VERSION "HNPBNNNYNNNNNNNNNNNNNNNNNNNNNNNNYNYYYYYYYY>4>%%%/4>'%**4YYY///"

NS_ :

BS_:

BU_: RDF2 Air Vehicle_CAN MPC2

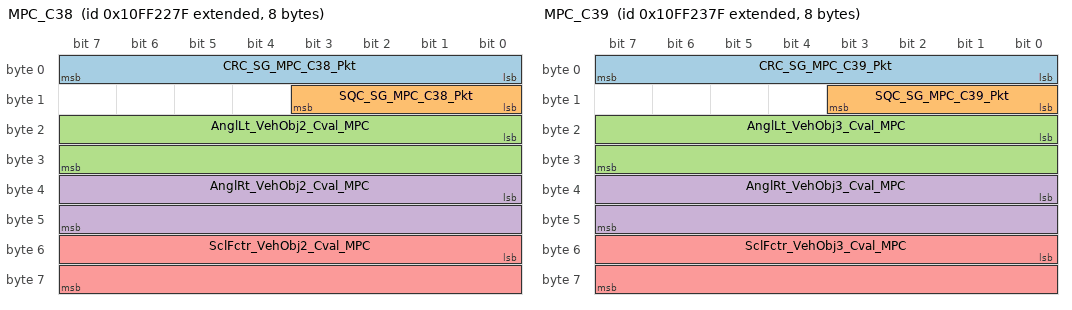
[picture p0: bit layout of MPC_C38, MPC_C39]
BO_ 2432639615 MPC_C38: 8 MPC2
 SG_ CRC_SG_MPC_C38_Pkt : 0|8@1+ (1,0) [0|255] "NoUnit" Vector__XXX
 SG_ SQC_SG_MPC_C38_Pkt : 8|4@1+ (1,0) [0|15] "NoUnit" Vector__XXX
 SG_ AnglLt_VehObj2_Cval_MPC : 16|16@1+ (0.00390625,-125) [-125|125] "°" Vector__XXX
 SG_ AnglRt_VehObj2_Cval_MPC : 32|16@1+ (0.00390625,-125) [-125|125] "°" Vector__XXX
 SG_ SclFctr_VehObj2_Cval_MPC : 48|16@1+ (6.25E-005,0.5) [0.5|4.5] "NoUnit" Vector__XXX

BO_ 2432639871 MPC_C39: 8 MPC2
 SG_ CRC_SG_MPC_C39_Pkt : 0|8@1+ (1,0) [0|255] "NoUnit" Vector__XXX
 SG_ SQC_SG_MPC_C39_Pkt : 8|4@1+ (1,0) [0|15] "NoUnit" Vector__XXX
 SG_ AnglLt_VehObj3_Cval_MPC : 16|16@1+ (0.00390625,-125) [-125|125] "°" Vector__XXX
 SG_ AnglRt_VehObj3_Cval_MPC : 32|16@1+ (0.00390625,-125) [-125|125] "°" Vector__XXX
 SG_ SclFctr_VehObj3_Cval_MPC : 48|16@1+ (6.25E-005,0.5) [0.5|4.5] "NoUnit" Vector__XXX

BO_ 2498756875 EBC1_BS: 8 Vehicle_CAN
 SG_ ABS_Actv_Stat : 4|2@1+ (1,0) [0|3] ""  MPC2
 SG_ BrkPdlPosn_Cval : 8|8@1+ (0.4,0) [0|100] "%"  MPC2

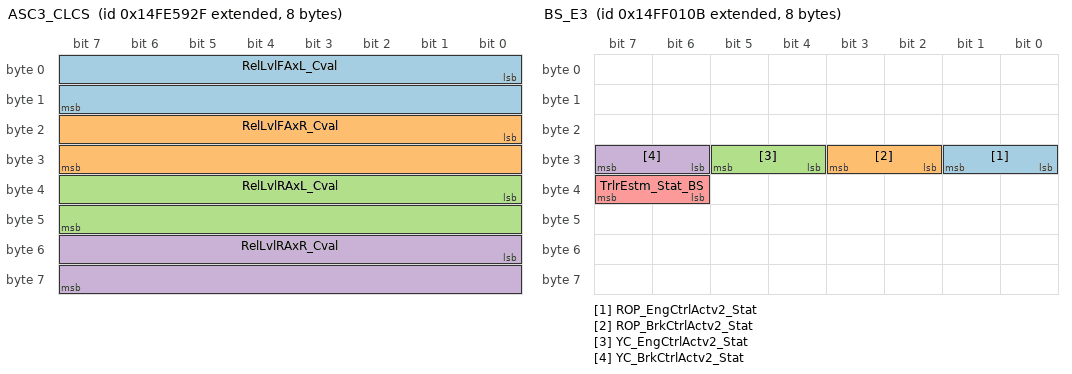
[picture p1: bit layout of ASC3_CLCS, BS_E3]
BO_ 2499696943 ASC3_CLCS: 8 Vehicle_CAN
 SG_ RelLvlFAxL_Cval : 0|16@1+ (0.1,-3200) [-3200|3225.5] "mm"  MPC2
 SG_ RelLvlFAxR_Cval : 16|16@1+ (0.1,-3200) [-3200|3225.5] "mm"  MPC2
 SG_ RelLvlRAxL_Cval : 32|16@1+ (0.1,-3200) [-3200|3225.5] "mm"  MPC2
 SG_ RelLvlRAxR_Cval : 48|16@1+ (0.1,-3200) [-3200|3225.5] "mm"  MPC2

BO_ 2499702539 ACC1_BS: 8 Vehicle_CAN
 SG_ RoadCurv_Cval : 32|16@1+ (0.0078125,-250) [-250|251.9921875] "1/km"  MPC2

BO_ 2499735808 CCVS1_CPC: 8 Vehicle_CAN
 SG_ VehSpd_Cval_CPC : 8|16@1+ (0.00390625,0) [0|250.99609375] "km/h"  MPC2
 SG_ CC_Actv_Stat : 24|2@1+ (1,0) [0|3] ""  MPC2

BO_ 2499739775 MPC_C02: 8 MPC2
 SG_ Rsrv_CRC_SG_MPC_C02_Pkt : 0|8@1+ (1,0) [0|255] "NoUnit" Vector__XXX
 SG_ Rsrv_SQC_SG_MPC_C02_Pkt : 8|4@1+ (1,0) [0|15] "NoUnit" Vector__XXX
 SG_ DispCloAA_Rq_MPC : 12|2@1+ (1,0) [0|3] "" Vector__XXX
 SG_ Lvl0_AA_Cval_MPC : 16|4@1+ (1,0) [0|15] "count(s)" Vector__XXX
 SG_ Lvl1_AA_Cval_MPC : 20|4@1+ (1,0) [0|15] "count(s)" Vector__XXX
 SG_ Lvl2_AA_Cval_MPC : 24|4@1+ (1,0) [0|15] "count(s)" Vector__XXX
 SG_ Lvl3_AA_Cval_MPC : 28|4@1+ (1,0) [0|15] "count(s)" Vector__XXX
 SG_ Lvl4_AA_Cval_MPC : 32|4@1+ (1,0) [0|15] "count(s)" Vector__XXX
 SG_ Lvl5_AA_Cval_MPC : 36|4@1+ (1,0) [0|15] "count(s)" Vector__XXX
 SG_ Lvl6_AA_Cval_MPC : 40|4@1+ (1,0) [0|15] "count(s)" Vector__XXX
 SG_ Lvl7_AA_Cval_MPC : 44|4@1+ (1,0) [0|15] "count(s)" Vector__XXX
 SG_ Lvl8_AA_Cval_MPC : 48|4@1+ (1,0) [0|15] "count(s)" Vector__XXX
 SG_ Lvl9_AA_Cval_MPC : 52|4@1+ (1,0) [0|15] "count(s)" Vector__XXX
 SG_ AA_Enbl_Stat_MPC : 56|2@1+ (1,0) [0|3] "" Vector__XXX
 SG_ AA_Fkt_Stat_MPC : 58|2@1+ (1,0) [0|3] "" Vector__XXX
 SG_ Warn0_AA_Rq_MPC : 60|2@1+ (1,0) [0|3] "" Vector__XXX
 SG_ Warn1_AA_Rq_MPC : 62|2@1+ (1,0) [0|3] "" Vector__XXX

BO_ 2499739915 BS_E3: 8 Vehicle_CAN
 SG_ ROP_EngCtrlActv2_Stat : 24|2@1+ (1,0) [0|3] ""  MPC2
 SG_ ROP_BrkCtrlActv2_Stat : 26|2@1+ (1,0) [0|3] ""  MPC2
 SG_ YC_EngCtrlActv2_Stat : 28|2@1+ (1,0) [0|3] ""  MPC2
 SG_ YC_BrkCtrlActv2_Stat : 30|2@1+ (1,0) [0|3] ""  MPC2
 SG_ TrlrEstm_Stat_BS : 38|2@1+ (1,0) [0|3] ""  MPC2

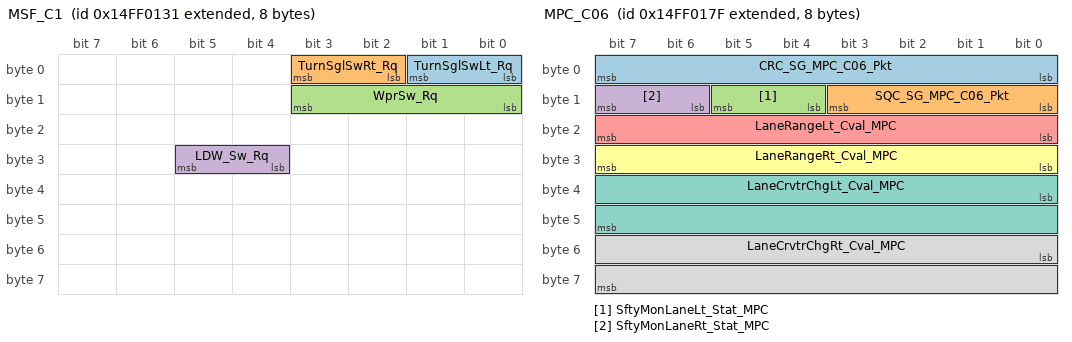
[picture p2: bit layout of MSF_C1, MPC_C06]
BO_ 2499739953 MSF_C1: 8 Vehicle_CAN
 SG_ TurnSglSwLt_Rq : 0|2@1+ (1,0) [0|3] ""  MPC2
 SG_ TurnSglSwRt_Rq : 2|2@1+ (1,0) [0|3] ""  MPC2
 SG_ WprSw_Rq : 8|4@1+ (1,0) [0|15] ""  MPC2
 SG_ LDW_Sw_Rq : 28|2@1+ (1,0) [0|3] ""  MPC2

BO_ 2499740031 MPC_C06: 8 MPC2
 SG_ CRC_SG_MPC_C06_Pkt : 0|8@1+ (1,0) [0|255] "NoUnit" Vector__XXX
 SG_ SQC_SG_MPC_C06_Pkt : 8|4@1+ (1,0) [0|15] "NoUnit" Vector__XXX
 SG_ SftyMonLaneLt_Stat_MPC : 12|2@1+ (1,0) [0|3] "" Vector__XXX
 SG_ SftyMonLaneRt_Stat_MPC : 14|2@1+ (1,0) [0|3] "" Vector__XXX
 SG_ LaneRangeLt_Cval_MPC : 16|8@1+ (0.5,0) [0|125] "m" Vector__XXX
 SG_ LaneRangeRt_Cval_MPC : 24|8@1+ (0.5,0) [0|125] "m" Vector__XXX
 SG_ LaneCrvtrChgLt_Cval_MPC : 32|16@1+ (0.0625,-2000) [-2000|2000] "1/km²" Vector__XXX
 SG_ LaneCrvtrChgRt_Cval_MPC : 48|16@1+ (0.0625,-2000) [-2000|2000] "1/km²" Vector__XXX

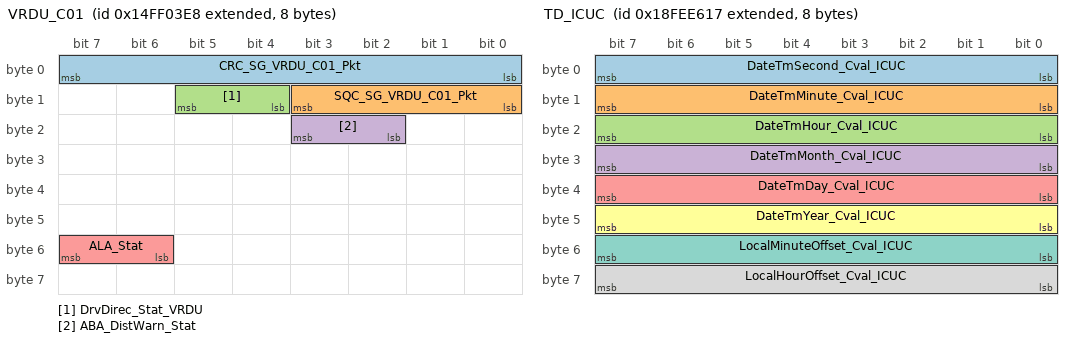
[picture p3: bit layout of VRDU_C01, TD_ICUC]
BO_ 2499740648 VRDU_C01: 8 Vehicle_CAN
 SG_ CRC_SG_VRDU_C01_Pkt : 0|8@1+ (1,0) [0|255] "NoUnit"  MPC2
 SG_ SQC_SG_VRDU_C01_Pkt : 8|4@1+ (1,0) [0|15] "NoUnit"  MPC2
 SG_ DrvDirec_Stat_VRDU : 12|2@1+ (1,0) [0|3] ""  MPC2
 SG_ ABA_DistWarn_Stat : 18|2@1+ (1,0) [0|3] ""  MPC2
 SG_ ALA_Stat : 54|2@1+ (1,0) [0|3] ""  MPC2

BO_ 2499740904 VRDU_C02: 8 Vehicle_CAN
 SG_ WhlBaseTrtr_Cval : 16|8@1+ (0.1,0) [0|25] "m"  MPC2

BO_ 2499742976 CPC3_E2: 8 Vehicle_CAN
 SG_ RetSwPos_Rq_STSR : 32|8@1+ (1,0) [0|255] ""  MPC2

BO_ 2565832698 APPL_SG_MPC: 8 Vehicle_CAN
 SG_ APPL_SG_MPC : 0|64@1+ (1,0) [0|0] ""  MPC2

BO_ 2565864063 SG_APPL_MPC: 8 MPC2
 SG_ SG_APPL_MPC : 0|64@1+ (1,0) [0|0] "" Vector__XXX

BO_ 2566809216 BM_BESO: 8 Vehicle_CAN
 SG_ BatMainSw_Stat : 0|2@1+ (1,0) [0|3] ""  MPC2

BO_ 2566841879 TD_ICUC: 8 Vehicle_CAN
 SG_ DateTmSecond_Cval_ICUC : 0|8@1+ (0.25,0) [0|59.75] "s"  MPC2
 SG_ DateTmMinute_Cval_ICUC : 8|8@1+ (1,0) [0|59] "min"  MPC2
 SG_ DateTmHour_Cval_ICUC : 16|8@1+ (1,0) [0|250] "h"  MPC2
 SG_ DateTmMonth_Cval_ICUC : 24|8@1+ (1,0) [1|12] "Months"  MPC2
 SG_ DateTmDay_Cval_ICUC : 32|8@1+ (0.25,0) [0.25|31.75] "Days"  MPC2
 SG_ DateTmYear_Cval_ICUC : 40|8@1+ (1,1985) [1985|2235] "Years"  MPC2
 SG_ LocalMinuteOffset_Cval_ICUC : 48|8@1+ (1,-125) [-59|59] "min"  MPC2
 SG_ LocalHourOffset_Cval_ICUC : 56|8@1+ (1,-125) [-23|23] "h"  MPC2

BO_ 2566845201 VP_IPPC: 8 Vehicle_CAN
 SG_ Latitude_Cval_IPPC : 0|32@1- (1E-007,-210) [-210|211.1081215] "°"  MPC2
 SG_ Longitude_Cval_IPPC : 32|32@1+ (1E-007,-210) [-210|211.1081215] "°"  MPC2

BO_ 2566845729 AMB_SCA: 8 Vehicle_CAN
 SG_ AirTempOutsd_Cval_SCA : 24|16@1+ (0.03125,-273) [-273|1734.96875] "°C"  MPC2

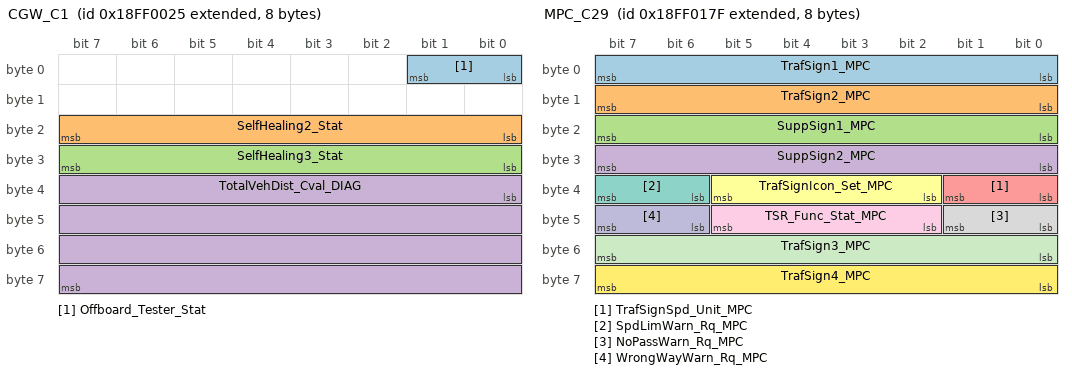
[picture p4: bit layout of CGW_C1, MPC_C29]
BO_ 2566848549 CGW_C1: 8 Vehicle_CAN
 SG_ Offboard_Tester_Stat : 0|2@1+ (1,0) [0|3] ""  MPC2
 SG_ SelfHealing2_Stat : 16|8@1+ (1,0) [0|254] "NoUnit"  MPC2
 SG_ SelfHealing3_Stat : 24|8@1+ (1,0) [0|254] "NoUnit"  MPC2
 SG_ TotalVehDist_Cval_DIAG : 32|32@1+ (0.125,0) [0|526385151.875] "km"  MPC2

BO_ 2566848791 ICUC_C4: 8 Vehicle_CAN
 SG_ TSR_MdSw_Rq : 0|2@1+ (1,0) [0|0] ""  MPC2

BO_ 2566848895 MPC_C29: 8 MPC2
 SG_ TrafSign1_MPC : 0|8@1+ (1,0) [1|254] "NoUnit" Vector__XXX
 SG_ TrafSign2_MPC : 8|8@1+ (1,0) [1|254] "NoUnit" Vector__XXX
 SG_ SuppSign1_MPC : 16|8@1+ (1,0) [1|254] "NoUnit" Vector__XXX
 SG_ SuppSign2_MPC : 24|8@1+ (1,0) [1|254] "NoUnit" Vector__XXX
 SG_ TrafSignSpd_Unit_MPC : 32|2@1+ (1,0) [0|3] "" Vector__XXX
 SG_ TrafSignIcon_Set_MPC : 34|4@1+ (1,0) [0|14] "NoUnit" Vector__XXX
 SG_ SpdLimWarn_Rq_MPC : 38|2@1+ (1,0) [0|3] "" Vector__XXX
 SG_ NoPassWarn_Rq_MPC : 40|2@1+ (1,0) [0|3] "" Vector__XXX
 SG_ TSR_Func_Stat_MPC : 42|4@1+ (1,0) [0|15] "" Vector__XXX
 SG_ WrongWayWarn_Rq_MPC : 46|2@1+ (1,0) [0|3] "" Vector__XXX
 SG_ TrafSign3_MPC : 48|8@1+ (1,0) [1|254] "NoUnit" Vector__XXX
 SG_ TrafSign4_MPC : 56|8@1+ (1,0) [1|254] "NoUnit" Vector__XXX

BO_ 2566849047 ICUC_C6: 8 Vehicle_CAN
 SG_ AA_Stat_ICUC : 2|2@1+ (1,0) [0|3] ""  MPC2
 SG_ LDWS_FailWarnDev_Stat_ICUC : 8|4@1+ (1,0) [0|15] ""  MPC2

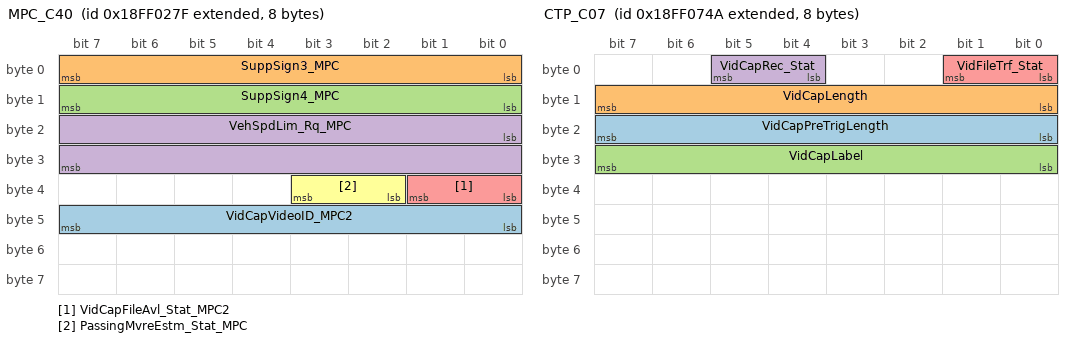
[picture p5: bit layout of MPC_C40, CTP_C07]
BO_ 2566849151 MPC_C40: 8 MPC2
 SG_ VidCapVideoID_MPC2 : 40|8@1+ (1,0) [0|255] "" Vector__XXX
 SG_ SuppSign3_MPC : 0|8@1+ (1,0) [1|254] "NoUnit" Vector__XXX
 SG_ SuppSign4_MPC : 8|8@1+ (1,0) [1|254] "NoUnit" Vector__XXX
 SG_ VehSpdLim_Rq_MPC : 16|16@1+ (0.00390625,0) [0|250.99609375] "km/h" Vector__XXX
 SG_ VidCapFileAvl_Stat_MPC2 : 32|2@1+ (1,0) [0|3] "" Vector__XXX
 SG_ PassingMvreEstm_Stat_MPC : 34|2@1+ (1,0) [0|3] "" Vector__XXX

BO_ 2566850337 SCA_E1: 8 Vehicle_CAN
 SG_ RainSensOpMod_Stat : 14|2@1+ (1,0) [0|3] ""  MPC2
 SG_ RainSensSensitivity_Stat : 32|4@1+ (1,0) [0|15] ""  MPC2

BO_ 2566850378 CTP_C07: 8 Vehicle_CAN
 SG_ VidCapPreTrigLength : 16|8@1+ (1,0) [0|180] "s" Vector__XXX
 SG_ VidCapLength : 8|8@1+ (1,0) [0|180] "s" Vector__XXX
 SG_ VidCapLabel : 24|8@1+ (1,0) [0|255] "" Vector__XXX
 SG_ VidCapRec_Stat : 4|2@1+ (1,0) [0|3] "" Vector__XXX
 SG_ VidFileTrf_Stat : 0|2@1+ (1,0) [0|3] ""  MPC2

BO_ 2566850593 SCA_C08: 8 Vehicle_CAN
 SG_ WprSpd_Stat : 34|2@1+ (1,0) [0|3] ""  MPC2

BO_ 2566851873 SAM_B01: 8 Vehicle_CAN
 SG_ LDWS_FailWarnDev_Stat_SAM : 20|4@1+ (1,0) [0|15] ""  MPC2

BO_ 2566860172 MUX3_B39: 8 Vehicle_CAN
 SG_ LDWS_FailWarnDev_Stat_MUX3 : 0|4@1+ (1,0) [0|15] ""  MPC2

BO_ 2566881280 NM_MPC: 8 Vehicle_CAN
 SG_ NM_Mode : 0|8@1+ (1,0) [0|255] ""  MPC2
 SG_ NM_Successor : 8|8@1+ (1,0) [0|255] "NoUnit"  MPC2
 SG_ NM_Ud_Launch : 16|6@1+ (1,0) [0|63] ""  MPC2
 SG_ NM_Sleep_Ack : 22|1@1+ (1,0) [0|1] ""  MPC2
 SG_ NM_Sleep_Ind : 23|1@1+ (1,0) [0|1] ""  MPC2
 SG_ NM_Ud_Srv M : 24|8@1+ (1,0) [0|255] ""  MPC2
 SG_ WakeupRsn_MPC m2 : 32|8@1+ (1,0) [0|255] ""  MPC2
 SG_ Awake_NwSt m15 : 32|1@1+ (1,0) [0|1] ""  MPC2
 SG_ Awake_Diag_Actv m15 : 33|1@1+ (1,0) [0|1] ""  MPC2
 SG_ Awake_IgnOn m15 : 34|1@1+ (1,0) [0|1] ""  MPC2
 SG_ Awake_XCP_Diag m15 : 36|1@1+ (1,0) [0|1] ""  MPC2
 SG_ Awake_VC_TrfData m15 : 37|1@1+ (1,0) [0|1] ""  MPC2
 SG_ WakeupCnt_cv m2 : 40|8@1+ (1,0) [0|254] "NoUnit"  MPC2
 SG_ Nw_Id : 56|8@1+ (1,0) [0|255] ""  MPC2

BO_ 2564488575 TPA_MPC_2_DTP: 8 MPC2
 SG_ TPA_MPC_2_DTP : 0|8@1+ (1,0) [0|0] "" Vector__XXX

BO_ 2564483199 TPA_MPC_2_VRDU2: 8 MPC2
 SG_ TPA_MPC_2_VRDU2 : 0|8@1+ (1,0) [0|0] "" Vector__XXX

BO_ 2564482431 TPA_MPC_2_CDS: 8 MPC2
 SG_ TPA_MPC_2_CDS : 0|8@1+ (1,0) [0|0] "" Vector__XXX

BO_ 2564429695 TPA_DIAG_RS_MPC_IC_17: 8 MPC2
 SG_ TPA_DIAG_RS_MPC_IC_17 : 0|8@1+ (1,0) [0|0] "" Vector__XXX

BO_ 2564487807 DIAG_RS_MPC_FA_250: 8 MPC2
 SG_ DIAG_RS_MPC_FA_250 : 0|8@1+ (1,0) [0|0] "" Vector__XXX

BO_ 2564487551 DIAG_RS_MPC_F9_249: 8 MPC2
 SG_ DIAG_RS_MPC_F9_249 : 0|8@1+ (1,0) [0|0] "" Vector__XXX

BO_ 2564487295 DIAG_RS_MPC_F8_248: 8 MPC2
 SG_ DIAG_RS_MPC_F8_248 : 0|8@1+ (1,0) [0|0] "" Vector__XXX

BO_ 2564485759 DIAG_RS_MPC_F2_242: 8 MPC2
 SG_ DIAG_RS_MPC_F2_242 : 0|8@1+ (1,0) [0|0] "" Vector__XXX

BO_ 2566881407 NM_MPC_Tx: 8 MPC2
 SG_ NM_Mode : 0|8@1+ (1,0) [0|0] "" Vector__XXX
 SG_ NM_Successor : 8|8@1+ (1,0) [0|63] "NoUnit" Vector__XXX
 SG_ NM_Ud_Launch : 16|6@1+ (1,0) [0|0] "" Vector__XXX
 SG_ NM_Sleep_Ack : 22|1@1+ (1,0) [0|0] "" Vector__XXX
 SG_ NM_Sleep_Ind : 23|1@1+ (1,0) [0|0] "" Vector__XXX
 SG_ NM_Ud_Srv M : 24|8@1+ (1,0) [0|0] "" Vector__XXX
 SG_ WakeupRsn_MPC m2 : 32|8@1+ (1,0) [0|0] "" Vector__XXX
 SG_ Awake_NwSt m15 : 32|1@1+ (1,0) [0|0] "" Vector__XXX
 SG_ Awake_Diag_Actv m15 : 33|1@1+ (1,0) [0|0] "" Vector__XXX
 SG_ Awake_IgnOn m15 : 34|1@1+ (1,0) [0|0] "" Vector__XXX
 SG_ Awake_XCP_Diag m15 : 36|1@1+ (1,0) [0|0] "" Vector__XXX
 SG_ Awake_VC_TrfData m15 : 37|1@1+ (1,0) [0|0] "" Vector__XXX
 SG_ WakeupCnt_cv m2 : 40|8@1+ (1,0) [0|254] "NoUnit" Vector__XXX
 SG_ Nw_Id : 56|8@1+ (1,0) [0|0] "" Vector__XXX

BO_ 2564456433 BoschVideoDiagPhyRequ: 8 Vehicle_CAN
 SG_ BoschVideoDiagPhyRequ : 0|64@1+ (1,0) [0|0] ""  MPC2

BO_ 2564554737 BoschVideoDiagFuncRequ: 8 Vehicle_CAN
 SG_ BoschVideoDiagFuncRequ : 0|64@1+ (1,0) [0|0] ""  MPC2

BO_ 2564554746 DIAG_RQ_GLOBAL_UDS_FA_250: 8 Vehicle_CAN
 SG_ DIAG_RQ_GLOBAL_UDS_FA_250 : 0|8@1+ (1,0) [0|0] ""  MPC2

BO_ 2564554745 DIAG_RQ_GLOBAL_UDS_F9_249: 8 Vehicle_CAN
 SG_ DIAG_RQ_GLOBAL_UDS_F9_249 : 0|8@1+ (1,0) [0|0] ""  MPC2

BO_ 2564554744 DIAG_RQ_GLOBAL_UDS_F8_248: 8 Vehicle_CAN
 SG_ DIAG_RQ_GLOBAL_UDS_F8_248 : 0|8@1+ (1,0) [0|0] ""  MPC2

BO_ 2564554738 DIAG_RQ_GLOBAL_UDS_F2_242: 8 Vehicle_CAN
 SG_ DIAG_RQ_GLOBAL_UDS_F2_242 : 0|8@1+ (1,0) [0|0] ""  MPC2

BO_ 2564456442 DIAG_RQ_MPC_FA_250: 8 Vehicle_CAN
 SG_ DIAG_RQ_MPC_FA_250 : 0|8@1+ (1,0) [0|0] ""  MPC2

BO_ 2564456441 DIAG_RQ_MPC_F9_249: 8 Vehicle_CAN
 SG_ DIAG_RQ_MPC_F9_249 : 0|8@1+ (1,0) [0|0] ""  MPC2

BO_ 2564456440 DIAG_RQ_MPC_F8_248: 8 Vehicle_CAN
 SG_ DIAG_RQ_MPC_F8_248 : 0|8@1+ (1,0) [0|0] ""  MPC2

BO_ 2564456434 DIAG_RQ_MPC_F2_242: 8 Vehicle_CAN
 SG_ DIAG_RQ_MPC_F2_242 : 0|8@1+ (1,0) [0|0] ""  MPC2

BO_ 2564456424 TPA_VRDU2_2_MPC: 8 Vehicle_CAN
 SG_ TPA_VRDU2_2_MPC : 0|8@1+ (1,0) [0|0] ""  MPC2

BO_ 2564456445 TPA_DTP_2_MPC: 8 Vehicle_CAN
 SG_ TPA_DTP_2_MPC : 0|8@1+ (1,0) [0|0] ""  MPC2

BO_ 2564456215 TPA_DIAG_RQ_MPC_IC_17: 8 Vehicle_CAN
 SG_ TPA_DIAG_RQ_MPC_IC_17 : 0|8@1+ (1,0) [0|0] ""  MPC2

BO_ 2564456421 TPA_CDS_2_MPC: 8 Vehicle_CAN
 SG_ TPA_CDS_2_MPC : 0|8@1+ (1,0) [0|0] ""  MPC2

BO_ 2564485503 BoschVideoDiagResp: 8 MPC2
 SG_ BoschVideoDiagResp : 0|64@1+ (1,0) [0|0] "" Vector__XXX

BO_ 2566897701 CGW_GVC1: 8 Vehicle_CAN
 SG_ GVC_VehBrand : 0|4@1+ (1,0) [0|15] ""  MPC2
 SG_ GVC_VehModel : 4|4@1+ (1,0) [0|15] ""  MPC2

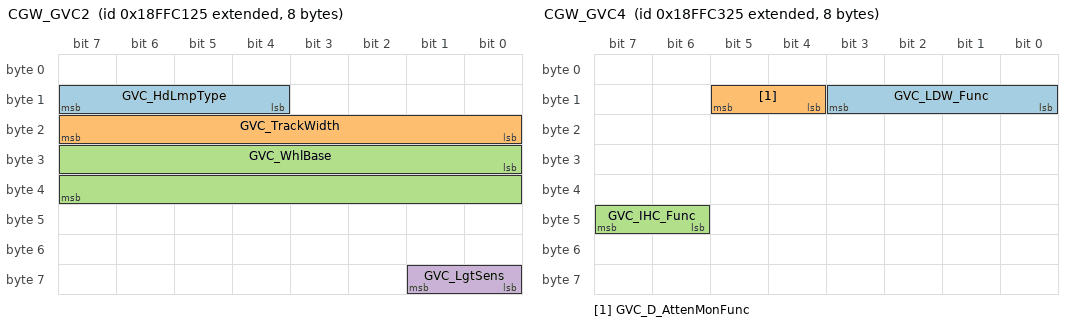
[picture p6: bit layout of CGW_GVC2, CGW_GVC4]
BO_ 2566897957 CGW_GVC2: 8 Vehicle_CAN
 SG_ GVC_HdLmpType : 12|4@1+ (1,0) [0|15] ""  MPC2
 SG_ GVC_TrackWidth : 16|8@1+ (10,1500) [1500|3000] "mm"  MPC2
 SG_ GVC_WhlBase : 24|16@1+ (10,2000) [2000|13000] "mm"  MPC2
 SG_ GVC_LgtSens : 56|2@1+ (1,0) [0|3] ""  MPC2

BO_ 2566898469 CGW_GVC4: 8 Vehicle_CAN
 SG_ GVC_LDW_Func : 8|4@1+ (1,0) [0|15] ""  MPC2
 SG_ GVC_D_AttenMonFunc : 12|2@1+ (1,0) [0|3] ""  MPC2
 SG_ GVC_IHC_Func : 46|2@1+ (1,0) [0|3] ""  MPC2

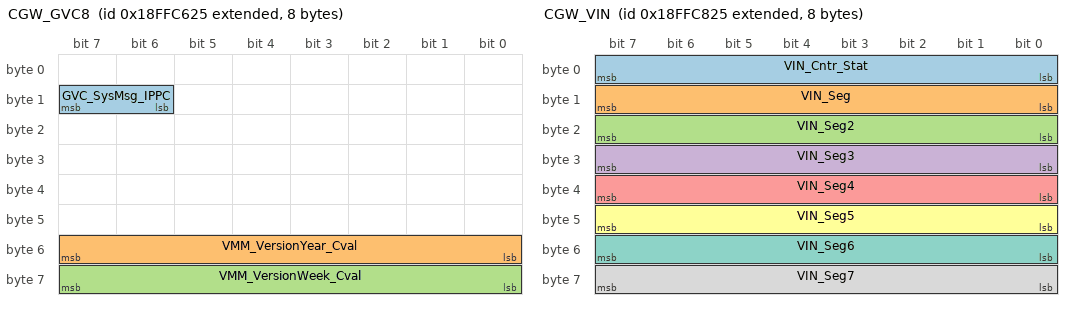
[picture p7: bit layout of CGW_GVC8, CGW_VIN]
BO_ 2566899237 CGW_GVC8: 8 Vehicle_CAN
 SG_ GVC_SysMsg_IPPC : 14|2@1+ (1,0) [0|3] ""  MPC2
 SG_ VMM_VersionYear_Cval : 48|8@1+ (1,1985) [1985|2235] "Years"  MPC2
 SG_ VMM_VersionWeek_Cval : 56|8@1+ (1,1) [1|52] "Weeks"  MPC2

BO_ 2566899493 CGW_GVC6: 8 Vehicle_CAN
 SG_ GVC_TSR_Fct : 60|4@1+ (1,0) [0|15] ""  MPC2

BO_ 2566899749 CGW_VIN: 8 Vehicle_CAN
 SG_ VIN_Cntr_Stat : 0|8@1+ (1,0) [0|255] "NoUnit"  MPC2
 SG_ VIN_Seg : 8|8@1+ (1,0) [1|254] "NoUnit"  MPC2
 SG_ VIN_Seg2 : 16|8@1+ (1,0) [1|254] "NoUnit"  MPC2
 SG_ VIN_Seg3 : 24|8@1+ (1,0) [1|254] "NoUnit"  MPC2
 SG_ VIN_Seg4 : 32|8@1+ (1,0) [1|254] "NoUnit"  MPC2
 SG_ VIN_Seg5 : 40|8@1+ (1,0) [1|254] "NoUnit"  MPC2
 SG_ VIN_Seg6 : 48|8@1+ (1,0) [1|254] "NoUnit"  MPC2
 SG_ VIN_Seg7 : 56|8@1+ (1,0) [1|254] "NoUnit"  MPC2

BO_ 2566900261 CGW_GVC10: 8 Vehicle_CAN
 SG_ SteerRatioCntr_Cval : 0|8@1+ (1,0) [0|254] "NoUnit"  MPC2
 SG_ SteerRatioNodesCntr_Cval : 8|4@1+ (1,0) [0|14] "count(s)"  MPC2
 SG_ SteerRatioAnglType_Stat : 12|2@1+ (1,0) [0|3] ""  MPC2
 SG_ SteerRatioMS_Stat M : 14|2@1+ (1,0) [0|3] ""  MPC2
 SG_ FirstNdCntX_SteerRatio_Cval : 16|8@1+ (0.2,0) [0|50] "NoUnit"  MPC2
 SG_ SecNdCntX_SteerRatio_Cval : 24|8@1+ (0.2,0) [0|50] "NoUnit"  MPC2
 SG_ FirstNdCntX_AnglDeg_Cval m0 : 32|16@1+ (1,-2500) [-2500|2500] "°"  MPC2
 SG_ FirstNdCntX_AnglRad_Cval m1 : 32|16@1+ (0.01,-50) [-50|50] "rad"  MPC2
 SG_ SecNdCntX_AnglDeg_Cval m0 : 48|16@1+ (1,-2500) [-2500|2500] "°"  MPC2
 SG_ SecNdCntX_AnglRad_Cval m1 : 48|16@1+ (0.01,-50) [-50|50] "rad"  MPC2

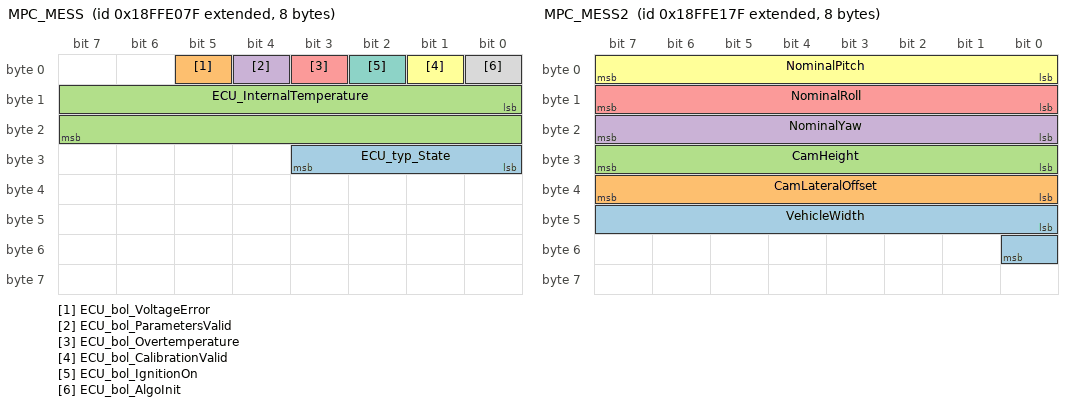
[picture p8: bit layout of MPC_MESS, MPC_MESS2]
BO_ 2566905983 MPC_MESS: 8 MPC2
 SG_ ECU_typ_State : 24|4@1+ (1,0) [0|15] "" Vector__XXX
 SG_ ECU_bol_VoltageError : 5|1@1+ (1,0) [0|1] "" Vector__XXX
 SG_ ECU_InternalTemperature : 8|16@1+ (-0.06,195) [-52|195] "degreesC" Vector__XXX
 SG_ ECU_bol_ParametersValid : 4|1@1+ (1,0) [0|1] "" Vector__XXX
 SG_ ECU_bol_Overtemperature : 3|1@1+ (1,0) [0|1] "" Vector__XXX
 SG_ ECU_bol_CalibrationValid : 1|1@1+ (1,0) [0|1] "" Vector__XXX
 SG_ ECU_bol_IgnitionOn : 2|1@1+ (1,0) [0|1] "" Vector__XXX
 SG_ ECU_bol_AlgoInit : 0|1@1+ (1,0) [0|1] "" Vector__XXX

BO_ 2566906239 MPC_MESS2: 8 MPC2
 SG_ VehicleWidth : 40|9@1+ (0.01,1) [1|6.11] "m" Vector__XXX
 SG_ CamLateralOffset : 32|8@1+ (0.01,-0.5) [-0.5|0.5] "m" Vector__XXX
 SG_ CamHeight : 24|8@1+ (0.01,1) [1|3.5] "m" Vector__XXX
 SG_ NominalYaw : 16|8@1+ (0.1,-10) [-10|10] "°" Vector__XXX
 SG_ NominalRoll : 8|8@1+ (0.1,-10) [-10|10] "°" Vector__XXX
 SG_ NominalPitch : 0|8@1+ (0.1,-5) [-5|20] "°" Vector__XXX

BO_ 2566906495 MPC_MESS3: 8 MPC2
 SG_ VC_PriorityTrigger : 0|9@1+ (1,0) [0|511] "" Vector__XXX
 SG_ VC_TestTrigger_ACT : 21|1@1+ (1,0) [0|1] "" Vector__XXX
 SG_ VC_VEHSPDTrigger_ACT : 19|1@1+ (1,0) [0|1] "" Vector__XXX
 SG_ VC_MDASWarnTrigger_ACT : 25|1@1+ (1,0) [0|1] "" Vector__XXX
 SG_ VC_RSC_ESC_ABS_Trigger_ACT : 23|1@1+ (1,0) [0|1] "" Vector__XXX
 SG_ VC_YAWTrigger_ACT : 17|1@1+ (1,0) [0|1] "" Vector__XXX
 SG_ VC_HardBreakTrigger_ACT : 29|1@1+ (1,0) [0|1] "" Vector__XXX
 SG_ VC_EBTrigger_ACT : 33|1@1+ (1,0) [0|1] "" Vector__XXX
 SG_ VC_HapticTrigger_ACT : 31|1@1+ (1,0) [0|1] "" Vector__XXX
 SG_ VC_ManualTrigger_ACT : 27|1@1+ (1,0) [0|1] "" Vector__XXX
 SG_ VC_TestTrigger_EN : 20|1@1+ (1,0) [0|1] "" Vector__XXX
 SG_ VC_VEHSPDTrigger_EN : 18|1@1+ (1,0) [0|1] "" Vector__XXX
 SG_ VC_MDASWarnTrigger_EN : 24|1@1+ (1,0) [0|1] "" Vector__XXX
 SG_ VC_RSC_ESC_ABSTrigger_EN : 22|1@1+ (1,0) [0|1] "" Vector__XXX
 SG_ VC_YAWTrigger_EN : 16|1@1+ (1,0) [0|1] "" Vector__XXX
 SG_ VC_HardBreakTrigger_EN : 28|1@1+ (1,0) [0|1] "" Vector__XXX
 SG_ VC_EBTrigger_EN : 32|1@1+ (1,0) [0|1] "" Vector__XXX
 SG_ VC_HapticTrigger_EN : 30|1@1+ (1,0) [0|1] "" Vector__XXX
 SG_ VC_ManualTrigger_EN : 26|1@1+ (1,0) [0|1] "" Vector__XXX

BO_ 2566906751 MPC_MESS4: 8 MPC2
 SG_ SerialNumber5 m0 : 48|8@1+ (1,0) [0|255] "" Vector__XXX
 SG_ MPC_SW_PatchLevel m2 : 24|8@1+ (1,0) [0|255] "" Vector__XXX
 SG_ MPC_HW_Year m2 : 32|8@1+ (1,0) [0|255] "" Vector__XXX
 SG_ MPC_HW_Week m2 : 40|8@1+ (1,0) [0|255] "" Vector__XXX
 SG_ MPC_HW_PatchLevel m2 : 48|8@1+ (1,0) [0|255] "" Vector__XXX
 SG_ MDASYear m4 : 32|8@1+ (1,0) [0|255] "" Vector__XXX
 SG_ MDASWeek m4 : 40|8@1+ (1,0) [0|255] "" Vector__XXX
 SG_ MDASPatchLevel m4 : 48|8@1+ (1,0) [0|255] "" Vector__XXX
 SG_ LDWSubVersion m3 : 16|8@1+ (1,0) [0|255] "" Vector__XXX
 SG_ SerialNumber12 m1 : 48|8@1+ (1,0) [0|255] "" Vector__XXX
 SG_ SerialNumber11 m1 : 40|8@1+ (1,0) [0|255] "" Vector__XXX
 SG_ SerialNumber10 m1 : 32|8@1+ (1,0) [0|255] "" Vector__XXX
 SG_ SerialNumber9 m1 : 24|8@1+ (1,0) [0|255] "" Vector__XXX
 SG_ SerialNumber8 m1 : 16|8@1+ (1,0) [0|255] "" Vector__XXX
 SG_ SerialNumber4 m0 : 40|8@1+ (1,0) [0|255] "" Vector__XXX
 SG_ SerialNumber3 m0 : 32|8@1+ (1,0) [0|255] "" Vector__XXX
 SG_ SerialNumber2 m0 : 24|8@1+ (1,0) [0|255] "" Vector__XXX
 SG_ SerialNumber6 m0 : 56|8@1+ (1,0) [0|255] "" Vector__XXX
 SG_ SerialNumber1 m0 : 16|8@1+ (1,0) [0|255] "" Vector__XXX
 SG_ MPC_SW_Week m2 : 16|8@1+ (1,0) [0|255] "" Vector__XXX
 SG_ LDWPatchLevel m3 : 24|8@1+ (1,0) [0|255] "" Vector__XXX
 SG_ SerialNumber7 m1 : 8|8@1+ (1,0) [0|255] "" Vector__XXX
 SG_ SerialNumber0 m0 : 8|8@1+ (1,0) [0|255] "" Vector__XXX
 SG_ MPC_SW_Year m2 : 8|8@1+ (1,0) [0|255] "" Vector__XXX
 SG_ LDWMainVersion m3 : 8|8@1+ (1,0) [0|255] "" Vector__XXX
 SG_ MultiplexorECUInfo M : 0|8@1+ (1,0) [0|15] "" Vector__XXX

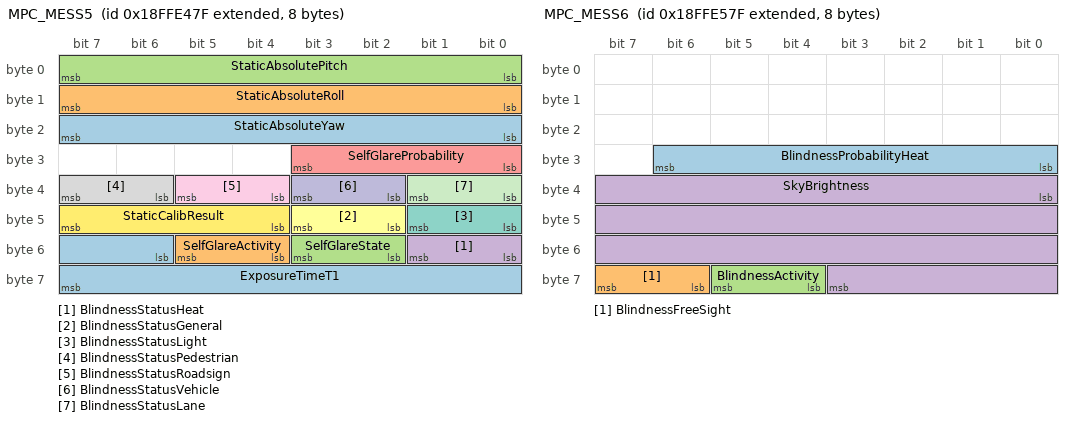
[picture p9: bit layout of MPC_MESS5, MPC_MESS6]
BO_ 2566907007 MPC_MESS5: 8 MPC2
 SG_ ExposureTimeT1 : 54|10@1+ (543,0) [0|555489] "" Vector__XXX
 SG_ SelfGlareActivity : 52|2@1+ (1,0) [0|1] "" Vector__XXX
 SG_ SelfGlareState : 50|2@1+ (1,0) [0|1] "" Vector__XXX
 SG_ BlindnessStatusHeat : 48|2@1+ (1,0) [0|3] "" Vector__XXX
 SG_ SelfGlareProbability : 24|4@1+ (0.1,0) [0|1.5] "" Vector__XXX
 SG_ BlindnessStatusGeneral : 42|2@1+ (1,0) [0|3] "" Vector__XXX
 SG_ BlindnessStatusLight : 40|2@1+ (1,0) [0|3] "" Vector__XXX
 SG_ BlindnessStatusPedestrian : 38|2@1+ (1,0) [0|3] "" Vector__XXX
 SG_ BlindnessStatusRoadsign : 36|2@1+ (1,0) [0|3] "" Vector__XXX
 SG_ BlindnessStatusVehicle : 34|2@1+ (1,0) [0|3] "" Vector__XXX
 SG_ BlindnessStatusLane : 32|2@1+ (1,0) [0|3] "" Vector__XXX
 SG_ StaticCalibResult : 44|4@1+ (1,0) [0|15] "" Vector__XXX
 SG_ StaticAbsoluteYaw : 16|8@1+ (0.1,-10) [-10|10] "°" Vector__XXX
 SG_ StaticAbsoluteRoll : 8|8@1+ (0.1,-10) [-10|10] "°" Vector__XXX
 SG_ StaticAbsolutePitch : 0|8@1+ (0.1,-5) [-5|20] "°" Vector__XXX

BO_ 2566907263 MPC_MESS6: 8 MPC2
 SG_ BlindnessProbabilityHeat : 24|7@1+ (0.1,-0.1) [0|15] "" Vector__XXX
 SG_ BlindnessFreeSight : 62|2@1+ (1,0) [0|3] "" Vector__XXX
 SG_ BlindnessActivity : 60|2@1+ (1,0) [0|3] "" Vector__XXX
 SG_ SkyBrightness : 32|28@1+ (0.0006283,0) [0|207000000] "Lux" Vector__XXX

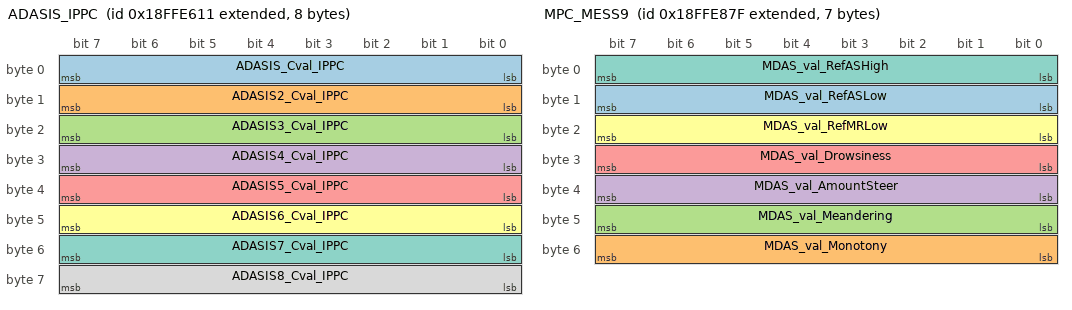
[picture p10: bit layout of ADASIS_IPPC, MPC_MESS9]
BO_ 2566907409 ADASIS_IPPC: 8 Vehicle_CAN
 SG_ ADASIS_Cval_IPPC : 0|8@1+ (1,0) [0|255] "NoUnit"  MPC2
 SG_ ADASIS2_Cval_IPPC : 8|8@1+ (1,0) [0|255] "NoUnit"  MPC2
 SG_ ADASIS3_Cval_IPPC : 16|8@1+ (1,0) [0|255] "NoUnit"  MPC2
 SG_ ADASIS4_Cval_IPPC : 24|8@1+ (1,0) [0|255] "NoUnit"  MPC2
 SG_ ADASIS5_Cval_IPPC : 32|8@1+ (1,0) [0|255] "NoUnit"  MPC2
 SG_ ADASIS6_Cval_IPPC : 40|8@1+ (1,0) [0|255] "NoUnit"  MPC2
 SG_ ADASIS7_Cval_IPPC : 48|8@1+ (1,0) [0|255] "NoUnit"  MPC2
 SG_ ADASIS8_Cval_IPPC : 56|8@1+ (1,0) [0|255] "NoUnit"  MPC2

BO_ 2566907519 MPC_MESS7: 8 MPC2
 SG_ FrameNumber : 0|32@1+ (1,0) [0|4294967295] "" Vector__XXX
 SG_ ExposureTime : 32|32@1+ (0.1,0) [0|429496729.5] "ms" Vector__XXX

BO_ 2566907775 MPC_MESS8: 8 MPC2
 SG_ BlindnessProbabilityGeneral : 60|4@1+ (0.1,-0.1) [0|15] "" Vector__XXX
 SG_ BlindnessProbabilityLight : 56|4@1+ (0.1,-0.1) [0|15] "" Vector__XXX
 SG_ BlindnessProbabilityPedestrian : 52|4@1+ (0.1,-0.1) [0|15] "" Vector__XXX
 SG_ BlindnessProbabilityRoadsign : 48|4@1+ (0.1,-0.1) [0|15] "" Vector__XXX
 SG_ BlindnessProbabilityVehicle : 43|4@1+ (0.1,-0.1) [0|15] "" Vector__XXX
 SG_ BlindnessDominantCause : 40|3@1+ (1,0) [0|7] "" Vector__XXX
 SG_ BlindnessProbabilityLane : 20|4@1+ (0.1,-0.1) [0|15] "" Vector__XXX
 SG_ BlindnessPermanent : 19|1@1+ (1,0) [0|1] "" Vector__XXX
 SG_ BlindnessErrorSource : 24|15@1+ (1,0) [0|32767] "" Vector__XXX
 SG_ BlindnessErrorState : 16|3@1+ (1,0) [0|7] "" Vector__XXX
 SG_ MDAS_bol_LDWSuppress : 11|1@1+ (1,0) [0|1] "" Vector__XXX
 SG_ MDAS_bol_LDWReactivate : 10|1@1+ (1,0) [0|1] "" Vector__XXX
 SG_ MDAS_bol_NoLCJumpActiveDel : 8|1@1+ (1,0) [0|1] "" Vector__XXX
 SG_ MDAS_bol_NoLaneChangeDel : 7|1@1+ (1,0) [0|1] "" Vector__XXX
 SG_ MDAS_bol_LaneWidthValid : 6|1@1+ (1,0) [0|1] "" Vector__XXX
 SG_ MDAS_bol_LaneInputsValid : 5|1@1+ (1,0) [0|1] "" Vector__XXX
 SG_ MDAS_bol_DriverActivity : 4|1@1+ (1,0) [0|1] "" Vector__XXX
 SG_ MDAS_bol_RefValCalc : 3|1@1+ (1,0) [0|1] "" Vector__XXX
 SG_ MDAS_bol_MRValid : 2|1@1+ (1,0) [0|1] "" Vector__XXX
 SG_ MDAS_bol_DLValid : 1|1@1+ (1,0) [0|1] "" Vector__XXX
 SG_ MDAS_bol_ASValid : 0|1@1+ (1,0) [0|1] "" Vector__XXX

BO_ 2566908031 MPC_MESS9: 7 MPC2
 SG_ MDAS_val_RefASLow : 8|8@1+ (1.5,150) [150|500] "" Vector__XXX
 SG_ MDAS_val_Monotony : 48|8@1+ (0.5,0) [0|127] "" Vector__XXX
 SG_ MDAS_val_Meandering : 40|8@1+ (0.05,0) [0|12.7] "" Vector__XXX
 SG_ MDAS_val_AmountSteer : 32|8@1+ (4,0) [0|1016] "" Vector__XXX
 SG_ MDAS_val_Drowsiness : 24|8@1+ (0.02,0) [0|5.08] "" Vector__XXX
 SG_ MDAS_val_RefMRLow : 16|8@1+ (0.01,1) [1|3.54] "" Vector__XXX
 SG_ MDAS_val_RefASHigh : 0|8@1+ (1.5,500) [500|850] "" Vector__XXX

BO_ 2566908287 MPC_MESS10: 8 MPC2
 SG_ Supp_LateralSpeed : 53|1@1+ (1,0) [0|1] "" Vector__XXX
 SG_ Supp_Kickdown : 50|1@1+ (1,0) [0|1] "" Vector__XXX
 SG_ Supp_FaultRight : 46|1@1+ (1,0) [0|1] "" Vector__XXX
 SG_ Supp_FaultLeft : 45|1@1+ (1,0) [0|1] "" Vector__XXX
 SG_ Supp_BrakePedal : 39|1@1+ (1,0) [0|1] "" Vector__XXX
 SG_ VehObjectDetectionBuffer3 : 34|2@1+ (1,0) [0|3] "" Vector__XXX
 SG_ VehObjectDetectionBuffer2 : 32|2@1+ (1,0) [0|3] "" Vector__XXX
 SG_ VehObjectDetectionBuffer1 : 30|2@1+ (1,0) [0|3] "" Vector__XXX
 SG_ VehObjectDetectionBuffer0 : 28|2@1+ (1,0) [0|3] "" Vector__XXX
 SG_ Supp_AccelerationPedal : 36|1@1+ (1,0) [0|1] "" Vector__XXX
 SG_ PedObjectDetectionBuffer5 : 26|2@1+ (1,0) [0|3] "" Vector__XXX
 SG_ PedObjectDetectionBuffer4 : 24|2@1+ (1,0) [0|3] "" Vector__XXX
 SG_ PedObjectDetectionBuffer3 : 22|2@1+ (1,0) [0|3] "" Vector__XXX
 SG_ PedObjectDetectionBuffer2 : 20|2@1+ (1,0) [0|3] "" Vector__XXX
 SG_ PedObjectDetectionBuffer1 : 18|2@1+ (1,0) [0|3] "" Vector__XXX
 SG_ PedObjectDetectionBuffer0 : 16|2@1+ (1,0) [0|3] "" Vector__XXX
 SG_ LDW_bol_OnlyOptWarnRight : 13|1@1+ (1,0) [0|1] "" Vector__XXX
 SG_ LDW_bol_OnlyOptWarnLeft : 12|1@1+ (1,0) [0|1] "" Vector__XXX
 SG_ LDW_bol_NormalWarnRight : 11|1@1+ (1,0) [0|1] "" Vector__XXX
 SG_ LDW_bol_NormalWarnLeft : 10|1@1+ (1,0) [0|1] "" Vector__XXX
 SG_ LaneMarkerTypeRight : 8|2@1+ (1,0) [0|3] "" Vector__XXX
 SG_ LaneMarkerTypeLeft : 6|2@1+ (1,0) [0|3] "" Vector__XXX
 SG_ LaneColorTypeRight : 3|3@1+ (1,0) [0|7] "" Vector__XXX
 SG_ LaneColorTypeLeft : 0|3@1+ (1,0) [0|7] "" Vector__XXX

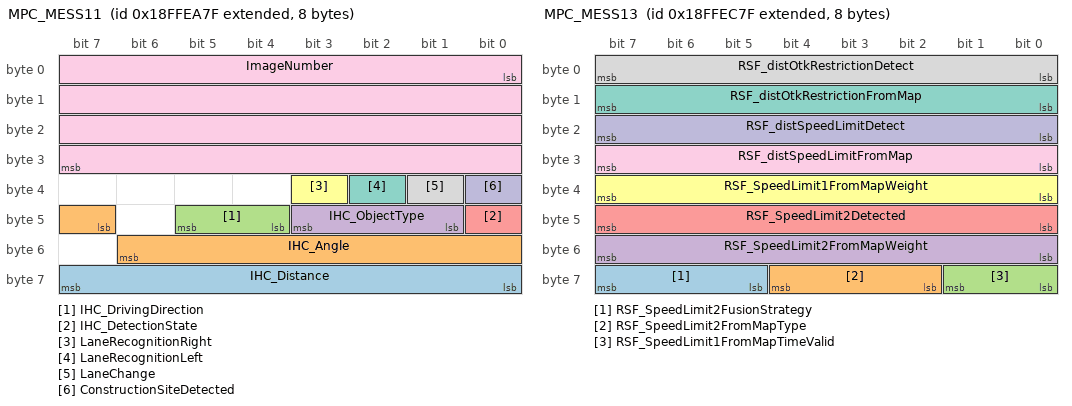
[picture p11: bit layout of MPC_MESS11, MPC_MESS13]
BO_ 2566908543 MPC_MESS11: 8 MPC2
 SG_ IHC_Distance : 56|8@1+ (2.5,0) [0|625] "m" Vector__XXX
 SG_ IHC_Angle : 47|8@1+ (0.2,-20) [-20|20] "deg" Vector__XXX
 SG_ IHC_DrivingDirection : 44|2@1+ (1,0) [0|2] "" Vector__XXX
 SG_ IHC_ObjectType : 41|3@1+ (1,0) [0|5] "" Vector__XXX
 SG_ IHC_DetectionState : 40|1@1+ (1,0) [0|1] "" Vector__XXX
 SG_ LaneRecognitionRight : 35|1@1+ (1,0) [0|1] "" Vector__XXX
 SG_ LaneRecognitionLeft : 34|1@1+ (1,0) [0|1] "" Vector__XXX
 SG_ LaneChange : 33|1@1+ (1,0) [0|1] "" Vector__XXX
 SG_ ImageNumber : 0|32@1+ (1,0) [0|4294967295] "" Vector__XXX
 SG_ ConstructionSiteDetected : 32|1@1+ (1,0) [0|1] "" Vector__XXX

BO_ 2566908799 MPC_MESS12: 8 MPC2
 SG_ RSF_SpeedLimit2VariableSpeedSign : 47|1@1+ (1,0) [0|1] "" Vector__XXX
 SG_ RSF_SpeedLimit2FromMapTimeValid : 54|2@1+ (1,0) [0|3] "" Vector__XXX
 SG_ RSF_SpeedLimit2DisplaySource : 62|2@1+ (1,0) [0|2] "" Vector__XXX
 SG_ RSF_SpeedLimit1VariableSpeedSign : 23|1@1+ (1,0) [0|1] "" Vector__XXX
 SG_ RSF_SpeedLimit1FromMapTimeDepend : 22|1@1+ (1,0) [0|1] "" Vector__XXX
 SG_ RSF_SpeedLimit1FromMap : 17|5@1+ (5,0) [0|155] "km/h" Vector__XXX
 SG_ RSF_OverSpeedWarningStatus : 50|1@1+ (1,0) [0|1] "" Vector__XXX
 SG_ RSF_OtkRestrictionWarningStatus : 51|1@1+ (1,0) [0|1] "" Vector__XXX
 SG_ RSF_OtkRestrictionFromMap : 52|1@1+ (1,0) [0|1] "" Vector__XXX
 SG_ RSF_SpeedLimit1DisplaySource : 43|2@1+ (1,0) [0|2] "" Vector__XXX
 SG_ RSF_SpeedLimit1Detected : 24|8@1+ (1,0) [0|255] "km/h" Vector__XXX
 SG_ RSF_SpeedLimit1FusionStrategy : 56|3@1+ (1,0) [0|7] "" Vector__XXX
 SG_ RSF_OperatingStatus : 40|3@1+ (1,0) [0|7] "" Vector__XXX
 SG_ RSF_OtkRestrictionDisplaySource : 45|2@1+ (1,0) [0|2] "" Vector__XXX
 SG_ RSF_OtkRestrictionDetected : 53|1@1+ (1,0) [0|1] "" Vector__XXX
 SG_ RSF_OtkFusionStrategy : 59|3@1+ (1,0) [0|7] "" Vector__XXX
 SG_ RSF_LastDetectedSignId : 0|8@1+ (1,0) [0|255] "" Vector__XXX
 SG_ RSF_LastDetectedQuality : 48|2@1+ (1,0) [0|2] "" Vector__XXX
 SG_ RSF_LastDetectedImgRow : 8|9@1+ (1,0) [0|512] "pixel" Vector__XXX
 SG_ RSF_LastDetectedAddId : 32|8@1+ (1,0) [0|255] "" Vector__XXX

BO_ 2566909055 MPC_MESS13: 8 MPC2
 SG_ RSF_SpeedLimit2FusionStrategy : 61|3@1+ (1,0) [0|7] "" Vector__XXX
 SG_ RSF_SpeedLimit2FromMapType : 58|3@1+ (1,0) [0|7] "" Vector__XXX
 SG_ RSF_SpeedLimit1FromMapTimeValid : 56|2@1+ (1,0) [0|3] "" Vector__XXX
 SG_ RSF_SpeedLimit2FromMapWeight : 48|8@1+ (0.5,0) [0|63] "tons" Vector__XXX
 SG_ RSF_SpeedLimit2Detected : 40|8@1+ (1,0) [0|255] "km/hr" Vector__XXX
 SG_ RSF_SpeedLimit1FromMapWeight : 32|8@1+ (0.5,0) [0|63] "tons" Vector__XXX
 SG_ RSF_distOtkRestrictionFromMap : 8|8@1+ (10,-1275) [-1275|1245] "m" Vector__XXX
 SG_ RSF_distOtkRestrictionDetect : 0|8@1+ (10,0) [0|2550] "m" Vector__XXX
 SG_ RSF_distSpeedLimitFromMap : 24|8@1+ (10,-1275) [-1275|1245] "m" Vector__XXX
 SG_ RSF_distSpeedLimitDetect : 16|8@1+ (10,0) [0|2550] "m" Vector__XXX

BO_ 2566909311 MPC_MESS14: 8 MPC2
 SG_ NextClassifierIdx : 61|3@1+ (1,0) [0|5] "" Vector__XXX
 SG_ RSF_SpeedLimit2FromMapTimeDepend : 55|1@1+ (1,0) [0|1] "" Vector__XXX
 SG_ RSF_SpeedLimit2FromMap : 56|5@1+ (5,0) [0|155] "km/h" Vector__XXX
 SG_ RSF_OtkRestrictionVehSpecific : 6|2@1+ (1,0) [0|3] "" Vector__XXX
 SG_ RSF_OtkRestrictionTimeSpecific : 14|2@1+ (1,0) [0|3] "" Vector__XXX
 SG_ RSF_OtkRestrictionCondition : 51|4@1+ (1,0) [0|15] "" Vector__XXX
 SG_ RSF_SpeedLimit2FromMapWeather : 48|3@1+ (1,0) [0|7] "" Vector__XXX
 SG_ RSF_SpeedLimit2FromMapHazGoods : 11|3@1+ (1,0) [0|7] "" Vector__XXX
 SG_ RSF_SpeedLimit1FromMapWeather : 8|3@1+ (1,0) [0|7] "" Vector__XXX
 SG_ RSF_SpeedLimit1FromMapHazGoods : 3|3@1+ (1,0) [0|7] "" Vector__XXX
 SG_ RSF_SpeedLimit1FromMapType : 0|3@1+ (1,0) [0|7] "" Vector__XXX
 SG_ ExposureTimeRatio23 : 44|2@1+ (1,0) [0|3] "" Vector__XXX
 SG_ ExposureTimeRatio12 : 42|2@1+ (1,0) [0|3] "" Vector__XXX
 SG_ ExposureDCG : 47|1@1+ (1,0) [0|1] "" Vector__XXX
 SG_ ExposureAG : 46|1@1+ (1,0) [0|1] "" Vector__XXX
 SG_ CamAlignErr : 40|2@1+ (1,0) [0|3] "" Vector__XXX
 SG_ WheelBase : 16|8@1+ (0.1,0) [0|25] "m" Vector__XXX
 SG_ CameraToRadar : 24|8@1+ (0.05,-6.25) [-6.25|6.25] "" Vector__XXX
 SG_ CameraToFrontAxle : 32|8@1+ (0.05,-6.25) [-6.25|6.25] "" Vector__XXX

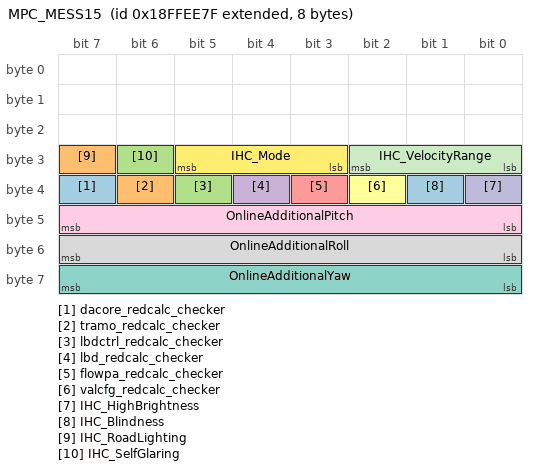
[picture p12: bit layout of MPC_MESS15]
BO_ 2566909567 MPC_MESS15: 8 MPC2
 SG_ dacore_redcalc_checker : 39|1@1+ (1,0) [0|0] "" Vector__XXX
 SG_ tramo_redcalc_checker : 38|1@1+ (1,0) [0|0] "" Vector__XXX
 SG_ lbdctrl_redcalc_checker : 37|1@1+ (1,0) [0|0] "" Vector__XXX
 SG_ lbd_redcalc_checker : 36|1@1+ (1,0) [0|0] "" Vector__XXX
 SG_ flowpa_redcalc_checker : 35|1@1+ (1,0) [0|1] "" Vector__XXX
 SG_ valcfg_redcalc_checker : 34|1@1+ (1,0) [0|1] "" Vector__XXX
 SG_ OnlineAdditionalYaw : 56|8@1+ (0.05,-5) [-5|5] "°" Vector__XXX
 SG_ OnlineAdditionalRoll : 48|8@1+ (0.05,-5) [-5|5] "°" Vector__XXX
 SG_ OnlineAdditionalPitch : 40|8@1+ (0.05,-5) [-5|5] "°" Vector__XXX
 SG_ IHC_HighBrightness : 32|1@1+ (1,0) [0|1] "" Vector__XXX
 SG_ IHC_VelocityRange : 24|3@1+ (1,0) [0|2] "" Vector__XXX
 SG_ IHC_Mode : 27|3@1+ (1,0) [0|2] "" Vector__XXX
 SG_ IHC_Blindness : 33|1@1+ (1,0) [0|1] "" Vector__XXX
 SG_ IHC_RoadLighting : 31|1@1+ (1,0) [0|1] "" Vector__XXX
 SG_ IHC_SelfGlaring : 30|1@1+ (1,0) [0|1] "" Vector__XXX

BO_ 2566909823 MPC_MESS16: 8 MPC2
 SG_ ADASIS_Cval_BuiltUpArea : 62|2@1+ (1,0) [0|3] "" Vector__XXX
 SG_ ADASIS_Cval_NumberOfLanes : 59|3@1+ (1,0) [0|7] "" Vector__XXX
 SG_ ADASIS_Cval_FuncRoadClass : 56|3@1+ (1,0) [0|7] "" Vector__XXX
 SG_ ADASIS_Cval_DividedRoad : 54|2@1+ (1,0) [0|3] "" Vector__XXX
 SG_ ADASIS_Cval_Tunnel : 52|2@1+ (1,0) [0|3] "" Vector__XXX
 SG_ ADASIS_Cval_FormOfWay : 48|4@1+ (1,0) [0|15] "" Vector__XXX
 SG_ Kickdown : 46|2@1+ (1,0) [0|1] "" Vector__XXX
 SG_ DrivingDirection : 44|2@1+ (1,0) [0|3] "" Vector__XXX
 SG_ TurnSignalRight : 42|2@1+ (1,0) [0|3] "" Vector__XXX
 SG_ TurnSignalLeft : 40|2@1+ (1,0) [0|4] "" Vector__XXX
 SG_ BrakePedal : 32|8@1+ (0.5,0) [0|100] "%" Vector__XXX
 SG_ AccelerationPedal : 24|8@1+ (0.5,0) [0|100] "%" Vector__XXX
 SG_ VehicleSpeed : 8|16@1+ (0.005,0) [0|327.675] "km/h" Vector__XXX
 SG_ KickdownError : 6|1@1+ (1,0) [0|1] "" Vector__XXX
 SG_ DrivingDirectionError : 5|1@1+ (1,0) [0|1] "" Vector__XXX
 SG_ TurnSignalRightError : 4|1@1+ (1,0) [0|1] "" Vector__XXX
 SG_ TurnSignalLeftError : 3|1@1+ (1,0) [0|1] "" Vector__XXX
 SG_ BrakePedalError : 2|1@1+ (1,0) [0|1] "" Vector__XXX
 SG_ AccelerationPedalError : 1|1@1+ (1,0) [0|1] "" Vector__XXX
 SG_ VehicleSpeedError : 0|1@1+ (1,0) [0|1] "" Vector__XXX

CM_ SG_ 2432639615 CRC_SG_MPC_C38_Pkt "Checksum C38 Current value MPC {5C,CA,3D,AB,1E,8C,FA,6D,DB,4E,BC,2F,9D,10,7E,EC}";
CM_ SG_ 2432639615 SQC_SG_MPC_C38_Pkt "Message Counter C38 Current Value MPC";
CM_ SG_ 2432639615 AnglLt_VehObj2_Cval_MPC "Angle Left Vehicle Object 2 Current value MPC";
CM_ SG_ 2432639615 AnglRt_VehObj2_Cval_MPC "Angle Right Vehicle Object 2 Current value MPC";
CM_ SG_ 2432639615 SclFctr_VehObj2_Cval_MPC "Scaling Factor Vehicle Object 2 Current value MPC";
CM_ SG_ 2432639871 CRC_SG_MPC_C39_Pkt "Checksum C39 Current value MPC {4B,98,E5,37,84,D1,23,70,BD,0F,5C,A9,F6,48,95,E2}";
CM_ SG_ 2432639871 SQC_SG_MPC_C39_Pkt "Message Counter C39 Current Value MPC";
CM_ SG_ 2432639871 AnglLt_VehObj3_Cval_MPC "Angle Left Vehicle Object 3 Current value MPC";
CM_ SG_ 2432639871 AnglRt_VehObj3_Cval_MPC "Angle Right Vehicle Object 3 Current value MPC";
CM_ SG_ 2432639871 SclFctr_VehObj3_Cval_MPC "Scaling Factor Vehicle Object 3 Current value MPC";
CM_ SG_ 2498756875 ABS_Actv_Stat "ABS61441S_EX_ABS_active";
CM_ SG_ 2498756875 BrkPdlPosn_Cval "Brake Pedal Position Current value";
CM_ SG_ 2499696943 RelLvlFAxL_Cval "Relative Level Front Axle Left Current value";
CM_ SG_ 2499696943 RelLvlFAxR_Cval "Relative Level Front Axle Right Current value";
CM_ SG_ 2499696943 RelLvlRAxL_Cval "Relative Level Rear Axle Left Current value";
CM_ SG_ 2499696943 RelLvlRAxR_Cval "Relative Level Rear Axle Right Current value";
CM_ SG_ 2499702539 RoadCurv_Cval "Road Curvature Current value";
CM_ SG_ 2499735808 VehSpd_Cval_CPC "Vehicle Speed Current value CPC";
CM_ SG_ 2499735808 CC_Actv_Stat "Cruise Control Active Current state";
CM_ SG_ 2499739775 Rsrv_CRC_SG_MPC_C02_Pkt "Checksum C02 Current value MPC";
CM_ SG_ 2499739775 Rsrv_SQC_SG_MPC_C02_Pkt "Sequence Counter C02 Current Value MPC";
CM_ SG_ 2499739775 DispCloAA_Rq_MPC "Display Color Attention Assist Requested state";
CM_ SG_ 2499739775 Lvl0_AA_Cval_MPC "Attention Assist Level (newest) Current value";
CM_ SG_ 2499739775 Lvl1_AA_Cval_MPC "Attention Assist Level (Before 1 min)";
CM_ SG_ 2499739775 Lvl2_AA_Cval_MPC "Attention Assist Level (Before 2 min)";
CM_ SG_ 2499739775 Lvl3_AA_Cval_MPC "Attention Assist Level (Before 3 min)";
CM_ SG_ 2499739775 Lvl4_AA_Cval_MPC "Attention Assist Level (Before 4 min)";
CM_ SG_ 2499739775 Lvl5_AA_Cval_MPC "Attention Assist Level (Before 5 min)";
CM_ SG_ 2499739775 Lvl6_AA_Cval_MPC "Attention Assist Level (Before 6 min)";
CM_ SG_ 2499739775 Lvl7_AA_Cval_MPC "Attention Assist Level (Before 7 min)";
CM_ SG_ 2499739775 Lvl8_AA_Cval_MPC "Attention Assist Level (Before 8 min)";
CM_ SG_ 2499739775 Lvl9_AA_Cval_MPC "Attention Assist Level (Before 9 min)";
CM_ SG_ 2499739775 AA_Enbl_Stat_MPC "Attention Assist Enable status MPC";
CM_ SG_ 2499739775 AA_Fkt_Stat_MPC "Attention Assist Function status";
CM_ SG_ 2499739775 Warn0_AA_Rq_MPC "Warning level 0 Attention Assist Requested state";
CM_ SG_ 2499739775 Warn1_AA_Rq_MPC "Warning level 1 Attention Assist Requested state";
CM_ SG_ 2499739915 ROP_EngCtrlActv2_Stat "ROP Engine Control active 2 Current state";
CM_ SG_ 2499739915 ROP_BrkCtrlActv2_Stat "ROP Brake Control active 2 Current state";
CM_ SG_ 2499739915 YC_EngCtrlActv2_Stat "YC Engine Control active 2 Current state";
CM_ SG_ 2499739915 YC_BrkCtrlActv2_Stat "YC Brake Control active 2 Current state";
CM_ SG_ 2499739915 TrlrEstm_Stat_BS "Trailer Estimation Current state BS";
CM_ SG_ 2499739953 TurnSglSwLt_Rq "Turn Signal Switch Left Requested state";
CM_ SG_ 2499739953 TurnSglSwRt_Rq "Turn Signal Switch Right Requested state";
CM_ SG_ 2499739953 WprSw_Rq "Wiper Switch Requested state";
CM_ SG_ 2499739953 LDW_Sw_Rq "Lane Departure Warning switch Requested state";
CM_ SG_ 2499740031 CRC_SG_MPC_C06_Pkt "Checksum C06 Current value MPC {58,F0,8D,2A,C2,5F,F7,94,31,C9,66,03,9B,38,D0,6D}";
CM_ SG_ 2499740031 SQC_SG_MPC_C06_Pkt "Sequence Counter C06 Current Value MPC";
CM_ SG_ 2499740031 SftyMonLaneLt_Stat_MPC "Safety Monitor Lane Left Current state MPC";
CM_ SG_ 2499740031 SftyMonLaneRt_Stat_MPC "Safety Monitor Lane Right Current state MPC";
CM_ SG_ 2499740031 LaneRangeLt_Cval_MPC "Range of Lane Marking left Current value MPC";
CM_ SG_ 2499740031 LaneRangeRt_Cval_MPC "Range of Lane Marking right Current value MPC";
CM_ SG_ 2499740031 LaneCrvtrChgLt_Cval_MPC "lane curvature change c1 left (MPC)";
CM_ SG_ 2499740031 LaneCrvtrChgRt_Cval_MPC "lane curvature change c1 right (MPC)";
CM_ SG_ 2499740648 CRC_SG_VRDU_C01_Pkt "Message checksum";
CM_ SG_ 2499740648 SQC_SG_VRDU_C01_Pkt "Message Counter C01 Current Value VRDU";
CM_ SG_ 2499740648 DrvDirec_Stat_VRDU "Drive Direction Current state VRDU";
CM_ SG_ 2499740648 ABA_DistWarn_Stat "ABA Distance Warning Current state";
CM_ SG_ 2499740648 ALA_Stat "Active Lane Assist Current state";
CM_ SG_ 2499740904 WhlBaseTrtr_Cval "Effective wheel base Tractor Current value";
CM_ SG_ 2499742976 RetSwPos_Rq_STSR "Retarder Switch Position";
CM_ SG_ 2565832698 APPL_SG_MPC "External application to ECU";
CM_ SG_ 2565864063 SG_APPL_MPC "ECU to external application";
CM_ SG_ 2566809216 BatMainSw_Stat "Battery Main Switch Hold State";
CM_ SG_ 2566841879 DateTmSecond_Cval_ICUC "Date Time Second Current value from ICUC";
CM_ SG_ 2566841879 DateTmMinute_Cval_ICUC "Date Time Minute(s) Current value from ICUC";
CM_ SG_ 2566841879 DateTmHour_Cval_ICUC "Date Time Hour(s) Current value from ICUC";
CM_ SG_ 2566841879 DateTmMonth_Cval_ICUC "Date Time Month Current value from ICUC";
CM_ SG_ 2566841879 DateTmDay_Cval_ICUC "Date Time Day Current value from ICUC";
CM_ SG_ 2566841879 DateTmYear_Cval_ICUC "Date Time Year Current value from ICUC";
CM_ SG_ 2566841879 LocalMinuteOffset_Cval_ICUC "Local Minute(s) Offset Current value from ICUC";
CM_ SG_ 2566841879 LocalHourOffset_Cval_ICUC "Local Hour(s) Offset Current value from ICUC";
CM_ SG_ 2566845201 Latitude_Cval_IPPC "Latitude Current value";
CM_ SG_ 2566845201 Longitude_Cval_IPPC "Longitude Current value";
CM_ SG_ 2566845729 AirTempOutsd_Cval_SCA "Air Temperature Outside Current value SCA";
CM_ SG_ 2566848549 Offboard_Tester_Stat "Offboard Tester Current Status";
CM_ SG_ 2566848549 SelfHealing2_Stat "Self Healing 2 Current State";
CM_ SG_ 2566848549 SelfHealing3_Stat "Self Healing 3 Current State";
CM_ SG_ 2566848549 TotalVehDist_Cval_DIAG "Total Vehicle Distance Current value Diagnostic";
CM_ SG_ 2566848791 TSR_MdSw_Rq "TSR Mode Switch Requested state";
CM_ SG_ 2566848895 TrafSign1_MPC "Traffic Sign 1 (MPC)";
CM_ SG_ 2566848895 TrafSign2_MPC "Traffic Sign 2 (MPC)";
CM_ SG_ 2566848895 SuppSign1_MPC "Supplementary Sign 1 (MPC)";
CM_ SG_ 2566848895 SuppSign2_MPC "Supplementary Sign 2 (MPC)";
CM_ SG_ 2566848895 TrafSignSpd_Unit_MPC "Traffic Sign Speed Unit (MPC)";
CM_ SG_ 2566848895 TrafSignIcon_Set_MPC "Traffic Sign Icon Set (MPC)";
CM_ SG_ 2566848895 SpdLimWarn_Rq_MPC "Speed Lim Warning Requested state MPC";
CM_ SG_ 2566848895 NoPassWarn_Rq_MPC "No Passing Warning Request MPC";
CM_ SG_ 2566848895 TSR_Func_Stat_MPC "TSR Function Current state MPC";
CM_ SG_ 2566848895 WrongWayWarn_Rq_MPC "Wrong Way Warning Requested state MPC";
CM_ SG_ 2566848895 TrafSign3_MPC "Traffic Sign 3 (MPC)";
CM_ SG_ 2566848895 TrafSign4_MPC "Traffic Sign 4 (MPC)";
CM_ SG_ 2566849047 AA_Stat_ICUC "Status Attention Assist from ICUC";
CM_ SG_ 2566849047 LDWS_FailWarnDev_Stat_ICUC "LDWS Failure Warning Device Current state ICUC";
CM_ SG_ 2566849151 VidCapVideoID_MPC2 "Video Cap Video ID MPC";
CM_ SG_ 2566849151 SuppSign3_MPC "Supplementary Sign 3 (MPC)";
CM_ SG_ 2566849151 SuppSign4_MPC "Supplementary Sign 4 (MPC)";
CM_ SG_ 2566849151 VehSpdLim_Rq_MPC "Vehicle Speed Limit(er) Requested state MPC";
CM_ SG_ 2566849151 VidCapFileAvl_Stat_MPC2 "Video Cap File Available Current state";
CM_ SG_ 2566849151 PassingMvreEstm_Stat_MPC "Passing Manoeuvring/Maneuver Estimated Current state MPC";
CM_ SG_ 2566850337 RainSensOpMod_Stat "Rain sensor operation mode";
CM_ SG_ 2566850337 RainSensSensitivity_Stat "Sensitivity of the rain sensor";
CM_ SG_ 2566850378 VidCapPreTrigLength "Video Cap Pre Trig Length";
CM_ SG_ 2566850378 VidCapLength "Video Cap Length";
CM_ SG_ 2566850378 VidCapLabel "Video Cap Label";
CM_ SG_ 2566850378 VidCapRec_Stat "Video Cap Rec Current state";
CM_ SG_ 2566850378 VidFileTrf_Stat "Video File Transfer Current state";
CM_ SG_ 2566850593 WprSpd_Stat "Wiper Speed Current state";
CM_ SG_ 2566851873 LDWS_FailWarnDev_Stat_SAM "LDWS Failure Warning Device Current state SAM";
CM_ SG_ 2566860172 LDWS_FailWarnDev_Stat_MUX3 "LDWS Failure Warning Device Current state MUX3";
CM_ SG_ 2566881280 NM_Mode "Network management mode";
CM_ SG_ 2566881280 NM_Successor "Network management logical successor";
CM_ SG_ 2566881280 NM_Ud_Launch "Network management userdata launch type";
CM_ SG_ 2566881280 NM_Sleep_Ack "Network management sleep acknowledge";
CM_ SG_ 2566881280 NM_Sleep_Ind "Network management sleep indication";
CM_ SG_ 2566881280 NM_Ud_Srv "Network management userdata service no.";
CM_ SG_ 2566881280 WakeupRsn_MPC "Wakeup reason";
CM_ SG_ 2566881280 Awake_NwSt "Stay awake for network startup";
CM_ SG_ 2566881280 Awake_Diag_Actv "Stay awake for diagnostics active";
CM_ SG_ 2566881280 Awake_IgnOn "Stay awake for ignition on";
CM_ SG_ 2566881280 Awake_XCP_Diag "Stay awake for XCP diagnostics";
CM_ SG_ 2566881280 Awake_VC_TrfData "Stay awake for VC Transfer Data";
CM_ SG_ 2566881280 WakeupCnt_cv "Counter for module wakeup states during network sleep";
CM_ SG_ 2566881280 Nw_Id "Network identification no.";
CM_ SG_ 2566897701 GVC_VehBrand "GVC Vehicle Brand";
CM_ SG_ 2566897701 GVC_VehModel "GVC Vehicle Model";
CM_ SG_ 2566897957 GVC_HdLmpType "GVC Headlamp Type";
CM_ SG_ 2566897957 GVC_TrackWidth "GVC Track width";
CM_ SG_ 2566897957 GVC_WhlBase "GVC Wheel Base";
CM_ SG_ 2566897957 GVC_LgtSens "GVC Light Sensor";
CM_ SG_ 2566898469 GVC_LDW_Func "GVC Lane Departure Warning Function";
CM_ SG_ 2566898469 GVC_D_AttenMonFunc "GVC Driver Attention Monitoring Function";
CM_ SG_ 2566898469 GVC_IHC_Func "GVC Intelligent Headlight Control Function";
CM_ SG_ 2566899237 GVC_SysMsg_IPPC "GVC System Message Integrated Predictive Powertrain control";
CM_ SG_ 2566899237 VMM_VersionYear_Cval "VMM Version Year Current value";
CM_ SG_ 2566899237 VMM_VersionWeek_Cval "VMM Version Week Current value";
CM_ SG_ 2566899493 GVC_TSR_Fct "GVC Traffic Sign Recognition Function";
CM_ SG_ 2566899749 VIN_Cntr_Stat "VIN Counter Current state";
CM_ SG_ 2566899749 VIN_Seg "vehicle identify number segment";
CM_ SG_ 2566899749 VIN_Seg2 "vehicle identify number segment 2";
CM_ SG_ 2566899749 VIN_Seg3 "vehicle identify number segment 3";
CM_ SG_ 2566899749 VIN_Seg4 "vehicle identify number segment 4";
CM_ SG_ 2566899749 VIN_Seg5 "vehicle identify number segment 5";
CM_ SG_ 2566899749 VIN_Seg6 "vehicle identify number segment 6";
CM_ SG_ 2566899749 VIN_Seg7 "vehicle identify number segment 7";
CM_ SG_ 2566900261 SteerRatioCntr_Cval "GVC steering ratio counter - current value";
CM_ SG_ 2566900261 SteerRatioNodesCntr_Cval "GVC steering ratio nodes counter - current value";
CM_ SG_ 2566900261 SteerRatioAnglType_Stat "GVC steering ratio angle type - state";
CM_ SG_ 2566900261 SteerRatioMS_Stat "GVC steering ratio mode signal - state";
CM_ SG_ 2566900261 FirstNdCntX_SteerRatio_Cval "GVC - steering ratio of first node of counter X - current value";
CM_ SG_ 2566900261 SecNdCntX_SteerRatio_Cval "GVC - steering ratio of second node of counter X - current value";
CM_ SG_ 2566900261 FirstNdCntX_AnglDeg_Cval "GVC - Angle in ° of first node of counter x - Mode 0";
CM_ SG_ 2566900261 FirstNdCntX_AnglRad_Cval "GVC - Angle in rad of first node of counter x - Mode 1";
CM_ SG_ 2566900261 SecNdCntX_AnglDeg_Cval "GVC - Angle in ° of second node of counter x - Mode 0";
CM_ SG_ 2566900261 SecNdCntX_AnglRad_Cval "GVC - Angle in rad of second node of counter x - Mode 1";
CM_ SG_ 2566907409 ADASIS_Cval_IPPC "ADASIS_Cval_IPPC";
CM_ SG_ 2566907409 ADASIS2_Cval_IPPC "ADASIS2_Cval_IPPC";
CM_ SG_ 2566907409 ADASIS3_Cval_IPPC "ADASIS3_Cval_IPPC";
CM_ SG_ 2566907409 ADASIS4_Cval_IPPC "ADASIS4_Cval_IPPC";
CM_ SG_ 2566907409 ADASIS5_Cval_IPPC "ADASIS5_Cval_IPPC";
CM_ SG_ 2566907409 ADASIS6_Cval_IPPC "ADASIS6_Cval_IPPC";
CM_ SG_ 2566907409 ADASIS7_Cval_IPPC "ADASIS7_Cval_IPPC";
CM_ SG_ 2566907409 ADASIS8_Cval_IPPC "ADASIS8_Cval_IPPC";
CM_ SG_ 2566908799 RSF_SpeedLimit2DisplaySource "0x0 = Unknown
0x1 = Video
0x2 = Navigation
0x3 = Fusion or Both";
CM_ SG_ 2566908799 RSF_SpeedLimit1DisplaySource "0x0 = Unknown
0x1 = Video
0x2 = Navigation
0x3 = Fusion or Both";
CM_ SG_ 2566908799 RSF_OtkRestrictionDisplaySource "0x0 = Unknown
0x1 = Video
0x2 = Navigation
0x3 = Fusion or Both";
BA_DEF_ SG_  "GenSigTimeout_MPC2" INT 0 65535;
BA_DEF_ BO_  "GenMsgStartValue" STRING ;
BA_DEF_ SG_  "GenSigSNA" STRING ;
BA_DEF_ SG_  "FlexKomIsMotorola" ENUM  "nein","ja";
BA_DEF_ SG_  "FlexKomSigLaenge" INT 0 64;
BA_DEF_ SG_  "FlexKomSigStartPos" INT 0 63;
BA_DEF_ SG_  "FlexKomComment" STRING ;
BA_DEF_ SG_  "FlexKomSigName" STRING ;
BA_DEF_ SG_  "FlexKomSID" INT 0 2147483647;
BA_DEF_ SG_  "GenSigStartValue" HEX 0 4294967295;
BA_DEF_ SG_  "FlexKomSigStartValue" STRING ;
BA_DEF_ SG_  "GenSigCycleTime" INT 0 65535;
BA_DEF_ SG_  "GenSigSendType" ENUM  "cyclicX","spontanX","cyclicIfActiveX","spontanWithDelay","cyclicAndSpontanX","cyclicAndSpontanWithDelay","spontanWithRepitition","cyclicIfActiveAndSpontanWD","cyclicIfActiveFast","cyclicWithRepeatOnDemand","none";
BA_DEF_ BO_  "GenMsgNrOfRepetitions" INT 0 65535;
BA_DEF_ BO_  "GenMsgDelayTime" INT 0 65535;
BA_DEF_ BO_  "GenMsgStartDelayTime" INT 0 65535;
BA_DEF_ BO_  "GenMsgCycleTime" INT 0 65535;
BA_DEF_ BO_  "GenMsgSendType" ENUM  "cyclicX","spontanX","cyclicIfActiveX","spontanWithDelay","cyclicAndSpontanX","cyclicAndSpontanWithDelay","spontanWithRepitition","cyclicIfActiveAndSpontanWD","cyclicIfActiveFast","cyclicWithRepeatOnDemand","none";
BA_DEF_ BO_  "DiagResponse" ENUM  "nein","ja";
BA_DEF_ BO_  "DiagRequest" ENUM  "nein","ja";
BA_DEF_ BO_  "DiagState" ENUM  "nein","ja";
BA_DEF_ BO_  "App-Botschaft" ENUM  "nein","ja";
BA_DEF_ BO_  "NWM-Botschaft" ENUM  "nein","ja";
BA_DEF_ BO_  "GenMsgMinAcceptLength" INT -1 8;
BA_DEF_DEF_  "GenSigTimeout_MPC2" 0;
BA_DEF_DEF_  "GenMsgStartValue" "";
BA_DEF_DEF_  "GenSigSNA" "";
BA_DEF_DEF_  "FlexKomIsMotorola" "nein";
BA_DEF_DEF_  "FlexKomSigLaenge" 0;
BA_DEF_DEF_  "FlexKomSigStartPos" 0;
BA_DEF_DEF_  "FlexKomComment" "";
BA_DEF_DEF_  "FlexKomSigName" "";
BA_DEF_DEF_  "FlexKomSID" 0;
BA_DEF_DEF_  "GenSigStartValue" 0;
BA_DEF_DEF_  "FlexKomSigStartValue" "";
BA_DEF_DEF_  "GenSigCycleTime" 0;
BA_DEF_DEF_  "GenSigSendType" "cyclicX";
BA_DEF_DEF_  "GenMsgNrOfRepetitions" 0;
BA_DEF_DEF_  "GenMsgDelayTime" 0;
BA_DEF_DEF_  "GenMsgStartDelayTime" 0;
BA_DEF_DEF_  "GenMsgCycleTime" 0;
BA_DEF_DEF_  "GenMsgSendType" "cyclicX";
BA_DEF_DEF_  "DiagResponse" "nein";
BA_DEF_DEF_  "DiagRequest" "nein";
BA_DEF_DEF_  "DiagState" "nein";
BA_DEF_DEF_  "App-Botschaft" "nein";
BA_DEF_DEF_  "NWM-Botschaft" "nein";
BA_DEF_DEF_  "GenMsgMinAcceptLength" -1;
BA_ "GenMsgStartDelayTime" BO_ 2432639615 30;
BA_ "GenMsgStartValue" BO_ 2432639615 "65F0FFFFFFFFFFFFh";
BA_ "GenMsgNrOfRepetitions" BO_ 2432639615 2;
BA_ "GenMsgDelayTime" BO_ 2432639615 20;
BA_ "GenMsgCycleTime" BO_ 2432639615 50;
BA_ "GenMsgStartDelayTime" BO_ 2432639871 40;
BA_ "GenMsgStartValue" BO_ 2432639871 "06F0FFFFFFFFFFFFh";
BA_ "GenMsgNrOfRepetitions" BO_ 2432639871 2;
BA_ "GenMsgDelayTime" BO_ 2432639871 20;
BA_ "GenMsgCycleTime" BO_ 2432639871 50;
BA_ "GenMsgStartValue" BO_ 2498756875 "FFFFFFFFFFFFFFFFh";
BA_ "GenMsgNrOfRepetitions" BO_ 2498756875 2;
BA_ "GenMsgDelayTime" BO_ 2498756875 20;
BA_ "GenMsgCycleTime" BO_ 2498756875 100;
BA_ "GenMsgMinAcceptLength" BO_ 2498756875 8;
BA_ "GenMsgStartValue" BO_ 2499696943 "FFFFFFFFFFFFFFFFh";
BA_ "GenMsgNrOfRepetitions" BO_ 2499696943 2;
BA_ "GenMsgDelayTime" BO_ 2499696943 20;
BA_ "GenMsgCycleTime" BO_ 2499696943 100;
BA_ "GenMsgMinAcceptLength" BO_ 2499696943 8;
BA_ "GenMsgStartValue" BO_ 2499702539 "FFFFFFFFFFFFFFFFh";
BA_ "GenMsgNrOfRepetitions" BO_ 2499702539 2;
BA_ "GenMsgDelayTime" BO_ 2499702539 20;
BA_ "GenMsgCycleTime" BO_ 2499702539 100;
BA_ "GenMsgMinAcceptLength" BO_ 2499702539 8;
BA_ "GenMsgStartValue" BO_ 2499735808 "FFFFFFFFFFFFFFFFh";
BA_ "GenMsgNrOfRepetitions" BO_ 2499735808 2;
BA_ "GenMsgDelayTime" BO_ 2499735808 20;
BA_ "GenMsgCycleTime" BO_ 2499735808 100;
BA_ "GenMsgMinAcceptLength" BO_ 2499735808 8;
BA_ "GenMsgStartDelayTime" BO_ 2499739775 40;
BA_ "GenMsgStartValue" BO_ 2499739775 "00F00000000000FFh";
BA_ "GenMsgNrOfRepetitions" BO_ 2499739775 2;
BA_ "GenMsgDelayTime" BO_ 2499739775 20;
BA_ "GenMsgCycleTime" BO_ 2499739775 100;
BA_ "GenMsgStartValue" BO_ 2499739915 "FFFFFFFFFFFFFFFFh";
BA_ "GenMsgNrOfRepetitions" BO_ 2499739915 2;
BA_ "GenMsgDelayTime" BO_ 2499739915 20;
BA_ "GenMsgCycleTime" BO_ 2499739915 100;
BA_ "GenMsgMinAcceptLength" BO_ 2499739915 8;
BA_ "GenMsgStartValue" BO_ 2499739953 "FFFFF0FFFFFFFFFFh";
BA_ "GenMsgNrOfRepetitions" BO_ 2499739953 2;
BA_ "GenMsgDelayTime" BO_ 2499739953 20;
BA_ "GenMsgCycleTime" BO_ 2499739953 100;
BA_ "GenMsgSendType" BO_ 2499739953 5;
BA_ "GenMsgMinAcceptLength" BO_ 2499739953 8;
BA_ "GenMsgStartDelayTime" BO_ 2499740031 50;
BA_ "GenMsgStartValue" BO_ 2499740031 "D9F0FFFFFFFFFFFFh";
BA_ "GenMsgNrOfRepetitions" BO_ 2499740031 2;
BA_ "GenMsgDelayTime" BO_ 2499740031 20;
BA_ "GenMsgCycleTime" BO_ 2499740031 100;
BA_ "GenMsgStartValue" BO_ 2499740648 "00F0F3FFFFFFFFFFh";
BA_ "GenMsgNrOfRepetitions" BO_ 2499740648 2;
BA_ "GenMsgDelayTime" BO_ 2499740648 20;
BA_ "GenMsgCycleTime" BO_ 2499740648 100;
BA_ "GenMsgMinAcceptLength" BO_ 2499740648 8;
BA_ "GenMsgStartValue" BO_ 2499740904 "FFFFFFFFFFFFFFFFh";
BA_ "GenMsgNrOfRepetitions" BO_ 2499740904 2;
BA_ "GenMsgDelayTime" BO_ 2499740904 20;
BA_ "GenMsgCycleTime" BO_ 2499740904 100;
BA_ "GenMsgMinAcceptLength" BO_ 2499740904 8;
BA_ "GenMsgStartValue" BO_ 2499742976 "FFFFFFFFFFF0FFFCh";
BA_ "GenMsgNrOfRepetitions" BO_ 2499742976 2;
BA_ "GenMsgDelayTime" BO_ 2499742976 20;
BA_ "GenMsgCycleTime" BO_ 2499742976 100;
BA_ "GenMsgSendType" BO_ 2499742976 5;
BA_ "GenMsgMinAcceptLength" BO_ 2499742976 8;
BA_ "GenMsgStartValue" BO_ 2565832698 "0000000000000000h";
BA_ "GenMsgNrOfRepetitions" BO_ 2565832698 2;
BA_ "GenMsgDelayTime" BO_ 2565832698 20;
BA_ "GenMsgSendType" BO_ 2565832698 1;
BA_ "GenMsgMinAcceptLength" BO_ 2565832698 8;
BA_ "App-Botschaft" BO_ 2565832698 1;
BA_ "GenMsgStartValue" BO_ 2565864063 "0000000000000000h";
BA_ "GenMsgNrOfRepetitions" BO_ 2565864063 2;
BA_ "GenMsgDelayTime" BO_ 2565864063 20;
BA_ "GenMsgSendType" BO_ 2565864063 1;
BA_ "App-Botschaft" BO_ 2565864063 1;
BA_ "GenMsgStartValue" BO_ 2566809216 "FFFFFFFFFFFFFFFFh";
BA_ "GenMsgNrOfRepetitions" BO_ 2566809216 2;
BA_ "GenMsgDelayTime" BO_ 2566809216 20;
BA_ "GenMsgCycleTime" BO_ 2566809216 1000;
BA_ "GenMsgSendType" BO_ 2566809216 5;
BA_ "GenMsgMinAcceptLength" BO_ 2566809216 8;
BA_ "GenMsgStartValue" BO_ 2566841879 "FFFFFFFFFFFFFFFFh";
BA_ "GenMsgNrOfRepetitions" BO_ 2566841879 2;
BA_ "GenMsgDelayTime" BO_ 2566841879 20;
BA_ "GenMsgCycleTime" BO_ 2566841879 1000;
BA_ "GenMsgMinAcceptLength" BO_ 2566841879 8;
BA_ "GenMsgStartValue" BO_ 2566845201 "FFFFFFFFFFFFFFFFh";
BA_ "GenMsgNrOfRepetitions" BO_ 2566845201 2;
BA_ "GenMsgDelayTime" BO_ 2566845201 20;
BA_ "GenMsgCycleTime" BO_ 2566845201 1000;
BA_ "GenMsgMinAcceptLength" BO_ 2566845201 8;
BA_ "GenMsgStartValue" BO_ 2566845729 "FFFFFFFFFFFFFFFFh";
BA_ "GenMsgNrOfRepetitions" BO_ 2566845729 2;
BA_ "GenMsgDelayTime" BO_ 2566845729 20;
BA_ "GenMsgCycleTime" BO_ 2566845729 1000;
BA_ "GenMsgMinAcceptLength" BO_ 2566845729 8;
BA_ "GenMsgStartValue" BO_ 2566848549 "FFFFFFFFFFFFFFFFh";
BA_ "GenMsgNrOfRepetitions" BO_ 2566848549 2;
BA_ "GenMsgDelayTime" BO_ 2566848549 20;
BA_ "GenMsgCycleTime" BO_ 2566848549 1000;
BA_ "GenMsgSendType" BO_ 2566848549 5;
BA_ "GenMsgMinAcceptLength" BO_ 2566848549 8;
BA_ "GenMsgStartValue" BO_ 2566848791 "FFFFFFFFFFFFFFFFh";
BA_ "GenMsgNrOfRepetitions" BO_ 2566848791 2;
BA_ "GenMsgDelayTime" BO_ 2566848791 100;
BA_ "GenMsgCycleTime" BO_ 2566848791 1000;
BA_ "GenMsgSendType" BO_ 2566848791 5;
BA_ "GenMsgMinAcceptLength" BO_ 2566848791 8;
BA_ "GenMsgStartDelayTime" BO_ 2566848895 50;
BA_ "GenMsgStartValue" BO_ 2566848895 "FFFFFFFFFFFFFFFFh";
BA_ "GenMsgNrOfRepetitions" BO_ 2566848895 2;
BA_ "GenMsgDelayTime" BO_ 2566848895 100;
BA_ "GenMsgCycleTime" BO_ 2566848895 1000;
BA_ "GenMsgSendType" BO_ 2566848895 5;
BA_ "GenMsgStartValue" BO_ 2566849047 "0FFF0FFF00FFFFFFh";
BA_ "GenMsgNrOfRepetitions" BO_ 2566849047 2;
BA_ "GenMsgDelayTime" BO_ 2566849047 20;
BA_ "GenMsgCycleTime" BO_ 2566849047 1000;
BA_ "GenMsgSendType" BO_ 2566849047 5;
BA_ "GenMsgMinAcceptLength" BO_ 2566849047 8;
BA_ "GenMsgStartDelayTime" BO_ 2566849151 50;
BA_ "GenMsgStartValue" BO_ 2566849151 "FFFFFFFFFFFFFFFFh";
BA_ "GenMsgNrOfRepetitions" BO_ 2566849151 2;
BA_ "GenMsgDelayTime" BO_ 2566849151 100;
BA_ "GenMsgCycleTime" BO_ 2566849151 1000;
BA_ "GenMsgSendType" BO_ 2566849151 5;
BA_ "GenMsgStartValue" BO_ 2566850337 "FFFFFFFFFFFFFFFFh";
BA_ "GenMsgNrOfRepetitions" BO_ 2566850337 2;
BA_ "GenMsgDelayTime" BO_ 2566850337 20;
BA_ "GenMsgCycleTime" BO_ 2566850337 1000;
BA_ "GenMsgSendType" BO_ 2566850337 5;
BA_ "GenMsgMinAcceptLength" BO_ 2566850337 8;
BA_ "GenMsgStartValue" BO_ 2566850378 "FFFFFFFFFFFFFFFFh";
BA_ "GenMsgNrOfRepetitions" BO_ 2566850378 2;
BA_ "GenMsgDelayTime" BO_ 2566850378 20;
BA_ "GenMsgCycleTime" BO_ 2566850378 1000;
BA_ "GenMsgMinAcceptLength" BO_ 2566850378 8;
BA_ "GenMsgStartValue" BO_ 2566850593 "FFFFFFFFFFFFFFFFh";
BA_ "GenMsgNrOfRepetitions" BO_ 2566850593 2;
BA_ "GenMsgDelayTime" BO_ 2566850593 20;
BA_ "GenMsgCycleTime" BO_ 2566850593 1000;
BA_ "GenMsgSendType" BO_ 2566850593 5;
BA_ "GenMsgMinAcceptLength" BO_ 2566850593 8;
BA_ "GenMsgStartValue" BO_ 2566851873 "FFFFFFFFFFFFFFFFh";
BA_ "GenMsgNrOfRepetitions" BO_ 2566851873 2;
BA_ "GenMsgDelayTime" BO_ 2566851873 20;
BA_ "GenMsgCycleTime" BO_ 2566851873 1000;
BA_ "GenMsgSendType" BO_ 2566851873 5;
BA_ "GenMsgMinAcceptLength" BO_ 2566851873 8;
BA_ "GenMsgStartValue" BO_ 2566860172 "FFFFFFFFFFFFFFFFh";
BA_ "GenMsgNrOfRepetitions" BO_ 2566860172 2;
BA_ "GenMsgDelayTime" BO_ 2566860172 20;
BA_ "GenMsgCycleTime" BO_ 2566860172 1000;
BA_ "GenMsgSendType" BO_ 2566860172 5;
BA_ "GenMsgMinAcceptLength" BO_ 2566860172 8;
BA_ "GenMsgStartValue" BO_ 2566881280 "FFFFFFFFFFFFFFFFh";
BA_ "GenMsgNrOfRepetitions" BO_ 2566881280 2;
BA_ "GenMsgDelayTime" BO_ 2566881280 20;
BA_ "GenMsgMinAcceptLength" BO_ 2566881280 8;
BA_ "NWM-Botschaft" BO_ 2566881280 1;
BA_ "GenMsgStartValue" BO_ 2566897701 "FFFFFFFFFFFFFFFFh";
BA_ "GenMsgNrOfRepetitions" BO_ 2566897701 2;
BA_ "GenMsgDelayTime" BO_ 2566897701 20;
BA_ "GenMsgSendType" BO_ 2566897701 1;
BA_ "GenMsgMinAcceptLength" BO_ 2566897701 8;
BA_ "GenMsgStartValue" BO_ 2566897957 "FFFFFFFFFFFFFFFFh";
BA_ "GenMsgNrOfRepetitions" BO_ 2566897957 2;
BA_ "GenMsgDelayTime" BO_ 2566897957 20;
BA_ "GenMsgSendType" BO_ 2566897957 1;
BA_ "GenMsgMinAcceptLength" BO_ 2566897957 8;
BA_ "GenMsgStartValue" BO_ 2566898469 "FFFFFFFFFFFFFFFFh";
BA_ "GenMsgNrOfRepetitions" BO_ 2566898469 2;
BA_ "GenMsgDelayTime" BO_ 2566898469 20;
BA_ "GenMsgSendType" BO_ 2566898469 1;
BA_ "GenMsgMinAcceptLength" BO_ 2566898469 8;
BA_ "GenMsgStartValue" BO_ 2566899237 "FFFFFFFFFFFFFFFFh";
BA_ "GenMsgNrOfRepetitions" BO_ 2566899237 2;
BA_ "GenMsgDelayTime" BO_ 2566899237 20;
BA_ "GenMsgSendType" BO_ 2566899237 1;
BA_ "GenMsgMinAcceptLength" BO_ 2566899237 8;
BA_ "GenMsgStartValue" BO_ 2566899493 "FFFFFFFFFFFFFF00h";
BA_ "GenMsgNrOfRepetitions" BO_ 2566899493 2;
BA_ "GenMsgDelayTime" BO_ 2566899493 20;
BA_ "GenMsgSendType" BO_ 2566899493 1;
BA_ "GenMsgMinAcceptLength" BO_ 2566899493 8;
BA_ "GenMsgStartValue" BO_ 2566899749 "00FFFFFFFFFFFFFFh";
BA_ "GenMsgNrOfRepetitions" BO_ 2566899749 2;
BA_ "GenMsgDelayTime" BO_ 2566899749 20;
BA_ "GenMsgSendType" BO_ 2566899749 1;
BA_ "GenMsgMinAcceptLength" BO_ 2566899749 8;
BA_ "GenMsgStartValue" BO_ 2566900261 "FF3FFFFFFFFFFFFFh";
BA_ "GenMsgNrOfRepetitions" BO_ 2566900261 2;
BA_ "GenMsgDelayTime" BO_ 2566900261 20;
BA_ "GenMsgSendType" BO_ 2566900261 1;
BA_ "GenMsgMinAcceptLength" BO_ 2566900261 8;
BA_ "GenMsgStartValue" BO_ 2566905983 "0000000000000000h";
BA_ "GenMsgNrOfRepetitions" BO_ 2566905983 2;
BA_ "GenMsgDelayTime" BO_ 2566905983 20;
BA_ "GenMsgSendType" BO_ 2566905983 1;
BA_ "GenMsgCycleTime" BO_ 2566905983 10;
BA_ "GenMsgStartValue" BO_ 2566906239 "0000000000000000h";
BA_ "GenMsgNrOfRepetitions" BO_ 2566906239 2;
BA_ "GenMsgDelayTime" BO_ 2566906239 20;
BA_ "GenMsgSendType" BO_ 2566906239 1;
BA_ "GenMsgCycleTime" BO_ 2566906239 10;
BA_ "GenMsgStartValue" BO_ 2566906495 "FFFFFFFFFFFFFFFFh";
BA_ "GenMsgNrOfRepetitions" BO_ 2566906495 2;
BA_ "GenMsgDelayTime" BO_ 2566906495 20;
BA_ "GenMsgSendType" BO_ 2566906495 1;
BA_ "GenMsgCycleTime" BO_ 2566906495 1;
BA_ "GenMsgStartValue" BO_ 2566906751 "0000000000000000h";
BA_ "GenMsgNrOfRepetitions" BO_ 2566906751 2;
BA_ "GenMsgDelayTime" BO_ 2566906751 20;
BA_ "GenMsgSendType" BO_ 2566906751 1;
BA_ "GenMsgCycleTime" BO_ 2566906751 10;
BA_ "GenMsgStartValue" BO_ 2566907007 "0000000000000000h";
BA_ "GenMsgNrOfRepetitions" BO_ 2566907007 2;
BA_ "GenMsgDelayTime" BO_ 2566907007 20;
BA_ "GenMsgSendType" BO_ 2566907007 1;
BA_ "GenMsgCycleTime" BO_ 2566907007 10;
BA_ "GenMsgStartValue" BO_ 2566907263 "0000000000000000h";
BA_ "GenMsgNrOfRepetitions" BO_ 2566907263 2;
BA_ "GenMsgDelayTime" BO_ 2566907263 20;
BA_ "GenMsgSendType" BO_ 2566907263 1;
BA_ "GenMsgCycleTime" BO_ 2566907263 10;
BA_ "GenMsgStartValue" BO_ 2566907409 "FFFFFFFFFFFFFFFFh";
BA_ "GenMsgNrOfRepetitions" BO_ 2566907409 2;
BA_ "GenMsgDelayTime" BO_ 2566907409 20;
BA_ "GenMsgSendType" BO_ 2566907409 1;
BA_ "GenMsgMinAcceptLength" BO_ 2566907409 8;
BA_ "GenMsgStartValue" BO_ 2566907519 "0000000000000000h";
BA_ "GenMsgNrOfRepetitions" BO_ 2566907519 2;
BA_ "GenMsgDelayTime" BO_ 2566907519 20;
BA_ "GenMsgSendType" BO_ 2566907519 1;
BA_ "GenMsgCycleTime" BO_ 2566907519 10;
BA_ "GenMsgStartValue" BO_ 2566907775 "0000000000000000h";
BA_ "GenMsgNrOfRepetitions" BO_ 2566907775 2;
BA_ "GenMsgDelayTime" BO_ 2566907775 20;
BA_ "GenMsgSendType" BO_ 2566907775 1;
BA_ "GenMsgCycleTime" BO_ 2566907775 10;
BA_ "GenMsgStartValue" BO_ 2566908031 "0000000000000000h";
BA_ "GenMsgNrOfRepetitions" BO_ 2566908031 2;
BA_ "GenMsgDelayTime" BO_ 2566908031 20;
BA_ "GenMsgSendType" BO_ 2566908031 1;
BA_ "GenMsgCycleTime" BO_ 2566908031 10;
BA_ "GenMsgStartValue" BO_ 2566908287 "0000000000000000h";
BA_ "GenMsgNrOfRepetitions" BO_ 2566908287 2;
BA_ "GenMsgDelayTime" BO_ 2566908287 20;
BA_ "GenMsgSendType" BO_ 2566908287 1;
BA_ "GenMsgCycleTime" BO_ 2566908287 10;
BA_ "GenMsgStartValue" BO_ 2566908543 "0000000000000000h";
BA_ "GenMsgNrOfRepetitions" BO_ 2566908543 2;
BA_ "GenMsgDelayTime" BO_ 2566908543 20;
BA_ "GenMsgSendType" BO_ 2566908543 1;
BA_ "GenMsgCycleTime" BO_ 2566908543 10;
BA_ "GenMsgStartValue" BO_ 2566908799 "0000000000000000h";
BA_ "GenMsgNrOfRepetitions" BO_ 2566908799 2;
BA_ "GenMsgDelayTime" BO_ 2566908799 20;
BA_ "GenMsgSendType" BO_ 2566908799 1;
BA_ "GenMsgCycleTime" BO_ 2566908799 10;
BA_ "GenMsgStartValue" BO_ 2566909055 "0000000000000000h";
BA_ "GenMsgNrOfRepetitions" BO_ 2566909055 2;
BA_ "GenMsgDelayTime" BO_ 2566909055 20;
BA_ "GenMsgSendType" BO_ 2566909055 1;
BA_ "GenMsgCycleTime" BO_ 2566909055 10;
BA_ "GenMsgStartValue" BO_ 2566909311 "0000000000000000h";
BA_ "GenMsgNrOfRepetitions" BO_ 2566909311 2;
BA_ "GenMsgDelayTime" BO_ 2566909311 20;
BA_ "GenMsgSendType" BO_ 2566909311 1;
BA_ "GenMsgCycleTime" BO_ 2566909311 10;
BA_ "GenMsgStartValue" BO_ 2566909567 "0000000000000000h";
BA_ "GenMsgNrOfRepetitions" BO_ 2566909567 2;
BA_ "GenMsgDelayTime" BO_ 2566909567 20;
BA_ "GenMsgSendType" BO_ 2566909567 1;
BA_ "GenMsgCycleTime" BO_ 2566909567 10;
BA_ "GenMsgStartValue" BO_ 2566909823 "0000000000000000h";
BA_ "GenMsgNrOfRepetitions" BO_ 2566909823 2;
BA_ "GenMsgDelayTime" BO_ 2566909823 20;
BA_ "GenMsgSendType" BO_ 2566909823 1;
BA_ "GenMsgCycleTime" BO_ 2566909823 10;
BA_ "GenSigSNA" SG_ 2432639615 CRC_SG_MPC_C38_Pkt "65h";
BA_ "FlexKomIsMotorola" SG_ 2432639615 CRC_SG_MPC_C38_Pkt 1;
BA_ "FlexKomComment" SG_ 2432639615 CRC_SG_MPC_C38_Pkt "MPC_C38_Pkt";
BA_ "FlexKomSigName" SG_ 2432639615 CRC_SG_MPC_C38_Pkt "MPC_C38_Pkt";
BA_ "FlexKomSigLaenge" SG_ 2432639615 CRC_SG_MPC_C38_Pkt 64;
BA_ "FlexKomSigStartPos" SG_ 2432639615 CRC_SG_MPC_C38_Pkt 7;
BA_ "FlexKomSID" SG_ 2432639615 CRC_SG_MPC_C38_Pkt 100680320;
BA_ "GenSigStartValue" SG_ 2432639615 CRC_SG_MPC_C38_Pkt 101;
BA_ "FlexKomSigStartValue" SG_ 2432639615 CRC_SG_MPC_C38_Pkt "65F0FFFFFFFFFFFFh";
BA_ "GenSigCycleTime" SG_ 2432639615 CRC_SG_MPC_C38_Pkt 50;
BA_ "GenSigSNA" SG_ 2432639615 SQC_SG_MPC_C38_Pkt "0h";
BA_ "FlexKomIsMotorola" SG_ 2432639615 SQC_SG_MPC_C38_Pkt 1;
BA_ "FlexKomComment" SG_ 2432639615 SQC_SG_MPC_C38_Pkt "MPC_C38_Pkt";
BA_ "FlexKomSigName" SG_ 2432639615 SQC_SG_MPC_C38_Pkt "MPC_C38_Pkt";
BA_ "FlexKomSigLaenge" SG_ 2432639615 SQC_SG_MPC_C38_Pkt 64;
BA_ "FlexKomSigStartPos" SG_ 2432639615 SQC_SG_MPC_C38_Pkt 7;
BA_ "FlexKomSID" SG_ 2432639615 SQC_SG_MPC_C38_Pkt 100680320;
BA_ "FlexKomSigStartValue" SG_ 2432639615 SQC_SG_MPC_C38_Pkt "65F0FFFFFFFFFFFFh";
BA_ "GenSigCycleTime" SG_ 2432639615 SQC_SG_MPC_C38_Pkt 50;
BA_ "GenSigSNA" SG_ 2432639615 AnglLt_VehObj2_Cval_MPC "FFFFh";
BA_ "FlexKomIsMotorola" SG_ 2432639615 AnglLt_VehObj2_Cval_MPC 1;
BA_ "FlexKomComment" SG_ 2432639615 AnglLt_VehObj2_Cval_MPC "MPC_C38_Pkt";
BA_ "FlexKomSigName" SG_ 2432639615 AnglLt_VehObj2_Cval_MPC "MPC_C38_Pkt";
BA_ "FlexKomSigLaenge" SG_ 2432639615 AnglLt_VehObj2_Cval_MPC 64;
BA_ "FlexKomSigStartPos" SG_ 2432639615 AnglLt_VehObj2_Cval_MPC 7;
BA_ "FlexKomSID" SG_ 2432639615 AnglLt_VehObj2_Cval_MPC 100680320;
BA_ "GenSigStartValue" SG_ 2432639615 AnglLt_VehObj2_Cval_MPC 65535;
BA_ "FlexKomSigStartValue" SG_ 2432639615 AnglLt_VehObj2_Cval_MPC "65F0FFFFFFFFFFFFh";
BA_ "GenSigCycleTime" SG_ 2432639615 AnglLt_VehObj2_Cval_MPC 50;
BA_ "GenSigSNA" SG_ 2432639615 AnglRt_VehObj2_Cval_MPC "FFFFh";
BA_ "FlexKomIsMotorola" SG_ 2432639615 AnglRt_VehObj2_Cval_MPC 1;
BA_ "FlexKomComment" SG_ 2432639615 AnglRt_VehObj2_Cval_MPC "MPC_C38_Pkt";
BA_ "FlexKomSigName" SG_ 2432639615 AnglRt_VehObj2_Cval_MPC "MPC_C38_Pkt";
BA_ "FlexKomSigLaenge" SG_ 2432639615 AnglRt_VehObj2_Cval_MPC 64;
BA_ "FlexKomSigStartPos" SG_ 2432639615 AnglRt_VehObj2_Cval_MPC 7;
BA_ "FlexKomSID" SG_ 2432639615 AnglRt_VehObj2_Cval_MPC 100680320;
BA_ "GenSigStartValue" SG_ 2432639615 AnglRt_VehObj2_Cval_MPC 65535;
BA_ "FlexKomSigStartValue" SG_ 2432639615 AnglRt_VehObj2_Cval_MPC "65F0FFFFFFFFFFFFh";
BA_ "GenSigCycleTime" SG_ 2432639615 AnglRt_VehObj2_Cval_MPC 50;
BA_ "GenSigSNA" SG_ 2432639615 SclFctr_VehObj2_Cval_MPC "FFFFh";
BA_ "FlexKomIsMotorola" SG_ 2432639615 SclFctr_VehObj2_Cval_MPC 1;
BA_ "FlexKomComment" SG_ 2432639615 SclFctr_VehObj2_Cval_MPC "MPC_C38_Pkt";
BA_ "FlexKomSigName" SG_ 2432639615 SclFctr_VehObj2_Cval_MPC "MPC_C38_Pkt";
BA_ "FlexKomSigLaenge" SG_ 2432639615 SclFctr_VehObj2_Cval_MPC 64;
BA_ "FlexKomSigStartPos" SG_ 2432639615 SclFctr_VehObj2_Cval_MPC 7;
BA_ "FlexKomSID" SG_ 2432639615 SclFctr_VehObj2_Cval_MPC 100680320;
BA_ "GenSigStartValue" SG_ 2432639615 SclFctr_VehObj2_Cval_MPC 65535;
BA_ "FlexKomSigStartValue" SG_ 2432639615 SclFctr_VehObj2_Cval_MPC "65F0FFFFFFFFFFFFh";
BA_ "GenSigCycleTime" SG_ 2432639615 SclFctr_VehObj2_Cval_MPC 50;
BA_ "GenSigSNA" SG_ 2432639871 CRC_SG_MPC_C39_Pkt "6h";
BA_ "FlexKomIsMotorola" SG_ 2432639871 CRC_SG_MPC_C39_Pkt 1;
BA_ "FlexKomComment" SG_ 2432639871 CRC_SG_MPC_C39_Pkt "MPC_C39_Pkt";
BA_ "FlexKomSigName" SG_ 2432639871 CRC_SG_MPC_C39_Pkt "MPC_C39_Pkt";
BA_ "FlexKomSigLaenge" SG_ 2432639871 CRC_SG_MPC_C39_Pkt 64;
BA_ "FlexKomSigStartPos" SG_ 2432639871 CRC_SG_MPC_C39_Pkt 7;
BA_ "FlexKomSID" SG_ 2432639871 CRC_SG_MPC_C39_Pkt 100680321;
BA_ "GenSigStartValue" SG_ 2432639871 CRC_SG_MPC_C39_Pkt 6;
BA_ "FlexKomSigStartValue" SG_ 2432639871 CRC_SG_MPC_C39_Pkt "06F0FFFFFFFFFFFFh";
BA_ "GenSigCycleTime" SG_ 2432639871 CRC_SG_MPC_C39_Pkt 50;
BA_ "GenSigSNA" SG_ 2432639871 SQC_SG_MPC_C39_Pkt "0h";
BA_ "FlexKomIsMotorola" SG_ 2432639871 SQC_SG_MPC_C39_Pkt 1;
BA_ "FlexKomComment" SG_ 2432639871 SQC_SG_MPC_C39_Pkt "MPC_C39_Pkt";
BA_ "FlexKomSigName" SG_ 2432639871 SQC_SG_MPC_C39_Pkt "MPC_C39_Pkt";
BA_ "FlexKomSigLaenge" SG_ 2432639871 SQC_SG_MPC_C39_Pkt 64;
BA_ "FlexKomSigStartPos" SG_ 2432639871 SQC_SG_MPC_C39_Pkt 7;
BA_ "FlexKomSID" SG_ 2432639871 SQC_SG_MPC_C39_Pkt 100680321;
BA_ "FlexKomSigStartValue" SG_ 2432639871 SQC_SG_MPC_C39_Pkt "06F0FFFFFFFFFFFFh";
BA_ "GenSigCycleTime" SG_ 2432639871 SQC_SG_MPC_C39_Pkt 50;
BA_ "GenSigSNA" SG_ 2432639871 AnglLt_VehObj3_Cval_MPC "FFFFh";
BA_ "FlexKomIsMotorola" SG_ 2432639871 AnglLt_VehObj3_Cval_MPC 1;
BA_ "FlexKomComment" SG_ 2432639871 AnglLt_VehObj3_Cval_MPC "MPC_C39_Pkt";
BA_ "FlexKomSigName" SG_ 2432639871 AnglLt_VehObj3_Cval_MPC "MPC_C39_Pkt";
BA_ "FlexKomSigLaenge" SG_ 2432639871 AnglLt_VehObj3_Cval_MPC 64;
BA_ "FlexKomSigStartPos" SG_ 2432639871 AnglLt_VehObj3_Cval_MPC 7;
BA_ "FlexKomSID" SG_ 2432639871 AnglLt_VehObj3_Cval_MPC 100680321;
BA_ "GenSigStartValue" SG_ 2432639871 AnglLt_VehObj3_Cval_MPC 65535;
BA_ "FlexKomSigStartValue" SG_ 2432639871 AnglLt_VehObj3_Cval_MPC "06F0FFFFFFFFFFFFh";
BA_ "GenSigCycleTime" SG_ 2432639871 AnglLt_VehObj3_Cval_MPC 50;
BA_ "GenSigSNA" SG_ 2432639871 AnglRt_VehObj3_Cval_MPC "FFFFh";
BA_ "FlexKomIsMotorola" SG_ 2432639871 AnglRt_VehObj3_Cval_MPC 1;
BA_ "FlexKomComment" SG_ 2432639871 AnglRt_VehObj3_Cval_MPC "MPC_C39_Pkt";
BA_ "FlexKomSigName" SG_ 2432639871 AnglRt_VehObj3_Cval_MPC "MPC_C39_Pkt";
BA_ "FlexKomSigLaenge" SG_ 2432639871 AnglRt_VehObj3_Cval_MPC 64;
BA_ "FlexKomSigStartPos" SG_ 2432639871 AnglRt_VehObj3_Cval_MPC 7;
BA_ "FlexKomSID" SG_ 2432639871 AnglRt_VehObj3_Cval_MPC 100680321;
BA_ "GenSigStartValue" SG_ 2432639871 AnglRt_VehObj3_Cval_MPC 65535;
BA_ "FlexKomSigStartValue" SG_ 2432639871 AnglRt_VehObj3_Cval_MPC "06F0FFFFFFFFFFFFh";
BA_ "GenSigCycleTime" SG_ 2432639871 AnglRt_VehObj3_Cval_MPC 50;
BA_ "GenSigSNA" SG_ 2432639871 SclFctr_VehObj3_Cval_MPC "FFFFh";
BA_ "FlexKomIsMotorola" SG_ 2432639871 SclFctr_VehObj3_Cval_MPC 1;
BA_ "FlexKomComment" SG_ 2432639871 SclFctr_VehObj3_Cval_MPC "MPC_C39_Pkt";
BA_ "FlexKomSigName" SG_ 2432639871 SclFctr_VehObj3_Cval_MPC "MPC_C39_Pkt";
BA_ "FlexKomSigLaenge" SG_ 2432639871 SclFctr_VehObj3_Cval_MPC 64;
BA_ "FlexKomSigStartPos" SG_ 2432639871 SclFctr_VehObj3_Cval_MPC 7;
BA_ "FlexKomSID" SG_ 2432639871 SclFctr_VehObj3_Cval_MPC 100680321;
BA_ "GenSigStartValue" SG_ 2432639871 SclFctr_VehObj3_Cval_MPC 65535;
BA_ "FlexKomSigStartValue" SG_ 2432639871 SclFctr_VehObj3_Cval_MPC "06F0FFFFFFFFFFFFh";
BA_ "GenSigCycleTime" SG_ 2432639871 SclFctr_VehObj3_Cval_MPC 50;
BA_ "GenSigSNA" SG_ 2498756875 ABS_Actv_Stat "3h";
BA_ "FlexKomIsMotorola" SG_ 2498756875 ABS_Actv_Stat 1;
BA_ "FlexKomComment" SG_ 2498756875 ABS_Actv_Stat "EBC1 Packet";
BA_ "FlexKomSigName" SG_ 2498756875 ABS_Actv_Stat "EBC1_Pkt";
BA_ "FlexKomSigLaenge" SG_ 2498756875 ABS_Actv_Stat 64;
BA_ "FlexKomSigStartPos" SG_ 2498756875 ABS_Actv_Stat 7;
BA_ "FlexKomSID" SG_ 2498756875 ABS_Actv_Stat 100663771;
BA_ "GenSigTimeout_MPC2" SG_ 2498756875 ABS_Actv_Stat 1050;
BA_ "GenSigStartValue" SG_ 2498756875 ABS_Actv_Stat 3;
BA_ "FlexKomSigStartValue" SG_ 2498756875 ABS_Actv_Stat "FFFFFFFFFFFFFFFFh";
BA_ "GenSigCycleTime" SG_ 2498756875 ABS_Actv_Stat 100;
BA_ "GenSigSNA" SG_ 2498756875 BrkPdlPosn_Cval "FFh";
BA_ "FlexKomIsMotorola" SG_ 2498756875 BrkPdlPosn_Cval 1;
BA_ "FlexKomComment" SG_ 2498756875 BrkPdlPosn_Cval "EBC1 Packet";
BA_ "FlexKomSigName" SG_ 2498756875 BrkPdlPosn_Cval "EBC1_Pkt";
BA_ "FlexKomSigLaenge" SG_ 2498756875 BrkPdlPosn_Cval 64;
BA_ "FlexKomSigStartPos" SG_ 2498756875 BrkPdlPosn_Cval 7;
BA_ "FlexKomSID" SG_ 2498756875 BrkPdlPosn_Cval 100663771;
BA_ "GenSigTimeout_MPC2" SG_ 2498756875 BrkPdlPosn_Cval 1050;
BA_ "GenSigStartValue" SG_ 2498756875 BrkPdlPosn_Cval 255;
BA_ "FlexKomSigStartValue" SG_ 2498756875 BrkPdlPosn_Cval "FFFFFFFFFFFFFFFFh";
BA_ "GenSigCycleTime" SG_ 2498756875 BrkPdlPosn_Cval 100;
BA_ "GenSigSNA" SG_ 2499696943 RelLvlFAxL_Cval "FFFFh";
BA_ "FlexKomIsMotorola" SG_ 2499696943 RelLvlFAxL_Cval 1;
BA_ "FlexKomComment" SG_ 2499696943 RelLvlFAxL_Cval "Relative Level Front Axle Current value";
BA_ "FlexKomSigName" SG_ 2499696943 RelLvlFAxL_Cval "RelLvlFAx_Cval";
BA_ "FlexKomSigLaenge" SG_ 2499696943 RelLvlFAxL_Cval 32;
BA_ "FlexKomSigStartPos" SG_ 2499696943 RelLvlFAxL_Cval 7;
BA_ "FlexKomSID" SG_ 2499696943 RelLvlFAxL_Cval 100663699;
BA_ "GenSigTimeout_MPC2" SG_ 2499696943 RelLvlFAxL_Cval 1050;
BA_ "GenSigStartValue" SG_ 2499696943 RelLvlFAxL_Cval 65535;
BA_ "FlexKomSigStartValue" SG_ 2499696943 RelLvlFAxL_Cval "FFFFFFFFh";
BA_ "GenSigCycleTime" SG_ 2499696943 RelLvlFAxL_Cval 100;
BA_ "GenSigSNA" SG_ 2499696943 RelLvlFAxR_Cval "FFFFh";
BA_ "FlexKomIsMotorola" SG_ 2499696943 RelLvlFAxR_Cval 1;
BA_ "FlexKomComment" SG_ 2499696943 RelLvlFAxR_Cval "Relative Level Front Axle Current value";
BA_ "FlexKomSigName" SG_ 2499696943 RelLvlFAxR_Cval "RelLvlFAx_Cval";
BA_ "FlexKomSigLaenge" SG_ 2499696943 RelLvlFAxR_Cval 32;
BA_ "FlexKomSigStartPos" SG_ 2499696943 RelLvlFAxR_Cval 7;
BA_ "FlexKomSID" SG_ 2499696943 RelLvlFAxR_Cval 100663699;
BA_ "GenSigTimeout_MPC2" SG_ 2499696943 RelLvlFAxR_Cval 1050;
BA_ "GenSigStartValue" SG_ 2499696943 RelLvlFAxR_Cval 65535;
BA_ "FlexKomSigStartValue" SG_ 2499696943 RelLvlFAxR_Cval "FFFFFFFFh";
BA_ "GenSigCycleTime" SG_ 2499696943 RelLvlFAxR_Cval 100;
BA_ "GenSigSNA" SG_ 2499696943 RelLvlRAxL_Cval "FFFFh";
BA_ "FlexKomIsMotorola" SG_ 2499696943 RelLvlRAxL_Cval 1;
BA_ "FlexKomComment" SG_ 2499696943 RelLvlRAxL_Cval "Relative Level Rear Axle Current value";
BA_ "FlexKomSigName" SG_ 2499696943 RelLvlRAxL_Cval "RelLvlRAx_Cval";
BA_ "FlexKomSigLaenge" SG_ 2499696943 RelLvlRAxL_Cval 32;
BA_ "FlexKomSigStartPos" SG_ 2499696943 RelLvlRAxL_Cval 39;
BA_ "FlexKomSID" SG_ 2499696943 RelLvlRAxL_Cval 100663700;
BA_ "GenSigTimeout_MPC2" SG_ 2499696943 RelLvlRAxL_Cval 1050;
BA_ "GenSigStartValue" SG_ 2499696943 RelLvlRAxL_Cval 65535;
BA_ "FlexKomSigStartValue" SG_ 2499696943 RelLvlRAxL_Cval "FFFFFFFFh";
BA_ "GenSigCycleTime" SG_ 2499696943 RelLvlRAxL_Cval 100;
BA_ "GenSigSNA" SG_ 2499696943 RelLvlRAxR_Cval "FFFFh";
BA_ "FlexKomIsMotorola" SG_ 2499696943 RelLvlRAxR_Cval 1;
BA_ "FlexKomComment" SG_ 2499696943 RelLvlRAxR_Cval "Relative Level Rear Axle Current value";
BA_ "FlexKomSigName" SG_ 2499696943 RelLvlRAxR_Cval "RelLvlRAx_Cval";
BA_ "FlexKomSigLaenge" SG_ 2499696943 RelLvlRAxR_Cval 32;
BA_ "FlexKomSigStartPos" SG_ 2499696943 RelLvlRAxR_Cval 39;
BA_ "FlexKomSID" SG_ 2499696943 RelLvlRAxR_Cval 100663700;
BA_ "GenSigTimeout_MPC2" SG_ 2499696943 RelLvlRAxR_Cval 1050;
BA_ "GenSigStartValue" SG_ 2499696943 RelLvlRAxR_Cval 65535;
BA_ "FlexKomSigStartValue" SG_ 2499696943 RelLvlRAxR_Cval "FFFFFFFFh";
BA_ "GenSigCycleTime" SG_ 2499696943 RelLvlRAxR_Cval 100;
BA_ "GenSigSNA" SG_ 2499702539 RoadCurv_Cval "FFFFh";
BA_ "FlexKomIsMotorola" SG_ 2499702539 RoadCurv_Cval 1;
BA_ "FlexKomComment" SG_ 2499702539 RoadCurv_Cval "Road Curvature Current value";
BA_ "FlexKomSigName" SG_ 2499702539 RoadCurv_Cval "RoadCurvature";
BA_ "FlexKomSigLaenge" SG_ 2499702539 RoadCurv_Cval 16;
BA_ "FlexKomSigStartPos" SG_ 2499702539 RoadCurv_Cval 39;
BA_ "FlexKomSID" SG_ 2499702539 RoadCurv_Cval 100663787;
BA_ "GenSigTimeout_MPC2" SG_ 2499702539 RoadCurv_Cval 1050;
BA_ "GenSigStartValue" SG_ 2499702539 RoadCurv_Cval 65535;
BA_ "FlexKomSigStartValue" SG_ 2499702539 RoadCurv_Cval "FFFFh";
BA_ "GenSigCycleTime" SG_ 2499702539 RoadCurv_Cval 100;
BA_ "GenSigSNA" SG_ 2499735808 VehSpd_Cval_CPC "FFFFh";
BA_ "FlexKomIsMotorola" SG_ 2499735808 VehSpd_Cval_CPC 1;
BA_ "FlexKomComment" SG_ 2499735808 VehSpd_Cval_CPC "Complete CCVS Message";
BA_ "FlexKomSigName" SG_ 2499735808 VehSpd_Cval_CPC "CCVS_Pkt";
BA_ "FlexKomSigLaenge" SG_ 2499735808 VehSpd_Cval_CPC 64;
BA_ "FlexKomSigStartPos" SG_ 2499735808 VehSpd_Cval_CPC 7;
BA_ "FlexKomSID" SG_ 2499735808 VehSpd_Cval_CPC 100664004;
BA_ "GenSigTimeout_MPC2" SG_ 2499735808 VehSpd_Cval_CPC 1050;
BA_ "GenSigStartValue" SG_ 2499735808 VehSpd_Cval_CPC 65535;
BA_ "FlexKomSigStartValue" SG_ 2499735808 VehSpd_Cval_CPC "FFFFFFFFFFFFFFFFh";
BA_ "GenSigCycleTime" SG_ 2499735808 VehSpd_Cval_CPC 100;
BA_ "GenSigSNA" SG_ 2499735808 CC_Actv_Stat "3h";
BA_ "FlexKomIsMotorola" SG_ 2499735808 CC_Actv_Stat 1;
BA_ "FlexKomComment" SG_ 2499735808 CC_Actv_Stat "Complete CCVS Message";
BA_ "FlexKomSigName" SG_ 2499735808 CC_Actv_Stat "CCVS_Pkt";
BA_ "FlexKomSigLaenge" SG_ 2499735808 CC_Actv_Stat 64;
BA_ "FlexKomSigStartPos" SG_ 2499735808 CC_Actv_Stat 7;
BA_ "FlexKomSID" SG_ 2499735808 CC_Actv_Stat 100664004;
BA_ "GenSigTimeout_MPC2" SG_ 2499735808 CC_Actv_Stat 1050;
BA_ "GenSigStartValue" SG_ 2499735808 CC_Actv_Stat 3;
BA_ "FlexKomSigStartValue" SG_ 2499735808 CC_Actv_Stat "FFFFFFFFFFFFFFFFh";
BA_ "GenSigCycleTime" SG_ 2499735808 CC_Actv_Stat 100;
BA_ "GenSigSNA" SG_ 2499739775 Rsrv_CRC_SG_MPC_C02_Pkt "0h";
BA_ "FlexKomIsMotorola" SG_ 2499739775 Rsrv_CRC_SG_MPC_C02_Pkt 1;
BA_ "FlexKomComment" SG_ 2499739775 Rsrv_CRC_SG_MPC_C02_Pkt "MPC_C02_Pkt";
BA_ "FlexKomSigName" SG_ 2499739775 Rsrv_CRC_SG_MPC_C02_Pkt "MPC_C02_Pkt";
BA_ "FlexKomSigLaenge" SG_ 2499739775 Rsrv_CRC_SG_MPC_C02_Pkt 64;
BA_ "FlexKomSigStartPos" SG_ 2499739775 Rsrv_CRC_SG_MPC_C02_Pkt 7;
BA_ "FlexKomSID" SG_ 2499739775 Rsrv_CRC_SG_MPC_C02_Pkt 100677017;
BA_ "FlexKomSigStartValue" SG_ 2499739775 Rsrv_CRC_SG_MPC_C02_Pkt "00F00000000000FFh";
BA_ "GenSigCycleTime" SG_ 2499739775 Rsrv_CRC_SG_MPC_C02_Pkt 100;
BA_ "GenSigSNA" SG_ 2499739775 Rsrv_SQC_SG_MPC_C02_Pkt "0h";
BA_ "FlexKomIsMotorola" SG_ 2499739775 Rsrv_SQC_SG_MPC_C02_Pkt 1;
BA_ "FlexKomComment" SG_ 2499739775 Rsrv_SQC_SG_MPC_C02_Pkt "MPC_C02_Pkt";
BA_ "FlexKomSigName" SG_ 2499739775 Rsrv_SQC_SG_MPC_C02_Pkt "MPC_C02_Pkt";
BA_ "FlexKomSigLaenge" SG_ 2499739775 Rsrv_SQC_SG_MPC_C02_Pkt 64;
BA_ "FlexKomSigStartPos" SG_ 2499739775 Rsrv_SQC_SG_MPC_C02_Pkt 7;
BA_ "FlexKomSID" SG_ 2499739775 Rsrv_SQC_SG_MPC_C02_Pkt 100677017;
BA_ "FlexKomSigStartValue" SG_ 2499739775 Rsrv_SQC_SG_MPC_C02_Pkt "00F00000000000FFh";
BA_ "GenSigCycleTime" SG_ 2499739775 Rsrv_SQC_SG_MPC_C02_Pkt 100;
BA_ "GenSigSNA" SG_ 2499739775 DispCloAA_Rq_MPC "3h";
BA_ "FlexKomIsMotorola" SG_ 2499739775 DispCloAA_Rq_MPC 1;
BA_ "FlexKomComment" SG_ 2499739775 DispCloAA_Rq_MPC "MPC_C02_Pkt";
BA_ "FlexKomSigName" SG_ 2499739775 DispCloAA_Rq_MPC "MPC_C02_Pkt";
BA_ "FlexKomSigLaenge" SG_ 2499739775 DispCloAA_Rq_MPC 64;
BA_ "FlexKomSigStartPos" SG_ 2499739775 DispCloAA_Rq_MPC 7;
BA_ "FlexKomSID" SG_ 2499739775 DispCloAA_Rq_MPC 100677017;
BA_ "GenSigStartValue" SG_ 2499739775 DispCloAA_Rq_MPC 3;
BA_ "FlexKomSigStartValue" SG_ 2499739775 DispCloAA_Rq_MPC "00F00000000000FFh";
BA_ "GenSigCycleTime" SG_ 2499739775 DispCloAA_Rq_MPC 100;
BA_ "GenSigSNA" SG_ 2499739775 Lvl0_AA_Cval_MPC "Fh";
BA_ "FlexKomIsMotorola" SG_ 2499739775 Lvl0_AA_Cval_MPC 1;
BA_ "FlexKomComment" SG_ 2499739775 Lvl0_AA_Cval_MPC "MPC_C02_Pkt";
BA_ "FlexKomSigName" SG_ 2499739775 Lvl0_AA_Cval_MPC "MPC_C02_Pkt";
BA_ "FlexKomSigLaenge" SG_ 2499739775 Lvl0_AA_Cval_MPC 64;
BA_ "FlexKomSigStartPos" SG_ 2499739775 Lvl0_AA_Cval_MPC 7;
BA_ "FlexKomSID" SG_ 2499739775 Lvl0_AA_Cval_MPC 100677017;
BA_ "FlexKomSigStartValue" SG_ 2499739775 Lvl0_AA_Cval_MPC "00F00000000000FFh";
BA_ "GenSigCycleTime" SG_ 2499739775 Lvl0_AA_Cval_MPC 100;
BA_ "GenSigSNA" SG_ 2499739775 Lvl1_AA_Cval_MPC "Fh";
BA_ "FlexKomIsMotorola" SG_ 2499739775 Lvl1_AA_Cval_MPC 1;
BA_ "FlexKomComment" SG_ 2499739775 Lvl1_AA_Cval_MPC "MPC_C02_Pkt";
BA_ "FlexKomSigName" SG_ 2499739775 Lvl1_AA_Cval_MPC "MPC_C02_Pkt";
BA_ "FlexKomSigLaenge" SG_ 2499739775 Lvl1_AA_Cval_MPC 64;
BA_ "FlexKomSigStartPos" SG_ 2499739775 Lvl1_AA_Cval_MPC 7;
BA_ "FlexKomSID" SG_ 2499739775 Lvl1_AA_Cval_MPC 100677017;
BA_ "FlexKomSigStartValue" SG_ 2499739775 Lvl1_AA_Cval_MPC "00F00000000000FFh";
BA_ "GenSigCycleTime" SG_ 2499739775 Lvl1_AA_Cval_MPC 100;
BA_ "GenSigSNA" SG_ 2499739775 Lvl2_AA_Cval_MPC "Fh";
BA_ "FlexKomIsMotorola" SG_ 2499739775 Lvl2_AA_Cval_MPC 1;
BA_ "FlexKomComment" SG_ 2499739775 Lvl2_AA_Cval_MPC "MPC_C02_Pkt";
BA_ "FlexKomSigName" SG_ 2499739775 Lvl2_AA_Cval_MPC "MPC_C02_Pkt";
BA_ "FlexKomSigLaenge" SG_ 2499739775 Lvl2_AA_Cval_MPC 64;
BA_ "FlexKomSigStartPos" SG_ 2499739775 Lvl2_AA_Cval_MPC 7;
BA_ "FlexKomSID" SG_ 2499739775 Lvl2_AA_Cval_MPC 100677017;
BA_ "FlexKomSigStartValue" SG_ 2499739775 Lvl2_AA_Cval_MPC "00F00000000000FFh";
BA_ "GenSigCycleTime" SG_ 2499739775 Lvl2_AA_Cval_MPC 100;
BA_ "GenSigSNA" SG_ 2499739775 Lvl3_AA_Cval_MPC "Fh";
BA_ "FlexKomIsMotorola" SG_ 2499739775 Lvl3_AA_Cval_MPC 1;
BA_ "FlexKomComment" SG_ 2499739775 Lvl3_AA_Cval_MPC "MPC_C02_Pkt";
BA_ "FlexKomSigName" SG_ 2499739775 Lvl3_AA_Cval_MPC "MPC_C02_Pkt";
BA_ "FlexKomSigLaenge" SG_ 2499739775 Lvl3_AA_Cval_MPC 64;
BA_ "FlexKomSigStartPos" SG_ 2499739775 Lvl3_AA_Cval_MPC 7;
BA_ "FlexKomSID" SG_ 2499739775 Lvl3_AA_Cval_MPC 100677017;
BA_ "FlexKomSigStartValue" SG_ 2499739775 Lvl3_AA_Cval_MPC "00F00000000000FFh";
BA_ "GenSigCycleTime" SG_ 2499739775 Lvl3_AA_Cval_MPC 100;
BA_ "GenSigSNA" SG_ 2499739775 Lvl4_AA_Cval_MPC "Fh";
BA_ "FlexKomIsMotorola" SG_ 2499739775 Lvl4_AA_Cval_MPC 1;
BA_ "FlexKomComment" SG_ 2499739775 Lvl4_AA_Cval_MPC "MPC_C02_Pkt";
BA_ "FlexKomSigName" SG_ 2499739775 Lvl4_AA_Cval_MPC "MPC_C02_Pkt";
BA_ "FlexKomSigLaenge" SG_ 2499739775 Lvl4_AA_Cval_MPC 64;
BA_ "FlexKomSigStartPos" SG_ 2499739775 Lvl4_AA_Cval_MPC 7;
BA_ "FlexKomSID" SG_ 2499739775 Lvl4_AA_Cval_MPC 100677017;
BA_ "FlexKomSigStartValue" SG_ 2499739775 Lvl4_AA_Cval_MPC "00F00000000000FFh";
BA_ "GenSigCycleTime" SG_ 2499739775 Lvl4_AA_Cval_MPC 100;
BA_ "GenSigSNA" SG_ 2499739775 Lvl5_AA_Cval_MPC "Fh";
BA_ "FlexKomIsMotorola" SG_ 2499739775 Lvl5_AA_Cval_MPC 1;
BA_ "FlexKomComment" SG_ 2499739775 Lvl5_AA_Cval_MPC "MPC_C02_Pkt";
BA_ "FlexKomSigName" SG_ 2499739775 Lvl5_AA_Cval_MPC "MPC_C02_Pkt";
BA_ "FlexKomSigLaenge" SG_ 2499739775 Lvl5_AA_Cval_MPC 64;
BA_ "FlexKomSigStartPos" SG_ 2499739775 Lvl5_AA_Cval_MPC 7;
BA_ "FlexKomSID" SG_ 2499739775 Lvl5_AA_Cval_MPC 100677017;
BA_ "FlexKomSigStartValue" SG_ 2499739775 Lvl5_AA_Cval_MPC "00F00000000000FFh";
BA_ "GenSigCycleTime" SG_ 2499739775 Lvl5_AA_Cval_MPC 100;
BA_ "GenSigSNA" SG_ 2499739775 Lvl6_AA_Cval_MPC "Fh";
BA_ "FlexKomIsMotorola" SG_ 2499739775 Lvl6_AA_Cval_MPC 1;
BA_ "FlexKomComment" SG_ 2499739775 Lvl6_AA_Cval_MPC "MPC_C02_Pkt";
BA_ "FlexKomSigName" SG_ 2499739775 Lvl6_AA_Cval_MPC "MPC_C02_Pkt";
BA_ "FlexKomSigLaenge" SG_ 2499739775 Lvl6_AA_Cval_MPC 64;
BA_ "FlexKomSigStartPos" SG_ 2499739775 Lvl6_AA_Cval_MPC 7;
BA_ "FlexKomSID" SG_ 2499739775 Lvl6_AA_Cval_MPC 100677017;
BA_ "FlexKomSigStartValue" SG_ 2499739775 Lvl6_AA_Cval_MPC "00F00000000000FFh";
BA_ "GenSigCycleTime" SG_ 2499739775 Lvl6_AA_Cval_MPC 100;
BA_ "GenSigSNA" SG_ 2499739775 Lvl7_AA_Cval_MPC "Fh";
BA_ "FlexKomIsMotorola" SG_ 2499739775 Lvl7_AA_Cval_MPC 1;
BA_ "FlexKomComment" SG_ 2499739775 Lvl7_AA_Cval_MPC "MPC_C02_Pkt";
BA_ "FlexKomSigName" SG_ 2499739775 Lvl7_AA_Cval_MPC "MPC_C02_Pkt";
BA_ "FlexKomSigLaenge" SG_ 2499739775 Lvl7_AA_Cval_MPC 64;
BA_ "FlexKomSigStartPos" SG_ 2499739775 Lvl7_AA_Cval_MPC 7;
BA_ "FlexKomSID" SG_ 2499739775 Lvl7_AA_Cval_MPC 100677017;
BA_ "FlexKomSigStartValue" SG_ 2499739775 Lvl7_AA_Cval_MPC "00F00000000000FFh";
BA_ "GenSigCycleTime" SG_ 2499739775 Lvl7_AA_Cval_MPC 100;
BA_ "GenSigSNA" SG_ 2499739775 Lvl8_AA_Cval_MPC "Fh";
BA_ "FlexKomIsMotorola" SG_ 2499739775 Lvl8_AA_Cval_MPC 1;
BA_ "FlexKomComment" SG_ 2499739775 Lvl8_AA_Cval_MPC "MPC_C02_Pkt";
BA_ "FlexKomSigName" SG_ 2499739775 Lvl8_AA_Cval_MPC "MPC_C02_Pkt";
BA_ "FlexKomSigLaenge" SG_ 2499739775 Lvl8_AA_Cval_MPC 64;
BA_ "FlexKomSigStartPos" SG_ 2499739775 Lvl8_AA_Cval_MPC 7;
BA_ "FlexKomSID" SG_ 2499739775 Lvl8_AA_Cval_MPC 100677017;
BA_ "FlexKomSigStartValue" SG_ 2499739775 Lvl8_AA_Cval_MPC "00F00000000000FFh";
BA_ "GenSigCycleTime" SG_ 2499739775 Lvl8_AA_Cval_MPC 100;
BA_ "GenSigSNA" SG_ 2499739775 Lvl9_AA_Cval_MPC "Fh";
BA_ "FlexKomIsMotorola" SG_ 2499739775 Lvl9_AA_Cval_MPC 1;
BA_ "FlexKomComment" SG_ 2499739775 Lvl9_AA_Cval_MPC "MPC_C02_Pkt";
BA_ "FlexKomSigName" SG_ 2499739775 Lvl9_AA_Cval_MPC "MPC_C02_Pkt";
BA_ "FlexKomSigLaenge" SG_ 2499739775 Lvl9_AA_Cval_MPC 64;
BA_ "FlexKomSigStartPos" SG_ 2499739775 Lvl9_AA_Cval_MPC 7;
BA_ "FlexKomSID" SG_ 2499739775 Lvl9_AA_Cval_MPC 100677017;
BA_ "FlexKomSigStartValue" SG_ 2499739775 Lvl9_AA_Cval_MPC "00F00000000000FFh";
BA_ "GenSigCycleTime" SG_ 2499739775 Lvl9_AA_Cval_MPC 100;
BA_ "GenSigSNA" SG_ 2499739775 AA_Enbl_Stat_MPC "3h";
BA_ "FlexKomIsMotorola" SG_ 2499739775 AA_Enbl_Stat_MPC 1;
BA_ "FlexKomComment" SG_ 2499739775 AA_Enbl_Stat_MPC "MPC_C02_Pkt";
BA_ "FlexKomSigName" SG_ 2499739775 AA_Enbl_Stat_MPC "MPC_C02_Pkt";
BA_ "FlexKomSigLaenge" SG_ 2499739775 AA_Enbl_Stat_MPC 64;
BA_ "FlexKomSigStartPos" SG_ 2499739775 AA_Enbl_Stat_MPC 7;
BA_ "FlexKomSID" SG_ 2499739775 AA_Enbl_Stat_MPC 100677017;
BA_ "GenSigStartValue" SG_ 2499739775 AA_Enbl_Stat_MPC 3;
BA_ "FlexKomSigStartValue" SG_ 2499739775 AA_Enbl_Stat_MPC "00F00000000000FFh";
BA_ "GenSigCycleTime" SG_ 2499739775 AA_Enbl_Stat_MPC 100;
BA_ "GenSigSNA" SG_ 2499739775 AA_Fkt_Stat_MPC "3h";
BA_ "FlexKomIsMotorola" SG_ 2499739775 AA_Fkt_Stat_MPC 1;
BA_ "FlexKomComment" SG_ 2499739775 AA_Fkt_Stat_MPC "MPC_C02_Pkt";
BA_ "FlexKomSigName" SG_ 2499739775 AA_Fkt_Stat_MPC "MPC_C02_Pkt";
BA_ "FlexKomSigLaenge" SG_ 2499739775 AA_Fkt_Stat_MPC 64;
BA_ "FlexKomSigStartPos" SG_ 2499739775 AA_Fkt_Stat_MPC 7;
BA_ "FlexKomSID" SG_ 2499739775 AA_Fkt_Stat_MPC 100677017;
BA_ "GenSigStartValue" SG_ 2499739775 AA_Fkt_Stat_MPC 3;
BA_ "FlexKomSigStartValue" SG_ 2499739775 AA_Fkt_Stat_MPC "00F00000000000FFh";
BA_ "GenSigCycleTime" SG_ 2499739775 AA_Fkt_Stat_MPC 100;
BA_ "GenSigSNA" SG_ 2499739775 Warn0_AA_Rq_MPC "3h";
BA_ "FlexKomIsMotorola" SG_ 2499739775 Warn0_AA_Rq_MPC 1;
BA_ "FlexKomComment" SG_ 2499739775 Warn0_AA_Rq_MPC "MPC_C02_Pkt";
BA_ "FlexKomSigName" SG_ 2499739775 Warn0_AA_Rq_MPC "MPC_C02_Pkt";
BA_ "FlexKomSigLaenge" SG_ 2499739775 Warn0_AA_Rq_MPC 64;
BA_ "FlexKomSigStartPos" SG_ 2499739775 Warn0_AA_Rq_MPC 7;
BA_ "FlexKomSID" SG_ 2499739775 Warn0_AA_Rq_MPC 100677017;
BA_ "GenSigStartValue" SG_ 2499739775 Warn0_AA_Rq_MPC 3;
BA_ "FlexKomSigStartValue" SG_ 2499739775 Warn0_AA_Rq_MPC "00F00000000000FFh";
BA_ "GenSigCycleTime" SG_ 2499739775 Warn0_AA_Rq_MPC 100;
BA_ "GenSigSNA" SG_ 2499739775 Warn1_AA_Rq_MPC "3h";
BA_ "FlexKomIsMotorola" SG_ 2499739775 Warn1_AA_Rq_MPC 1;
BA_ "FlexKomComment" SG_ 2499739775 Warn1_AA_Rq_MPC "MPC_C02_Pkt";
BA_ "FlexKomSigName" SG_ 2499739775 Warn1_AA_Rq_MPC "MPC_C02_Pkt";
BA_ "FlexKomSigLaenge" SG_ 2499739775 Warn1_AA_Rq_MPC 64;
BA_ "FlexKomSigStartPos" SG_ 2499739775 Warn1_AA_Rq_MPC 7;
BA_ "FlexKomSID" SG_ 2499739775 Warn1_AA_Rq_MPC 100677017;
BA_ "GenSigStartValue" SG_ 2499739775 Warn1_AA_Rq_MPC 3;
BA_ "FlexKomSigStartValue" SG_ 2499739775 Warn1_AA_Rq_MPC "00F00000000000FFh";
BA_ "GenSigCycleTime" SG_ 2499739775 Warn1_AA_Rq_MPC 100;
BA_ "GenSigSNA" SG_ 2499739915 ROP_EngCtrlActv2_Stat "3h";
BA_ "FlexKomIsMotorola" SG_ 2499739915 ROP_EngCtrlActv2_Stat 1;
BA_ "FlexKomComment" SG_ 2499739915 ROP_EngCtrlActv2_Stat "ROP Engine Brake Control active Current state";
BA_ "FlexKomSigName" SG_ 2499739915 ROP_EngCtrlActv2_Stat "ROP_EngBrkCtrlActv";
BA_ "FlexKomSigLaenge" SG_ 2499739915 ROP_EngCtrlActv2_Stat 4;
BA_ "FlexKomSigStartPos" SG_ 2499739915 ROP_EngCtrlActv2_Stat 27;
BA_ "FlexKomSID" SG_ 2499739915 ROP_EngCtrlActv2_Stat 100663967;
BA_ "GenSigTimeout_MPC2" SG_ 2499739915 ROP_EngCtrlActv2_Stat 1050;
BA_ "GenSigStartValue" SG_ 2499739915 ROP_EngCtrlActv2_Stat 3;
BA_ "FlexKomSigStartValue" SG_ 2499739915 ROP_EngCtrlActv2_Stat "0Fh";
BA_ "GenSigCycleTime" SG_ 2499739915 ROP_EngCtrlActv2_Stat 100;
BA_ "GenSigSNA" SG_ 2499739915 ROP_BrkCtrlActv2_Stat "3h";
BA_ "FlexKomIsMotorola" SG_ 2499739915 ROP_BrkCtrlActv2_Stat 1;
BA_ "FlexKomComment" SG_ 2499739915 ROP_BrkCtrlActv2_Stat "ROP Engine Brake Control active Current state";
BA_ "FlexKomSigName" SG_ 2499739915 ROP_BrkCtrlActv2_Stat "ROP_EngBrkCtrlActv";
BA_ "FlexKomSigLaenge" SG_ 2499739915 ROP_BrkCtrlActv2_Stat 4;
BA_ "FlexKomSigStartPos" SG_ 2499739915 ROP_BrkCtrlActv2_Stat 27;
BA_ "FlexKomSID" SG_ 2499739915 ROP_BrkCtrlActv2_Stat 100663967;
BA_ "GenSigTimeout_MPC2" SG_ 2499739915 ROP_BrkCtrlActv2_Stat 1050;
BA_ "GenSigStartValue" SG_ 2499739915 ROP_BrkCtrlActv2_Stat 3;
BA_ "FlexKomSigStartValue" SG_ 2499739915 ROP_BrkCtrlActv2_Stat "0Fh";
BA_ "GenSigCycleTime" SG_ 2499739915 ROP_BrkCtrlActv2_Stat 100;
BA_ "GenSigSNA" SG_ 2499739915 YC_EngCtrlActv2_Stat "3h";
BA_ "FlexKomIsMotorola" SG_ 2499739915 YC_EngCtrlActv2_Stat 1;
BA_ "FlexKomComment" SG_ 2499739915 YC_EngCtrlActv2_Stat "YC Engine Brake Control active Current state";
BA_ "FlexKomSigName" SG_ 2499739915 YC_EngCtrlActv2_Stat "YC_EngBrkCtrlActv";
BA_ "FlexKomSigLaenge" SG_ 2499739915 YC_EngCtrlActv2_Stat 4;
BA_ "FlexKomSigStartPos" SG_ 2499739915 YC_EngCtrlActv2_Stat 31;
BA_ "FlexKomSID" SG_ 2499739915 YC_EngCtrlActv2_Stat 100663968;
BA_ "GenSigTimeout_MPC2" SG_ 2499739915 YC_EngCtrlActv2_Stat 1050;
BA_ "GenSigStartValue" SG_ 2499739915 YC_EngCtrlActv2_Stat 3;
BA_ "FlexKomSigStartValue" SG_ 2499739915 YC_EngCtrlActv2_Stat "0Fh";
BA_ "GenSigCycleTime" SG_ 2499739915 YC_EngCtrlActv2_Stat 100;
BA_ "GenSigSNA" SG_ 2499739915 YC_BrkCtrlActv2_Stat "3h";
BA_ "FlexKomIsMotorola" SG_ 2499739915 YC_BrkCtrlActv2_Stat 1;
BA_ "FlexKomComment" SG_ 2499739915 YC_BrkCtrlActv2_Stat "YC Engine Brake Control active Current state";
BA_ "FlexKomSigName" SG_ 2499739915 YC_BrkCtrlActv2_Stat "YC_EngBrkCtrlActv";
BA_ "FlexKomSigLaenge" SG_ 2499739915 YC_BrkCtrlActv2_Stat 4;
BA_ "FlexKomSigStartPos" SG_ 2499739915 YC_BrkCtrlActv2_Stat 31;
BA_ "FlexKomSID" SG_ 2499739915 YC_BrkCtrlActv2_Stat 100663968;
BA_ "GenSigTimeout_MPC2" SG_ 2499739915 YC_BrkCtrlActv2_Stat 1050;
BA_ "GenSigStartValue" SG_ 2499739915 YC_BrkCtrlActv2_Stat 3;
BA_ "FlexKomSigStartValue" SG_ 2499739915 YC_BrkCtrlActv2_Stat "0Fh";
BA_ "GenSigCycleTime" SG_ 2499739915 YC_BrkCtrlActv2_Stat 100;
BA_ "GenSigSNA" SG_ 2499739915 TrlrEstm_Stat_BS "3h";
BA_ "FlexKomIsMotorola" SG_ 2499739915 TrlrEstm_Stat_BS 1;
BA_ "FlexKomComment" SG_ 2499739915 TrlrEstm_Stat_BS "Trailer Estimation Current state BS";
BA_ "FlexKomSigName" SG_ 2499739915 TrlrEstm_Stat_BS "TrlrEstm_Stat_BS";
BA_ "FlexKomSigLaenge" SG_ 2499739915 TrlrEstm_Stat_BS 2;
BA_ "FlexKomSigStartPos" SG_ 2499739915 TrlrEstm_Stat_BS 39;
BA_ "FlexKomSID" SG_ 2499739915 TrlrEstm_Stat_BS 100677489;
BA_ "GenSigTimeout_MPC2" SG_ 2499739915 TrlrEstm_Stat_BS 1050;
BA_ "GenSigStartValue" SG_ 2499739915 TrlrEstm_Stat_BS 3;
BA_ "FlexKomSigStartValue" SG_ 2499739915 TrlrEstm_Stat_BS "03h";
BA_ "GenSigCycleTime" SG_ 2499739915 TrlrEstm_Stat_BS 100;
BA_ "GenSigSNA" SG_ 2499739953 TurnSglSwLt_Rq "3h";
BA_ "FlexKomIsMotorola" SG_ 2499739953 TurnSglSwLt_Rq 1;
BA_ "FlexKomComment" SG_ 2499739953 TurnSglSwLt_Rq "Stalk Switch Left";
BA_ "FlexKomSigName" SG_ 2499739953 TurnSglSwLt_Rq "StSwLt";
BA_ "FlexKomSigLaenge" SG_ 2499739953 TurnSglSwLt_Rq 16;
BA_ "FlexKomSigStartPos" SG_ 2499739953 TurnSglSwLt_Rq 7;
BA_ "FlexKomSID" SG_ 2499739953 TurnSglSwLt_Rq 100664302;
BA_ "GenSigTimeout_MPC2" SG_ 2499739953 TurnSglSwLt_Rq 1050;
BA_ "GenSigStartValue" SG_ 2499739953 TurnSglSwLt_Rq 3;
BA_ "FlexKomSigStartValue" SG_ 2499739953 TurnSglSwLt_Rq "FFFFh";
BA_ "GenSigCycleTime" SG_ 2499739953 TurnSglSwLt_Rq 100;
BA_ "GenSigSendType" SG_ 2499739953 TurnSglSwLt_Rq 5;
BA_ "GenSigSNA" SG_ 2499739953 TurnSglSwRt_Rq "3h";
BA_ "FlexKomIsMotorola" SG_ 2499739953 TurnSglSwRt_Rq 1;
BA_ "FlexKomComment" SG_ 2499739953 TurnSglSwRt_Rq "Stalk Switch Left";
BA_ "FlexKomSigName" SG_ 2499739953 TurnSglSwRt_Rq "StSwLt";
BA_ "FlexKomSigLaenge" SG_ 2499739953 TurnSglSwRt_Rq 16;
BA_ "FlexKomSigStartPos" SG_ 2499739953 TurnSglSwRt_Rq 7;
BA_ "FlexKomSID" SG_ 2499739953 TurnSglSwRt_Rq 100664302;
BA_ "GenSigTimeout_MPC2" SG_ 2499739953 TurnSglSwRt_Rq 1050;
BA_ "GenSigStartValue" SG_ 2499739953 TurnSglSwRt_Rq 3;
BA_ "FlexKomSigStartValue" SG_ 2499739953 TurnSglSwRt_Rq "FFFFh";
BA_ "GenSigCycleTime" SG_ 2499739953 TurnSglSwRt_Rq 100;
BA_ "GenSigSendType" SG_ 2499739953 TurnSglSwRt_Rq 5;
BA_ "GenSigSNA" SG_ 2499739953 WprSw_Rq "Fh";
BA_ "FlexKomIsMotorola" SG_ 2499739953 WprSw_Rq 1;
BA_ "FlexKomComment" SG_ 2499739953 WprSw_Rq "Stalk Switch Left";
BA_ "FlexKomSigName" SG_ 2499739953 WprSw_Rq "StSwLt";
BA_ "FlexKomSigLaenge" SG_ 2499739953 WprSw_Rq 16;
BA_ "FlexKomSigStartPos" SG_ 2499739953 WprSw_Rq 7;
BA_ "FlexKomSID" SG_ 2499739953 WprSw_Rq 100664302;
BA_ "GenSigTimeout_MPC2" SG_ 2499739953 WprSw_Rq 1050;
BA_ "GenSigStartValue" SG_ 2499739953 WprSw_Rq 15;
BA_ "FlexKomSigStartValue" SG_ 2499739953 WprSw_Rq "FFFFh";
BA_ "GenSigCycleTime" SG_ 2499739953 WprSw_Rq 100;
BA_ "GenSigSendType" SG_ 2499739953 WprSw_Rq 5;
BA_ "GenSigSNA" SG_ 2499739953 LDW_Sw_Rq "3h";
BA_ "FlexKomIsMotorola" SG_ 2499739953 LDW_Sw_Rq 1;
BA_ "FlexKomComment" SG_ 2499739953 LDW_Sw_Rq "Lane Departure Warning switch state";
BA_ "FlexKomSigName" SG_ 2499739953 LDW_Sw_Rq "LDW_Sw";
BA_ "FlexKomSigLaenge" SG_ 2499739953 LDW_Sw_Rq 2;
BA_ "FlexKomSigStartPos" SG_ 2499739953 LDW_Sw_Rq 29;
BA_ "FlexKomSID" SG_ 2499739953 LDW_Sw_Rq 100663873;
BA_ "GenSigTimeout_MPC2" SG_ 2499739953 LDW_Sw_Rq 1050;
BA_ "GenSigStartValue" SG_ 2499739953 LDW_Sw_Rq 3;
BA_ "FlexKomSigStartValue" SG_ 2499739953 LDW_Sw_Rq "03h";
BA_ "GenSigCycleTime" SG_ 2499739953 LDW_Sw_Rq 100;
BA_ "GenSigSendType" SG_ 2499739953 LDW_Sw_Rq 5;
BA_ "GenSigSNA" SG_ 2499740031 CRC_SG_MPC_C06_Pkt "D9h";
BA_ "FlexKomIsMotorola" SG_ 2499740031 CRC_SG_MPC_C06_Pkt 1;
BA_ "FlexKomComment" SG_ 2499740031 CRC_SG_MPC_C06_Pkt "MPC_C06_Pkt";
BA_ "FlexKomSigName" SG_ 2499740031 CRC_SG_MPC_C06_Pkt "MPC_C06_Pkt";
BA_ "FlexKomSigLaenge" SG_ 2499740031 CRC_SG_MPC_C06_Pkt 64;
BA_ "FlexKomSigStartPos" SG_ 2499740031 CRC_SG_MPC_C06_Pkt 7;
BA_ "FlexKomSID" SG_ 2499740031 CRC_SG_MPC_C06_Pkt 100679812;
BA_ "GenSigStartValue" SG_ 2499740031 CRC_SG_MPC_C06_Pkt 217;
BA_ "FlexKomSigStartValue" SG_ 2499740031 CRC_SG_MPC_C06_Pkt "D9F0FFFFFFFFFFFFh";
BA_ "GenSigCycleTime" SG_ 2499740031 CRC_SG_MPC_C06_Pkt 100;
BA_ "GenSigSNA" SG_ 2499740031 SQC_SG_MPC_C06_Pkt "0h";
BA_ "FlexKomIsMotorola" SG_ 2499740031 SQC_SG_MPC_C06_Pkt 1;
BA_ "FlexKomComment" SG_ 2499740031 SQC_SG_MPC_C06_Pkt "MPC_C06_Pkt";
BA_ "FlexKomSigName" SG_ 2499740031 SQC_SG_MPC_C06_Pkt "MPC_C06_Pkt";
BA_ "FlexKomSigLaenge" SG_ 2499740031 SQC_SG_MPC_C06_Pkt 64;
BA_ "FlexKomSigStartPos" SG_ 2499740031 SQC_SG_MPC_C06_Pkt 7;
BA_ "FlexKomSID" SG_ 2499740031 SQC_SG_MPC_C06_Pkt 100679812;
BA_ "FlexKomSigStartValue" SG_ 2499740031 SQC_SG_MPC_C06_Pkt "D9F0FFFFFFFFFFFFh";
BA_ "GenSigCycleTime" SG_ 2499740031 SQC_SG_MPC_C06_Pkt 100;
BA_ "GenSigSNA" SG_ 2499740031 SftyMonLaneLt_Stat_MPC "3h";
BA_ "FlexKomIsMotorola" SG_ 2499740031 SftyMonLaneLt_Stat_MPC 1;
BA_ "FlexKomComment" SG_ 2499740031 SftyMonLaneLt_Stat_MPC "MPC_C06_Pkt";
BA_ "FlexKomSigName" SG_ 2499740031 SftyMonLaneLt_Stat_MPC "MPC_C06_Pkt";
BA_ "FlexKomSigLaenge" SG_ 2499740031 SftyMonLaneLt_Stat_MPC 64;
BA_ "FlexKomSigStartPos" SG_ 2499740031 SftyMonLaneLt_Stat_MPC 7;
BA_ "FlexKomSID" SG_ 2499740031 SftyMonLaneLt_Stat_MPC 100679812;
BA_ "GenSigStartValue" SG_ 2499740031 SftyMonLaneLt_Stat_MPC 3;
BA_ "FlexKomSigStartValue" SG_ 2499740031 SftyMonLaneLt_Stat_MPC "D9F0FFFFFFFFFFFFh";
BA_ "GenSigCycleTime" SG_ 2499740031 SftyMonLaneLt_Stat_MPC 100;
BA_ "GenSigSNA" SG_ 2499740031 SftyMonLaneRt_Stat_MPC "3h";
BA_ "FlexKomIsMotorola" SG_ 2499740031 SftyMonLaneRt_Stat_MPC 1;
BA_ "FlexKomComment" SG_ 2499740031 SftyMonLaneRt_Stat_MPC "MPC_C06_Pkt";
BA_ "FlexKomSigName" SG_ 2499740031 SftyMonLaneRt_Stat_MPC "MPC_C06_Pkt";
BA_ "FlexKomSigLaenge" SG_ 2499740031 SftyMonLaneRt_Stat_MPC 64;
BA_ "FlexKomSigStartPos" SG_ 2499740031 SftyMonLaneRt_Stat_MPC 7;
BA_ "FlexKomSID" SG_ 2499740031 SftyMonLaneRt_Stat_MPC 100679812;
BA_ "GenSigStartValue" SG_ 2499740031 SftyMonLaneRt_Stat_MPC 3;
BA_ "FlexKomSigStartValue" SG_ 2499740031 SftyMonLaneRt_Stat_MPC "D9F0FFFFFFFFFFFFh";
BA_ "GenSigCycleTime" SG_ 2499740031 SftyMonLaneRt_Stat_MPC 100;
BA_ "GenSigSNA" SG_ 2499740031 LaneRangeLt_Cval_MPC "FFh";
BA_ "FlexKomIsMotorola" SG_ 2499740031 LaneRangeLt_Cval_MPC 1;
BA_ "FlexKomComment" SG_ 2499740031 LaneRangeLt_Cval_MPC "MPC_C06_Pkt";
BA_ "FlexKomSigName" SG_ 2499740031 LaneRangeLt_Cval_MPC "MPC_C06_Pkt";
BA_ "FlexKomSigLaenge" SG_ 2499740031 LaneRangeLt_Cval_MPC 64;
BA_ "FlexKomSigStartPos" SG_ 2499740031 LaneRangeLt_Cval_MPC 7;
BA_ "FlexKomSID" SG_ 2499740031 LaneRangeLt_Cval_MPC 100679812;
BA_ "GenSigStartValue" SG_ 2499740031 LaneRangeLt_Cval_MPC 255;
BA_ "FlexKomSigStartValue" SG_ 2499740031 LaneRangeLt_Cval_MPC "D9F0FFFFFFFFFFFFh";
BA_ "GenSigCycleTime" SG_ 2499740031 LaneRangeLt_Cval_MPC 100;
BA_ "GenSigSNA" SG_ 2499740031 LaneRangeRt_Cval_MPC "FFh";
BA_ "FlexKomIsMotorola" SG_ 2499740031 LaneRangeRt_Cval_MPC 1;
BA_ "FlexKomComment" SG_ 2499740031 LaneRangeRt_Cval_MPC "MPC_C06_Pkt";
BA_ "FlexKomSigName" SG_ 2499740031 LaneRangeRt_Cval_MPC "MPC_C06_Pkt";
BA_ "FlexKomSigLaenge" SG_ 2499740031 LaneRangeRt_Cval_MPC 64;
BA_ "FlexKomSigStartPos" SG_ 2499740031 LaneRangeRt_Cval_MPC 7;
BA_ "FlexKomSID" SG_ 2499740031 LaneRangeRt_Cval_MPC 100679812;
BA_ "GenSigStartValue" SG_ 2499740031 LaneRangeRt_Cval_MPC 255;
BA_ "FlexKomSigStartValue" SG_ 2499740031 LaneRangeRt_Cval_MPC "D9F0FFFFFFFFFFFFh";
BA_ "GenSigCycleTime" SG_ 2499740031 LaneRangeRt_Cval_MPC 100;
BA_ "GenSigSNA" SG_ 2499740031 LaneCrvtrChgLt_Cval_MPC "FFFFh";
BA_ "FlexKomIsMotorola" SG_ 2499740031 LaneCrvtrChgLt_Cval_MPC 1;
BA_ "FlexKomComment" SG_ 2499740031 LaneCrvtrChgLt_Cval_MPC "MPC_C06_Pkt";
BA_ "FlexKomSigName" SG_ 2499740031 LaneCrvtrChgLt_Cval_MPC "MPC_C06_Pkt";
BA_ "FlexKomSigLaenge" SG_ 2499740031 LaneCrvtrChgLt_Cval_MPC 64;
BA_ "FlexKomSigStartPos" SG_ 2499740031 LaneCrvtrChgLt_Cval_MPC 7;
BA_ "FlexKomSID" SG_ 2499740031 LaneCrvtrChgLt_Cval_MPC 100679812;
BA_ "GenSigStartValue" SG_ 2499740031 LaneCrvtrChgLt_Cval_MPC 65535;
BA_ "FlexKomSigStartValue" SG_ 2499740031 LaneCrvtrChgLt_Cval_MPC "D9F0FFFFFFFFFFFFh";
BA_ "GenSigCycleTime" SG_ 2499740031 LaneCrvtrChgLt_Cval_MPC 100;
BA_ "GenSigSNA" SG_ 2499740031 LaneCrvtrChgRt_Cval_MPC "FFFFh";
BA_ "FlexKomIsMotorola" SG_ 2499740031 LaneCrvtrChgRt_Cval_MPC 1;
BA_ "FlexKomComment" SG_ 2499740031 LaneCrvtrChgRt_Cval_MPC "MPC_C06_Pkt";
BA_ "FlexKomSigName" SG_ 2499740031 LaneCrvtrChgRt_Cval_MPC "MPC_C06_Pkt";
BA_ "FlexKomSigLaenge" SG_ 2499740031 LaneCrvtrChgRt_Cval_MPC 64;
BA_ "FlexKomSigStartPos" SG_ 2499740031 LaneCrvtrChgRt_Cval_MPC 7;
BA_ "FlexKomSID" SG_ 2499740031 LaneCrvtrChgRt_Cval_MPC 100679812;
BA_ "GenSigStartValue" SG_ 2499740031 LaneCrvtrChgRt_Cval_MPC 65535;
BA_ "FlexKomSigStartValue" SG_ 2499740031 LaneCrvtrChgRt_Cval_MPC "D9F0FFFFFFFFFFFFh";
BA_ "GenSigCycleTime" SG_ 2499740031 LaneCrvtrChgRt_Cval_MPC 100;
BA_ "GenSigSNA" SG_ 2499740648 CRC_SG_VRDU_C01_Pkt "0h";
BA_ "FlexKomIsMotorola" SG_ 2499740648 CRC_SG_VRDU_C01_Pkt 1;
BA_ "FlexKomComment" SG_ 2499740648 CRC_SG_VRDU_C01_Pkt "VRDU C01 Pkt";
BA_ "FlexKomSigName" SG_ 2499740648 CRC_SG_VRDU_C01_Pkt "VRDU_C01_Pkt";
BA_ "FlexKomSigLaenge" SG_ 2499740648 CRC_SG_VRDU_C01_Pkt 64;
BA_ "FlexKomSigStartPos" SG_ 2499740648 CRC_SG_VRDU_C01_Pkt 7;
BA_ "FlexKomSID" SG_ 2499740648 CRC_SG_VRDU_C01_Pkt 100677187;
BA_ "GenSigTimeout_MPC2" SG_ 2499740648 CRC_SG_VRDU_C01_Pkt 1050;
BA_ "FlexKomSigStartValue" SG_ 2499740648 CRC_SG_VRDU_C01_Pkt "00F0F3FFFFFFFFFFh";
BA_ "GenSigCycleTime" SG_ 2499740648 CRC_SG_VRDU_C01_Pkt 100;
BA_ "GenSigSNA" SG_ 2499740648 SQC_SG_VRDU_C01_Pkt "0h";
BA_ "FlexKomIsMotorola" SG_ 2499740648 SQC_SG_VRDU_C01_Pkt 1;
BA_ "FlexKomComment" SG_ 2499740648 SQC_SG_VRDU_C01_Pkt "VRDU C01 Pkt";
BA_ "FlexKomSigName" SG_ 2499740648 SQC_SG_VRDU_C01_Pkt "VRDU_C01_Pkt";
BA_ "FlexKomSigLaenge" SG_ 2499740648 SQC_SG_VRDU_C01_Pkt 64;
BA_ "FlexKomSigStartPos" SG_ 2499740648 SQC_SG_VRDU_C01_Pkt 7;
BA_ "FlexKomSID" SG_ 2499740648 SQC_SG_VRDU_C01_Pkt 100677187;
BA_ "GenSigTimeout_MPC2" SG_ 2499740648 SQC_SG_VRDU_C01_Pkt 1050;
BA_ "FlexKomSigStartValue" SG_ 2499740648 SQC_SG_VRDU_C01_Pkt "00F0F3FFFFFFFFFFh";
BA_ "GenSigCycleTime" SG_ 2499740648 SQC_SG_VRDU_C01_Pkt 100;
BA_ "GenSigSNA" SG_ 2499740648 DrvDirec_Stat_VRDU "3h";
BA_ "FlexKomIsMotorola" SG_ 2499740648 DrvDirec_Stat_VRDU 1;
BA_ "FlexKomComment" SG_ 2499740648 DrvDirec_Stat_VRDU "VRDU C01 Pkt";
BA_ "FlexKomSigName" SG_ 2499740648 DrvDirec_Stat_VRDU "VRDU_C01_Pkt";
BA_ "FlexKomSigLaenge" SG_ 2499740648 DrvDirec_Stat_VRDU 64;
BA_ "FlexKomSigStartPos" SG_ 2499740648 DrvDirec_Stat_VRDU 7;
BA_ "FlexKomSID" SG_ 2499740648 DrvDirec_Stat_VRDU 100677187;
BA_ "GenSigTimeout_MPC2" SG_ 2499740648 DrvDirec_Stat_VRDU 1050;
BA_ "GenSigStartValue" SG_ 2499740648 DrvDirec_Stat_VRDU 3;
BA_ "FlexKomSigStartValue" SG_ 2499740648 DrvDirec_Stat_VRDU "00F0F3FFFFFFFFFFh";
BA_ "GenSigCycleTime" SG_ 2499740648 DrvDirec_Stat_VRDU 100;
BA_ "GenSigSNA" SG_ 2499740648 ABA_DistWarn_Stat "3h";
BA_ "FlexKomIsMotorola" SG_ 2499740648 ABA_DistWarn_Stat 1;
BA_ "FlexKomComment" SG_ 2499740648 ABA_DistWarn_Stat "VRDU C01 Pkt";
BA_ "FlexKomSigName" SG_ 2499740648 ABA_DistWarn_Stat "VRDU_C01_Pkt";
BA_ "FlexKomSigLaenge" SG_ 2499740648 ABA_DistWarn_Stat 64;
BA_ "FlexKomSigStartPos" SG_ 2499740648 ABA_DistWarn_Stat 7;
BA_ "FlexKomSID" SG_ 2499740648 ABA_DistWarn_Stat 100677187;
BA_ "GenSigTimeout_MPC2" SG_ 2499740648 ABA_DistWarn_Stat 1050;
BA_ "FlexKomSigStartValue" SG_ 2499740648 ABA_DistWarn_Stat "00F0F3FFFFFFFFFFh";
BA_ "GenSigCycleTime" SG_ 2499740648 ABA_DistWarn_Stat 100;
BA_ "GenSigSNA" SG_ 2499740648 ALA_Stat "3h";
BA_ "FlexKomIsMotorola" SG_ 2499740648 ALA_Stat 1;
BA_ "FlexKomComment" SG_ 2499740648 ALA_Stat "VRDU C01 Pkt";
BA_ "FlexKomSigName" SG_ 2499740648 ALA_Stat "VRDU_C01_Pkt";
BA_ "FlexKomSigLaenge" SG_ 2499740648 ALA_Stat 64;
BA_ "FlexKomSigStartPos" SG_ 2499740648 ALA_Stat 7;
BA_ "FlexKomSID" SG_ 2499740648 ALA_Stat 100677187;
BA_ "GenSigTimeout_MPC2" SG_ 2499740648 ALA_Stat 1050;
BA_ "GenSigStartValue" SG_ 2499740648 ALA_Stat 3;
BA_ "FlexKomSigStartValue" SG_ 2499740648 ALA_Stat "00F0F3FFFFFFFFFFh";
BA_ "GenSigCycleTime" SG_ 2499740648 ALA_Stat 100;
BA_ "GenSigSNA" SG_ 2499740904 WhlBaseTrtr_Cval "FFh";
BA_ "FlexKomIsMotorola" SG_ 2499740904 WhlBaseTrtr_Cval 1;
BA_ "FlexKomComment" SG_ 2499740904 WhlBaseTrtr_Cval "VRDU C02 Pkt";
BA_ "FlexKomSigName" SG_ 2499740904 WhlBaseTrtr_Cval "VRDU_C02_Pkt";
BA_ "FlexKomSigLaenge" SG_ 2499740904 WhlBaseTrtr_Cval 64;
BA_ "FlexKomSigStartPos" SG_ 2499740904 WhlBaseTrtr_Cval 7;
BA_ "FlexKomSID" SG_ 2499740904 WhlBaseTrtr_Cval 100677418;
BA_ "GenSigTimeout_MPC2" SG_ 2499740904 WhlBaseTrtr_Cval 1050;
BA_ "GenSigStartValue" SG_ 2499740904 WhlBaseTrtr_Cval 255;
BA_ "FlexKomSigStartValue" SG_ 2499740904 WhlBaseTrtr_Cval "FFFFFFFFFFFFFFFFh";
BA_ "GenSigCycleTime" SG_ 2499740904 WhlBaseTrtr_Cval 100;
BA_ "GenSigSNA" SG_ 2499742976 RetSwPos_Rq_STSR "FFh";
BA_ "FlexKomIsMotorola" SG_ 2499742976 RetSwPos_Rq_STSR 1;
BA_ "FlexKomComment" SG_ 2499742976 RetSwPos_Rq_STSR "Retarder Switch Position";
BA_ "FlexKomSigName" SG_ 2499742976 RetSwPos_Rq_STSR "RetSwPos_STSR";
BA_ "FlexKomSigLaenge" SG_ 2499742976 RetSwPos_Rq_STSR 8;
BA_ "FlexKomSigStartPos" SG_ 2499742976 RetSwPos_Rq_STSR 39;
BA_ "FlexKomSID" SG_ 2499742976 RetSwPos_Rq_STSR 100664183;
BA_ "GenSigTimeout_MPC2" SG_ 2499742976 RetSwPos_Rq_STSR 1050;
BA_ "GenSigStartValue" SG_ 2499742976 RetSwPos_Rq_STSR 255;
BA_ "FlexKomSigStartValue" SG_ 2499742976 RetSwPos_Rq_STSR "FFh";
BA_ "GenSigCycleTime" SG_ 2499742976 RetSwPos_Rq_STSR 100;
BA_ "GenSigSendType" SG_ 2499742976 RetSwPos_Rq_STSR 5;
BA_ "FlexKomIsMotorola" SG_ 2565832698 APPL_SG_MPC 1;
BA_ "FlexKomComment" SG_ 2565832698 APPL_SG_MPC "External application to ECU";
BA_ "FlexKomSigName" SG_ 2565832698 APPL_SG_MPC "APPL_SG_MPC";
BA_ "FlexKomSigLaenge" SG_ 2565832698 APPL_SG_MPC 64;
BA_ "FlexKomSigStartPos" SG_ 2565832698 APPL_SG_MPC 7;
BA_ "FlexKomSID" SG_ 2565832698 APPL_SG_MPC 100677023;
BA_ "FlexKomSigStartValue" SG_ 2565832698 APPL_SG_MPC "0000000000000000h";
BA_ "GenSigSendType" SG_ 2565832698 APPL_SG_MPC 1;
BA_ "FlexKomIsMotorola" SG_ 2565864063 SG_APPL_MPC 1;
BA_ "FlexKomComment" SG_ 2565864063 SG_APPL_MPC "ECU to external application";
BA_ "FlexKomSigName" SG_ 2565864063 SG_APPL_MPC "SG_APPL_MPC";
BA_ "FlexKomSigLaenge" SG_ 2565864063 SG_APPL_MPC 64;
BA_ "FlexKomSigStartPos" SG_ 2565864063 SG_APPL_MPC 7;
BA_ "FlexKomSID" SG_ 2565864063 SG_APPL_MPC 100677022;
BA_ "FlexKomSigStartValue" SG_ 2565864063 SG_APPL_MPC "0000000000000000h";
BA_ "GenSigSendType" SG_ 2565864063 SG_APPL_MPC 1;
BA_ "GenSigSNA" SG_ 2566809216 BatMainSw_Stat "3h";
BA_ "FlexKomIsMotorola" SG_ 2566809216 BatMainSw_Stat 1;
BA_ "FlexKomComment" SG_ 2566809216 BatMainSw_Stat "Battery Main Switch Hold";
BA_ "FlexKomSigName" SG_ 2566809216 BatMainSw_Stat "BatMainSw_Pkt";
BA_ "FlexKomSigLaenge" SG_ 2566809216 BatMainSw_Stat 64;
BA_ "FlexKomSigStartPos" SG_ 2566809216 BatMainSw_Stat 7;
BA_ "FlexKomSID" SG_ 2566809216 BatMainSw_Stat 100663423;
BA_ "GenSigTimeout_MPC2" SG_ 2566809216 BatMainSw_Stat 5500;
BA_ "GenSigStartValue" SG_ 2566809216 BatMainSw_Stat 3;
BA_ "FlexKomSigStartValue" SG_ 2566809216 BatMainSw_Stat "FFFFFFFFFFFFFFFFh";
BA_ "GenSigCycleTime" SG_ 2566809216 BatMainSw_Stat 1000;
BA_ "GenSigSendType" SG_ 2566809216 BatMainSw_Stat 5;
BA_ "GenSigSNA" SG_ 2566841879 DateTmSecond_Cval_ICUC "FFh";
BA_ "FlexKomIsMotorola" SG_ 2566841879 DateTmSecond_Cval_ICUC 1;
BA_ "FlexKomComment" SG_ 2566841879 DateTmSecond_Cval_ICUC "Time (Seconds, Minutes, Hours, Day, Month, Year) C";
BA_ "FlexKomSigName" SG_ 2566841879 DateTmSecond_Cval_ICUC "Time_Cval_ICUC";
BA_ "FlexKomSigLaenge" SG_ 2566841879 DateTmSecond_Cval_ICUC 48;
BA_ "FlexKomSigStartPos" SG_ 2566841879 DateTmSecond_Cval_ICUC 7;
BA_ "FlexKomSID" SG_ 2566841879 DateTmSecond_Cval_ICUC 100664297;
BA_ "GenSigTimeout_MPC2" SG_ 2566841879 DateTmSecond_Cval_ICUC 10500;
BA_ "GenSigStartValue" SG_ 2566841879 DateTmSecond_Cval_ICUC 255;
BA_ "FlexKomSigStartValue" SG_ 2566841879 DateTmSecond_Cval_ICUC "FFFFFFFFFFFFh";
BA_ "GenSigCycleTime" SG_ 2566841879 DateTmSecond_Cval_ICUC 1000;
BA_ "GenSigSNA" SG_ 2566841879 DateTmMinute_Cval_ICUC "FFh";
BA_ "FlexKomIsMotorola" SG_ 2566841879 DateTmMinute_Cval_ICUC 1;
BA_ "FlexKomComment" SG_ 2566841879 DateTmMinute_Cval_ICUC "Time (Seconds, Minutes, Hours, Day, Month, Year) C";
BA_ "FlexKomSigName" SG_ 2566841879 DateTmMinute_Cval_ICUC "Time_Cval_ICUC";
BA_ "FlexKomSigLaenge" SG_ 2566841879 DateTmMinute_Cval_ICUC 48;
BA_ "FlexKomSigStartPos" SG_ 2566841879 DateTmMinute_Cval_ICUC 7;
BA_ "FlexKomSID" SG_ 2566841879 DateTmMinute_Cval_ICUC 100664297;
BA_ "GenSigTimeout_MPC2" SG_ 2566841879 DateTmMinute_Cval_ICUC 10500;
BA_ "GenSigStartValue" SG_ 2566841879 DateTmMinute_Cval_ICUC 255;
BA_ "FlexKomSigStartValue" SG_ 2566841879 DateTmMinute_Cval_ICUC "FFFFFFFFFFFFh";
BA_ "GenSigCycleTime" SG_ 2566841879 DateTmMinute_Cval_ICUC 1000;
BA_ "GenSigSNA" SG_ 2566841879 DateTmHour_Cval_ICUC "FFh";
BA_ "FlexKomIsMotorola" SG_ 2566841879 DateTmHour_Cval_ICUC 1;
BA_ "FlexKomComment" SG_ 2566841879 DateTmHour_Cval_ICUC "Time (Seconds, Minutes, Hours, Day, Month, Year) C";
BA_ "FlexKomSigName" SG_ 2566841879 DateTmHour_Cval_ICUC "Time_Cval_ICUC";
BA_ "FlexKomSigLaenge" SG_ 2566841879 DateTmHour_Cval_ICUC 48;
BA_ "FlexKomSigStartPos" SG_ 2566841879 DateTmHour_Cval_ICUC 7;
BA_ "FlexKomSID" SG_ 2566841879 DateTmHour_Cval_ICUC 100664297;
BA_ "GenSigTimeout_MPC2" SG_ 2566841879 DateTmHour_Cval_ICUC 10500;
BA_ "GenSigStartValue" SG_ 2566841879 DateTmHour_Cval_ICUC 255;
BA_ "FlexKomSigStartValue" SG_ 2566841879 DateTmHour_Cval_ICUC "FFFFFFFFFFFFh";
BA_ "GenSigCycleTime" SG_ 2566841879 DateTmHour_Cval_ICUC 1000;
BA_ "GenSigSNA" SG_ 2566841879 DateTmMonth_Cval_ICUC "FFh";
BA_ "FlexKomIsMotorola" SG_ 2566841879 DateTmMonth_Cval_ICUC 1;
BA_ "FlexKomComment" SG_ 2566841879 DateTmMonth_Cval_ICUC "Time (Seconds, Minutes, Hours, Day, Month, Year) C";
BA_ "FlexKomSigName" SG_ 2566841879 DateTmMonth_Cval_ICUC "Time_Cval_ICUC";
BA_ "FlexKomSigLaenge" SG_ 2566841879 DateTmMonth_Cval_ICUC 48;
BA_ "FlexKomSigStartPos" SG_ 2566841879 DateTmMonth_Cval_ICUC 7;
BA_ "FlexKomSID" SG_ 2566841879 DateTmMonth_Cval_ICUC 100664297;
BA_ "GenSigTimeout_MPC2" SG_ 2566841879 DateTmMonth_Cval_ICUC 10500;
BA_ "GenSigStartValue" SG_ 2566841879 DateTmMonth_Cval_ICUC 255;
BA_ "FlexKomSigStartValue" SG_ 2566841879 DateTmMonth_Cval_ICUC "FFFFFFFFFFFFh";
BA_ "GenSigCycleTime" SG_ 2566841879 DateTmMonth_Cval_ICUC 1000;
BA_ "GenSigSNA" SG_ 2566841879 DateTmDay_Cval_ICUC "FFh";
BA_ "FlexKomIsMotorola" SG_ 2566841879 DateTmDay_Cval_ICUC 1;
BA_ "FlexKomComment" SG_ 2566841879 DateTmDay_Cval_ICUC "Time (Seconds, Minutes, Hours, Day, Month, Year) C";
BA_ "FlexKomSigName" SG_ 2566841879 DateTmDay_Cval_ICUC "Time_Cval_ICUC";
BA_ "FlexKomSigLaenge" SG_ 2566841879 DateTmDay_Cval_ICUC 48;
BA_ "FlexKomSigStartPos" SG_ 2566841879 DateTmDay_Cval_ICUC 7;
BA_ "FlexKomSID" SG_ 2566841879 DateTmDay_Cval_ICUC 100664297;
BA_ "GenSigTimeout_MPC2" SG_ 2566841879 DateTmDay_Cval_ICUC 10500;
BA_ "GenSigStartValue" SG_ 2566841879 DateTmDay_Cval_ICUC 255;
BA_ "FlexKomSigStartValue" SG_ 2566841879 DateTmDay_Cval_ICUC "FFFFFFFFFFFFh";
BA_ "GenSigCycleTime" SG_ 2566841879 DateTmDay_Cval_ICUC 1000;
BA_ "GenSigSNA" SG_ 2566841879 DateTmYear_Cval_ICUC "FFh";
BA_ "FlexKomIsMotorola" SG_ 2566841879 DateTmYear_Cval_ICUC 1;
BA_ "FlexKomComment" SG_ 2566841879 DateTmYear_Cval_ICUC "Time (Seconds, Minutes, Hours, Day, Month, Year) C";
BA_ "FlexKomSigName" SG_ 2566841879 DateTmYear_Cval_ICUC "Time_Cval_ICUC";
BA_ "FlexKomSigLaenge" SG_ 2566841879 DateTmYear_Cval_ICUC 48;
BA_ "FlexKomSigStartPos" SG_ 2566841879 DateTmYear_Cval_ICUC 7;
BA_ "FlexKomSID" SG_ 2566841879 DateTmYear_Cval_ICUC 100664297;
BA_ "GenSigTimeout_MPC2" SG_ 2566841879 DateTmYear_Cval_ICUC 10500;
BA_ "GenSigStartValue" SG_ 2566841879 DateTmYear_Cval_ICUC 255;
BA_ "FlexKomSigStartValue" SG_ 2566841879 DateTmYear_Cval_ICUC "FFFFFFFFFFFFh";
BA_ "GenSigCycleTime" SG_ 2566841879 DateTmYear_Cval_ICUC 1000;
BA_ "GenSigSNA" SG_ 2566841879 LocalMinuteOffset_Cval_ICUC "FFh";
BA_ "FlexKomIsMotorola" SG_ 2566841879 LocalMinuteOffset_Cval_ICUC 1;
BA_ "FlexKomComment" SG_ 2566841879 LocalMinuteOffset_Cval_ICUC "Local Time Offset Current value from ICUC";
BA_ "FlexKomSigName" SG_ 2566841879 LocalMinuteOffset_Cval_ICUC "LocalTimeOffset_ICUC";
BA_ "FlexKomSigLaenge" SG_ 2566841879 LocalMinuteOffset_Cval_ICUC 16;
BA_ "FlexKomSigStartPos" SG_ 2566841879 LocalMinuteOffset_Cval_ICUC 55;
BA_ "FlexKomSID" SG_ 2566841879 LocalMinuteOffset_Cval_ICUC 100664298;
BA_ "GenSigTimeout_MPC2" SG_ 2566841879 LocalMinuteOffset_Cval_ICUC 10500;
BA_ "GenSigStartValue" SG_ 2566841879 LocalMinuteOffset_Cval_ICUC 255;
BA_ "FlexKomSigStartValue" SG_ 2566841879 LocalMinuteOffset_Cval_ICUC "FFFFh";
BA_ "GenSigCycleTime" SG_ 2566841879 LocalMinuteOffset_Cval_ICUC 1000;
BA_ "GenSigSNA" SG_ 2566841879 LocalHourOffset_Cval_ICUC "FFh";
BA_ "FlexKomIsMotorola" SG_ 2566841879 LocalHourOffset_Cval_ICUC 1;
BA_ "FlexKomComment" SG_ 2566841879 LocalHourOffset_Cval_ICUC "Local Time Offset Current value from ICUC";
BA_ "FlexKomSigName" SG_ 2566841879 LocalHourOffset_Cval_ICUC "LocalTimeOffset_ICUC";
BA_ "FlexKomSigLaenge" SG_ 2566841879 LocalHourOffset_Cval_ICUC 16;
BA_ "FlexKomSigStartPos" SG_ 2566841879 LocalHourOffset_Cval_ICUC 55;
BA_ "FlexKomSID" SG_ 2566841879 LocalHourOffset_Cval_ICUC 100664298;
BA_ "GenSigTimeout_MPC2" SG_ 2566841879 LocalHourOffset_Cval_ICUC 10500;
BA_ "GenSigStartValue" SG_ 2566841879 LocalHourOffset_Cval_ICUC 255;
BA_ "FlexKomSigStartValue" SG_ 2566841879 LocalHourOffset_Cval_ICUC "FFFFh";
BA_ "GenSigCycleTime" SG_ 2566841879 LocalHourOffset_Cval_ICUC 1000;
BA_ "GenSigSNA" SG_ 2566845201 Latitude_Cval_IPPC "FFFFFFFFh";
BA_ "FlexKomIsMotorola" SG_ 2566845201 Latitude_Cval_IPPC 1;
BA_ "FlexKomComment" SG_ 2566845201 Latitude_Cval_IPPC "Vehicle Position VP Container";
BA_ "FlexKomSigName" SG_ 2566845201 Latitude_Cval_IPPC "VP_IPPC_Pkt";
BA_ "FlexKomSigLaenge" SG_ 2566845201 Latitude_Cval_IPPC 64;
BA_ "FlexKomSigStartPos" SG_ 2566845201 Latitude_Cval_IPPC 7;
BA_ "FlexKomSID" SG_ 2566845201 Latitude_Cval_IPPC 100679942;
BA_ "GenSigTimeout_MPC2" SG_ 2566845201 Latitude_Cval_IPPC 5500;
BA_ "GenSigStartValue" SG_ 2566845201 Latitude_Cval_IPPC 268435455;
BA_ "FlexKomSigStartValue" SG_ 2566845201 Latitude_Cval_IPPC "FFFFFFFFFFFFFFFFh";
BA_ "GenSigCycleTime" SG_ 2566845201 Latitude_Cval_IPPC 1000;
BA_ "GenSigSNA" SG_ 2566845201 Longitude_Cval_IPPC "FFFFFFFFh";
BA_ "FlexKomIsMotorola" SG_ 2566845201 Longitude_Cval_IPPC 1;
BA_ "FlexKomComment" SG_ 2566845201 Longitude_Cval_IPPC "Vehicle Position VP Container";
BA_ "FlexKomSigName" SG_ 2566845201 Longitude_Cval_IPPC "VP_IPPC_Pkt";
BA_ "FlexKomSigLaenge" SG_ 2566845201 Longitude_Cval_IPPC 64;
BA_ "FlexKomSigStartPos" SG_ 2566845201 Longitude_Cval_IPPC 7;
BA_ "FlexKomSID" SG_ 2566845201 Longitude_Cval_IPPC 100679942;
BA_ "GenSigTimeout_MPC2" SG_ 2566845201 Longitude_Cval_IPPC 5500;
BA_ "GenSigStartValue" SG_ 2566845201 Longitude_Cval_IPPC 4294967295;
BA_ "FlexKomSigStartValue" SG_ 2566845201 Longitude_Cval_IPPC "FFFFFFFFFFFFFFFFh";
BA_ "GenSigCycleTime" SG_ 2566845201 Longitude_Cval_IPPC 1000;
BA_ "GenSigSNA" SG_ 2566845729 AirTempOutsd_Cval_SCA "FFFFh";
BA_ "FlexKomIsMotorola" SG_ 2566845729 AirTempOutsd_Cval_SCA 1;
BA_ "FlexKomComment" SG_ 2566845729 AirTempOutsd_Cval_SCA "Air Temperature SCA";
BA_ "FlexKomSigName" SG_ 2566845729 AirTempOutsd_Cval_SCA "AirTemp_SCA";
BA_ "FlexKomSigLaenge" SG_ 2566845729 AirTempOutsd_Cval_SCA 32;
BA_ "FlexKomSigStartPos" SG_ 2566845729 AirTempOutsd_Cval_SCA 15;
BA_ "FlexKomSID" SG_ 2566845729 AirTempOutsd_Cval_SCA 100664329;
BA_ "GenSigTimeout_MPC2" SG_ 2566845729 AirTempOutsd_Cval_SCA 10500;
BA_ "GenSigStartValue" SG_ 2566845729 AirTempOutsd_Cval_SCA 65535;
BA_ "FlexKomSigStartValue" SG_ 2566845729 AirTempOutsd_Cval_SCA "FFFFFFFFh";
BA_ "GenSigCycleTime" SG_ 2566845729 AirTempOutsd_Cval_SCA 1000;
BA_ "GenSigSNA" SG_ 2566848549 Offboard_Tester_Stat "3h";
BA_ "FlexKomIsMotorola" SG_ 2566848549 Offboard_Tester_Stat 1;
BA_ "FlexKomComment" SG_ 2566848549 Offboard_Tester_Stat "TestTools Current State";
BA_ "FlexKomSigName" SG_ 2566848549 Offboard_Tester_Stat "TestTools_Stat";
BA_ "FlexKomSigLaenge" SG_ 2566848549 Offboard_Tester_Stat 4;
BA_ "FlexKomSigStartPos" SG_ 2566848549 Offboard_Tester_Stat 3;
BA_ "FlexKomSID" SG_ 2566848549 Offboard_Tester_Stat 100663671;
BA_ "GenSigTimeout_MPC2" SG_ 2566848549 Offboard_Tester_Stat 10500;
BA_ "GenSigStartValue" SG_ 2566848549 Offboard_Tester_Stat 3;
BA_ "FlexKomSigStartValue" SG_ 2566848549 Offboard_Tester_Stat "0Fh";
BA_ "GenSigCycleTime" SG_ 2566848549 Offboard_Tester_Stat 1000;
BA_ "GenSigSendType" SG_ 2566848549 Offboard_Tester_Stat 5;
BA_ "GenSigSNA" SG_ 2566848549 SelfHealing2_Stat "FFh";
BA_ "FlexKomIsMotorola" SG_ 2566848549 SelfHealing2_Stat 1;
BA_ "FlexKomComment" SG_ 2566848549 SelfHealing2_Stat "Self Healing";
BA_ "FlexKomSigName" SG_ 2566848549 SelfHealing2_Stat "SelfHealing";
BA_ "FlexKomSigLaenge" SG_ 2566848549 SelfHealing2_Stat 16;
BA_ "FlexKomSigStartPos" SG_ 2566848549 SelfHealing2_Stat 23;
BA_ "FlexKomSID" SG_ 2566848549 SelfHealing2_Stat 100663901;
BA_ "GenSigTimeout_MPC2" SG_ 2566848549 SelfHealing2_Stat 10500;
BA_ "GenSigStartValue" SG_ 2566848549 SelfHealing2_Stat 255;
BA_ "FlexKomSigStartValue" SG_ 2566848549 SelfHealing2_Stat "FFFFh";
BA_ "GenSigCycleTime" SG_ 2566848549 SelfHealing2_Stat 1000;
BA_ "GenSigSendType" SG_ 2566848549 SelfHealing2_Stat 5;
BA_ "GenSigSNA" SG_ 2566848549 SelfHealing3_Stat "FFh";
BA_ "FlexKomIsMotorola" SG_ 2566848549 SelfHealing3_Stat 1;
BA_ "FlexKomComment" SG_ 2566848549 SelfHealing3_Stat "Self Healing";
BA_ "FlexKomSigName" SG_ 2566848549 SelfHealing3_Stat "SelfHealing";
BA_ "FlexKomSigLaenge" SG_ 2566848549 SelfHealing3_Stat 16;
BA_ "FlexKomSigStartPos" SG_ 2566848549 SelfHealing3_Stat 23;
BA_ "FlexKomSID" SG_ 2566848549 SelfHealing3_Stat 100663901;
BA_ "GenSigTimeout_MPC2" SG_ 2566848549 SelfHealing3_Stat 10500;
BA_ "GenSigStartValue" SG_ 2566848549 SelfHealing3_Stat 255;
BA_ "FlexKomSigStartValue" SG_ 2566848549 SelfHealing3_Stat "FFFFh";
BA_ "GenSigCycleTime" SG_ 2566848549 SelfHealing3_Stat 1000;
BA_ "GenSigSendType" SG_ 2566848549 SelfHealing3_Stat 5;
BA_ "GenSigSNA" SG_ 2566848549 TotalVehDist_Cval_DIAG "FFFFFFFFh";
BA_ "FlexKomIsMotorola" SG_ 2566848549 TotalVehDist_Cval_DIAG 1;
BA_ "FlexKomComment" SG_ 2566848549 TotalVehDist_Cval_DIAG "Total Vehicle Distance Current value Diagnostic";
BA_ "FlexKomSigName" SG_ 2566848549 TotalVehDist_Cval_DIAG "TotalVehDist_DIAG";
BA_ "FlexKomSigLaenge" SG_ 2566848549 TotalVehDist_Cval_DIAG 32;
BA_ "FlexKomSigStartPos" SG_ 2566848549 TotalVehDist_Cval_DIAG 39;
BA_ "FlexKomSID" SG_ 2566848549 TotalVehDist_Cval_DIAG 100663878;
BA_ "GenSigTimeout_MPC2" SG_ 2566848549 TotalVehDist_Cval_DIAG 10500;
BA_ "GenSigStartValue" SG_ 2566848549 TotalVehDist_Cval_DIAG 4294967295;
BA_ "FlexKomSigStartValue" SG_ 2566848549 TotalVehDist_Cval_DIAG "FFFFFFFFh";
BA_ "GenSigCycleTime" SG_ 2566848549 TotalVehDist_Cval_DIAG 1000;
BA_ "GenSigSendType" SG_ 2566848549 TotalVehDist_Cval_DIAG 5;
BA_ "GenSigSNA" SG_ 2566848791 TSR_MdSw_Rq "3h";
BA_ "FlexKomIsMotorola" SG_ 2566848791 TSR_MdSw_Rq 1;
BA_ "FlexKomComment" SG_ 2566848791 TSR_MdSw_Rq "TSR Function Current state MPC";
BA_ "FlexKomSigName" SG_ 2566848791 TSR_MdSw_Rq "TSR_Func_Stat_MPC";
BA_ "FlexKomSigLaenge" SG_ 2566848791 TSR_MdSw_Rq 2;
BA_ "FlexKomSigStartPos" SG_ 2566848791 TSR_MdSw_Rq 1;
BA_ "FlexKomSID" SG_ 2566848791 TSR_MdSw_Rq 100680583;
BA_ "GenSigTimeout_MPC2" SG_ 2566848791 TSR_MdSw_Rq 10500;
BA_ "GenSigStartValue" SG_ 2566848791 TSR_MdSw_Rq 3;
BA_ "FlexKomSigStartValue" SG_ 2566848791 TSR_MdSw_Rq "03h";
BA_ "GenSigCycleTime" SG_ 2566848791 TSR_MdSw_Rq 1000;
BA_ "GenSigSendType" SG_ 2566848791 TSR_MdSw_Rq 5;
BA_ "GenSigSNA" SG_ 2566848895 TrafSign1_MPC "FFh";
BA_ "FlexKomIsMotorola" SG_ 2566848895 TrafSign1_MPC 1;
BA_ "FlexKomComment" SG_ 2566848895 TrafSign1_MPC "MPC_C29_Pkt";
BA_ "FlexKomSigName" SG_ 2566848895 TrafSign1_MPC "MPC_C29_Pkt";
BA_ "FlexKomSigLaenge" SG_ 2566848895 TrafSign1_MPC 64;
BA_ "FlexKomSigStartPos" SG_ 2566848895 TrafSign1_MPC 7;
BA_ "FlexKomSID" SG_ 2566848895 TrafSign1_MPC 100679851;
BA_ "GenSigStartValue" SG_ 2566848895 TrafSign1_MPC 255;
BA_ "FlexKomSigStartValue" SG_ 2566848895 TrafSign1_MPC "FFFFFFFFFFFFFFFFh";
BA_ "GenSigCycleTime" SG_ 2566848895 TrafSign1_MPC 1000;
BA_ "GenSigSendType" SG_ 2566848895 TrafSign1_MPC 5;
BA_ "GenSigSNA" SG_ 2566848895 TrafSign2_MPC "FFh";
BA_ "FlexKomIsMotorola" SG_ 2566848895 TrafSign2_MPC 1;
BA_ "FlexKomComment" SG_ 2566848895 TrafSign2_MPC "MPC_C29_Pkt";
BA_ "FlexKomSigName" SG_ 2566848895 TrafSign2_MPC "MPC_C29_Pkt";
BA_ "FlexKomSigLaenge" SG_ 2566848895 TrafSign2_MPC 64;
BA_ "FlexKomSigStartPos" SG_ 2566848895 TrafSign2_MPC 7;
BA_ "FlexKomSID" SG_ 2566848895 TrafSign2_MPC 100679851;
BA_ "GenSigStartValue" SG_ 2566848895 TrafSign2_MPC 255;
BA_ "FlexKomSigStartValue" SG_ 2566848895 TrafSign2_MPC "FFFFFFFFFFFFFFFFh";
BA_ "GenSigCycleTime" SG_ 2566848895 TrafSign2_MPC 1000;
BA_ "GenSigSendType" SG_ 2566848895 TrafSign2_MPC 5;
BA_ "GenSigSNA" SG_ 2566848895 SuppSign1_MPC "FFh";
BA_ "FlexKomIsMotorola" SG_ 2566848895 SuppSign1_MPC 1;
BA_ "FlexKomComment" SG_ 2566848895 SuppSign1_MPC "MPC_C29_Pkt";
BA_ "FlexKomSigName" SG_ 2566848895 SuppSign1_MPC "MPC_C29_Pkt";
BA_ "FlexKomSigLaenge" SG_ 2566848895 SuppSign1_MPC 64;
BA_ "FlexKomSigStartPos" SG_ 2566848895 SuppSign1_MPC 7;
BA_ "FlexKomSID" SG_ 2566848895 SuppSign1_MPC 100679851;
BA_ "GenSigStartValue" SG_ 2566848895 SuppSign1_MPC 255;
BA_ "FlexKomSigStartValue" SG_ 2566848895 SuppSign1_MPC "FFFFFFFFFFFFFFFFh";
BA_ "GenSigCycleTime" SG_ 2566848895 SuppSign1_MPC 1000;
BA_ "GenSigSendType" SG_ 2566848895 SuppSign1_MPC 5;
BA_ "GenSigSNA" SG_ 2566848895 SuppSign2_MPC "FFh";
BA_ "FlexKomIsMotorola" SG_ 2566848895 SuppSign2_MPC 1;
BA_ "FlexKomComment" SG_ 2566848895 SuppSign2_MPC "MPC_C29_Pkt";
BA_ "FlexKomSigName" SG_ 2566848895 SuppSign2_MPC "MPC_C29_Pkt";
BA_ "FlexKomSigLaenge" SG_ 2566848895 SuppSign2_MPC 64;
BA_ "FlexKomSigStartPos" SG_ 2566848895 SuppSign2_MPC 7;
BA_ "FlexKomSID" SG_ 2566848895 SuppSign2_MPC 100679851;
BA_ "GenSigStartValue" SG_ 2566848895 SuppSign2_MPC 255;
BA_ "FlexKomSigStartValue" SG_ 2566848895 SuppSign2_MPC "FFFFFFFFFFFFFFFFh";
BA_ "GenSigCycleTime" SG_ 2566848895 SuppSign2_MPC 1000;
BA_ "GenSigSendType" SG_ 2566848895 SuppSign2_MPC 5;
BA_ "GenSigSNA" SG_ 2566848895 TrafSignSpd_Unit_MPC "3h";
BA_ "FlexKomIsMotorola" SG_ 2566848895 TrafSignSpd_Unit_MPC 1;
BA_ "FlexKomComment" SG_ 2566848895 TrafSignSpd_Unit_MPC "MPC_C29_Pkt";
BA_ "FlexKomSigName" SG_ 2566848895 TrafSignSpd_Unit_MPC "MPC_C29_Pkt";
BA_ "FlexKomSigLaenge" SG_ 2566848895 TrafSignSpd_Unit_MPC 64;
BA_ "FlexKomSigStartPos" SG_ 2566848895 TrafSignSpd_Unit_MPC 7;
BA_ "FlexKomSID" SG_ 2566848895 TrafSignSpd_Unit_MPC 100679851;
BA_ "GenSigStartValue" SG_ 2566848895 TrafSignSpd_Unit_MPC 3;
BA_ "FlexKomSigStartValue" SG_ 2566848895 TrafSignSpd_Unit_MPC "FFFFFFFFFFFFFFFFh";
BA_ "GenSigCycleTime" SG_ 2566848895 TrafSignSpd_Unit_MPC 1000;
BA_ "GenSigSendType" SG_ 2566848895 TrafSignSpd_Unit_MPC 5;
BA_ "GenSigSNA" SG_ 2566848895 TrafSignIcon_Set_MPC "Fh";
BA_ "FlexKomIsMotorola" SG_ 2566848895 TrafSignIcon_Set_MPC 1;
BA_ "FlexKomComment" SG_ 2566848895 TrafSignIcon_Set_MPC "MPC_C29_Pkt";
BA_ "FlexKomSigName" SG_ 2566848895 TrafSignIcon_Set_MPC "MPC_C29_Pkt";
BA_ "FlexKomSigLaenge" SG_ 2566848895 TrafSignIcon_Set_MPC 64;
BA_ "FlexKomSigStartPos" SG_ 2566848895 TrafSignIcon_Set_MPC 7;
BA_ "FlexKomSID" SG_ 2566848895 TrafSignIcon_Set_MPC 100679851;
BA_ "GenSigStartValue" SG_ 2566848895 TrafSignIcon_Set_MPC 15;
BA_ "FlexKomSigStartValue" SG_ 2566848895 TrafSignIcon_Set_MPC "FFFFFFFFFFFFFFFFh";
BA_ "GenSigCycleTime" SG_ 2566848895 TrafSignIcon_Set_MPC 1000;
BA_ "GenSigSendType" SG_ 2566848895 TrafSignIcon_Set_MPC 5;
BA_ "GenSigSNA" SG_ 2566848895 SpdLimWarn_Rq_MPC "3h";
BA_ "FlexKomIsMotorola" SG_ 2566848895 SpdLimWarn_Rq_MPC 1;
BA_ "FlexKomComment" SG_ 2566848895 SpdLimWarn_Rq_MPC "MPC_C29_Pkt";
BA_ "FlexKomSigName" SG_ 2566848895 SpdLimWarn_Rq_MPC "MPC_C29_Pkt";
BA_ "FlexKomSigLaenge" SG_ 2566848895 SpdLimWarn_Rq_MPC 64;
BA_ "FlexKomSigStartPos" SG_ 2566848895 SpdLimWarn_Rq_MPC 7;
BA_ "FlexKomSID" SG_ 2566848895 SpdLimWarn_Rq_MPC 100679851;
BA_ "GenSigStartValue" SG_ 2566848895 SpdLimWarn_Rq_MPC 3;
BA_ "FlexKomSigStartValue" SG_ 2566848895 SpdLimWarn_Rq_MPC "FFFFFFFFFFFFFFFFh";
BA_ "GenSigCycleTime" SG_ 2566848895 SpdLimWarn_Rq_MPC 1000;
BA_ "GenSigSendType" SG_ 2566848895 SpdLimWarn_Rq_MPC 5;
BA_ "GenSigSNA" SG_ 2566848895 NoPassWarn_Rq_MPC "3h";
BA_ "FlexKomIsMotorola" SG_ 2566848895 NoPassWarn_Rq_MPC 1;
BA_ "FlexKomComment" SG_ 2566848895 NoPassWarn_Rq_MPC "MPC_C29_Pkt";
BA_ "FlexKomSigName" SG_ 2566848895 NoPassWarn_Rq_MPC "MPC_C29_Pkt";
BA_ "FlexKomSigLaenge" SG_ 2566848895 NoPassWarn_Rq_MPC 64;
BA_ "FlexKomSigStartPos" SG_ 2566848895 NoPassWarn_Rq_MPC 7;
BA_ "FlexKomSID" SG_ 2566848895 NoPassWarn_Rq_MPC 100679851;
BA_ "GenSigStartValue" SG_ 2566848895 NoPassWarn_Rq_MPC 3;
BA_ "FlexKomSigStartValue" SG_ 2566848895 NoPassWarn_Rq_MPC "FFFFFFFFFFFFFFFFh";
BA_ "GenSigCycleTime" SG_ 2566848895 NoPassWarn_Rq_MPC 1000;
BA_ "GenSigSendType" SG_ 2566848895 NoPassWarn_Rq_MPC 5;
BA_ "GenSigSNA" SG_ 2566848895 TSR_Func_Stat_MPC "Fh";
BA_ "FlexKomIsMotorola" SG_ 2566848895 TSR_Func_Stat_MPC 1;
BA_ "FlexKomComment" SG_ 2566848895 TSR_Func_Stat_MPC "MPC_C29_Pkt";
BA_ "FlexKomSigName" SG_ 2566848895 TSR_Func_Stat_MPC "MPC_C29_Pkt";
BA_ "FlexKomSigLaenge" SG_ 2566848895 TSR_Func_Stat_MPC 64;
BA_ "FlexKomSigStartPos" SG_ 2566848895 TSR_Func_Stat_MPC 7;
BA_ "FlexKomSID" SG_ 2566848895 TSR_Func_Stat_MPC 100679851;
BA_ "GenSigStartValue" SG_ 2566848895 TSR_Func_Stat_MPC 15;
BA_ "FlexKomSigStartValue" SG_ 2566848895 TSR_Func_Stat_MPC "FFFFFFFFFFFFFFFFh";
BA_ "GenSigCycleTime" SG_ 2566848895 TSR_Func_Stat_MPC 1000;
BA_ "GenSigSendType" SG_ 2566848895 TSR_Func_Stat_MPC 5;
BA_ "GenSigSNA" SG_ 2566848895 WrongWayWarn_Rq_MPC "3h";
BA_ "FlexKomIsMotorola" SG_ 2566848895 WrongWayWarn_Rq_MPC 1;
BA_ "FlexKomComment" SG_ 2566848895 WrongWayWarn_Rq_MPC "MPC_C29_Pkt";
BA_ "FlexKomSigName" SG_ 2566848895 WrongWayWarn_Rq_MPC "MPC_C29_Pkt";
BA_ "FlexKomSigLaenge" SG_ 2566848895 WrongWayWarn_Rq_MPC 64;
BA_ "FlexKomSigStartPos" SG_ 2566848895 WrongWayWarn_Rq_MPC 7;
BA_ "FlexKomSID" SG_ 2566848895 WrongWayWarn_Rq_MPC 100679851;
BA_ "GenSigStartValue" SG_ 2566848895 WrongWayWarn_Rq_MPC 3;
BA_ "FlexKomSigStartValue" SG_ 2566848895 WrongWayWarn_Rq_MPC "FFFFFFFFFFFFFFFFh";
BA_ "GenSigCycleTime" SG_ 2566848895 WrongWayWarn_Rq_MPC 1000;
BA_ "GenSigSendType" SG_ 2566848895 WrongWayWarn_Rq_MPC 5;
BA_ "GenSigSNA" SG_ 2566848895 TrafSign3_MPC "FFh";
BA_ "FlexKomIsMotorola" SG_ 2566848895 TrafSign3_MPC 1;
BA_ "FlexKomComment" SG_ 2566848895 TrafSign3_MPC "MPC_C29_Pkt";
BA_ "FlexKomSigName" SG_ 2566848895 TrafSign3_MPC "MPC_C29_Pkt";
BA_ "FlexKomSigLaenge" SG_ 2566848895 TrafSign3_MPC 64;
BA_ "FlexKomSigStartPos" SG_ 2566848895 TrafSign3_MPC 7;
BA_ "FlexKomSID" SG_ 2566848895 TrafSign3_MPC 100679851;
BA_ "GenSigStartValue" SG_ 2566848895 TrafSign3_MPC 255;
BA_ "FlexKomSigStartValue" SG_ 2566848895 TrafSign3_MPC "FFFFFFFFFFFFFFFFh";
BA_ "GenSigCycleTime" SG_ 2566848895 TrafSign3_MPC 1000;
BA_ "GenSigSendType" SG_ 2566848895 TrafSign3_MPC 5;
BA_ "GenSigSNA" SG_ 2566848895 TrafSign4_MPC "FFh";
BA_ "FlexKomIsMotorola" SG_ 2566848895 TrafSign4_MPC 1;
BA_ "FlexKomComment" SG_ 2566848895 TrafSign4_MPC "MPC_C29_Pkt";
BA_ "FlexKomSigName" SG_ 2566848895 TrafSign4_MPC "MPC_C29_Pkt";
BA_ "FlexKomSigLaenge" SG_ 2566848895 TrafSign4_MPC 64;
BA_ "FlexKomSigStartPos" SG_ 2566848895 TrafSign4_MPC 7;
BA_ "FlexKomSID" SG_ 2566848895 TrafSign4_MPC 100679851;
BA_ "GenSigStartValue" SG_ 2566848895 TrafSign4_MPC 255;
BA_ "FlexKomSigStartValue" SG_ 2566848895 TrafSign4_MPC "FFFFFFFFFFFFFFFFh";
BA_ "GenSigCycleTime" SG_ 2566848895 TrafSign4_MPC 1000;
BA_ "GenSigSendType" SG_ 2566848895 TrafSign4_MPC 5;
BA_ "GenSigSNA" SG_ 2566849047 AA_Stat_ICUC "3h";
BA_ "FlexKomIsMotorola" SG_ 2566849047 AA_Stat_ICUC 1;
BA_ "FlexKomComment" SG_ 2566849047 AA_Stat_ICUC "ICUC_C6_Pkt";
BA_ "FlexKomSigName" SG_ 2566849047 AA_Stat_ICUC "ICUC_C6_Pkt";
BA_ "FlexKomSigLaenge" SG_ 2566849047 AA_Stat_ICUC 32;
BA_ "FlexKomSigStartPos" SG_ 2566849047 AA_Stat_ICUC 7;
BA_ "FlexKomSID" SG_ 2566849047 AA_Stat_ICUC 100673969;
BA_ "GenSigTimeout_MPC2" SG_ 2566849047 AA_Stat_ICUC 5500;
BA_ "GenSigStartValue" SG_ 2566849047 AA_Stat_ICUC 3;
BA_ "FlexKomSigStartValue" SG_ 2566849047 AA_Stat_ICUC "0FFF0FFFh";
BA_ "GenSigCycleTime" SG_ 2566849047 AA_Stat_ICUC 1000;
BA_ "GenSigSendType" SG_ 2566849047 AA_Stat_ICUC 5;
BA_ "GenSigSNA" SG_ 2566849047 LDWS_FailWarnDev_Stat_ICUC "Fh";
BA_ "FlexKomIsMotorola" SG_ 2566849047 LDWS_FailWarnDev_Stat_ICUC 1;
BA_ "FlexKomComment" SG_ 2566849047 LDWS_FailWarnDev_Stat_ICUC "ICUC_C6_Pkt";
BA_ "FlexKomSigName" SG_ 2566849047 LDWS_FailWarnDev_Stat_ICUC "ICUC_C6_Pkt";
BA_ "FlexKomSigLaenge" SG_ 2566849047 LDWS_FailWarnDev_Stat_ICUC 32;
BA_ "FlexKomSigStartPos" SG_ 2566849047 LDWS_FailWarnDev_Stat_ICUC 7;
BA_ "FlexKomSID" SG_ 2566849047 LDWS_FailWarnDev_Stat_ICUC 100673969;
BA_ "GenSigTimeout_MPC2" SG_ 2566849047 LDWS_FailWarnDev_Stat_ICUC 5500;
BA_ "GenSigStartValue" SG_ 2566849047 LDWS_FailWarnDev_Stat_ICUC 15;
BA_ "FlexKomSigStartValue" SG_ 2566849047 LDWS_FailWarnDev_Stat_ICUC "0FFF0FFFh";
BA_ "GenSigCycleTime" SG_ 2566849047 LDWS_FailWarnDev_Stat_ICUC 1000;
BA_ "GenSigSendType" SG_ 2566849047 LDWS_FailWarnDev_Stat_ICUC 5;
BA_ "GenSigSNA" SG_ 2566849151 VidCapVideoID_MPC2 "FFh";
BA_ "FlexKomIsMotorola" SG_ 2566849151 VidCapVideoID_MPC2 1;
BA_ "FlexKomSigLaenge" SG_ 2566849151 VidCapVideoID_MPC2 64;
BA_ "FlexKomSigStartPos" SG_ 2566849151 VidCapVideoID_MPC2 7;
BA_ "FlexKomComment" SG_ 2566849151 VidCapVideoID_MPC2 "MPC C40 Packet";
BA_ "FlexKomSigName" SG_ 2566849151 VidCapVideoID_MPC2 "MPC_C40_Pkt";
BA_ "FlexKomSID" SG_ 2566849151 VidCapVideoID_MPC2 100680492;
BA_ "GenSigStartValue" SG_ 2566849151 VidCapVideoID_MPC2 255;
BA_ "FlexKomSigStartValue" SG_ 2566849151 VidCapVideoID_MPC2 "FFFFFFFFFFFFFFFFh";
BA_ "GenSigCycleTime" SG_ 2566849151 VidCapVideoID_MPC2 1000;
BA_ "GenSigSendType" SG_ 2566849151 VidCapVideoID_MPC2 5;
BA_ "GenSigSNA" SG_ 2566849151 SuppSign3_MPC "FFh";
BA_ "FlexKomIsMotorola" SG_ 2566849151 SuppSign3_MPC 1;
BA_ "FlexKomComment" SG_ 2566849151 SuppSign3_MPC "MPC C40 Packet";
BA_ "FlexKomSigName" SG_ 2566849151 SuppSign3_MPC "MPC_C40_Pkt";
BA_ "FlexKomSigLaenge" SG_ 2566849151 SuppSign3_MPC 64;
BA_ "FlexKomSigStartPos" SG_ 2566849151 SuppSign3_MPC 7;
BA_ "FlexKomSID" SG_ 2566849151 SuppSign3_MPC 100680492;
BA_ "GenSigStartValue" SG_ 2566849151 SuppSign3_MPC 255;
BA_ "FlexKomSigStartValue" SG_ 2566849151 SuppSign3_MPC "FFFFFFFFFFFFFFFFh";
BA_ "GenSigCycleTime" SG_ 2566849151 SuppSign3_MPC 1000;
BA_ "GenSigSendType" SG_ 2566849151 SuppSign3_MPC 5;
BA_ "GenSigSNA" SG_ 2566849151 SuppSign4_MPC "FFh";
BA_ "FlexKomIsMotorola" SG_ 2566849151 SuppSign4_MPC 1;
BA_ "FlexKomComment" SG_ 2566849151 SuppSign4_MPC "MPC C40 Packet";
BA_ "FlexKomSigName" SG_ 2566849151 SuppSign4_MPC "MPC_C40_Pkt";
BA_ "FlexKomSigLaenge" SG_ 2566849151 SuppSign4_MPC 64;
BA_ "FlexKomSigStartPos" SG_ 2566849151 SuppSign4_MPC 7;
BA_ "FlexKomSID" SG_ 2566849151 SuppSign4_MPC 100680492;
BA_ "GenSigStartValue" SG_ 2566849151 SuppSign4_MPC 255;
BA_ "FlexKomSigStartValue" SG_ 2566849151 SuppSign4_MPC "FFFFFFFFFFFFFFFFh";
BA_ "GenSigCycleTime" SG_ 2566849151 SuppSign4_MPC 1000;
BA_ "GenSigSendType" SG_ 2566849151 SuppSign4_MPC 5;
BA_ "GenSigSNA" SG_ 2566849151 VehSpdLim_Rq_MPC "FFFFh";
BA_ "FlexKomIsMotorola" SG_ 2566849151 VehSpdLim_Rq_MPC 1;
BA_ "FlexKomComment" SG_ 2566849151 VehSpdLim_Rq_MPC "MPC C40 Packet";
BA_ "FlexKomSigName" SG_ 2566849151 VehSpdLim_Rq_MPC "MPC_C40_Pkt";
BA_ "FlexKomSigLaenge" SG_ 2566849151 VehSpdLim_Rq_MPC 64;
BA_ "FlexKomSigStartPos" SG_ 2566849151 VehSpdLim_Rq_MPC 7;
BA_ "FlexKomSID" SG_ 2566849151 VehSpdLim_Rq_MPC 100680492;
BA_ "GenSigStartValue" SG_ 2566849151 VehSpdLim_Rq_MPC 65535;
BA_ "FlexKomSigStartValue" SG_ 2566849151 VehSpdLim_Rq_MPC "FFFFFFFFFFFFFFFFh";
BA_ "GenSigCycleTime" SG_ 2566849151 VehSpdLim_Rq_MPC 1000;
BA_ "GenSigSendType" SG_ 2566849151 VehSpdLim_Rq_MPC 5;
BA_ "GenSigSNA" SG_ 2566849151 VidCapFileAvl_Stat_MPC2 "3h";
BA_ "FlexKomIsMotorola" SG_ 2566849151 VidCapFileAvl_Stat_MPC2 1;
BA_ "FlexKomComment" SG_ 2566849151 VidCapFileAvl_Stat_MPC2 "MPC C40 Packet";
BA_ "FlexKomSigName" SG_ 2566849151 VidCapFileAvl_Stat_MPC2 "MPC_C40_Pkt";
BA_ "FlexKomSigLaenge" SG_ 2566849151 VidCapFileAvl_Stat_MPC2 64;
BA_ "FlexKomSigStartPos" SG_ 2566849151 VidCapFileAvl_Stat_MPC2 7;
BA_ "FlexKomSID" SG_ 2566849151 VidCapFileAvl_Stat_MPC2 100680492;
BA_ "GenSigStartValue" SG_ 2566849151 VidCapFileAvl_Stat_MPC2 3;
BA_ "FlexKomSigStartValue" SG_ 2566849151 VidCapFileAvl_Stat_MPC2 "FFFFFFFFFFFFFFFFh";
BA_ "GenSigCycleTime" SG_ 2566849151 VidCapFileAvl_Stat_MPC2 1000;
BA_ "GenSigSendType" SG_ 2566849151 VidCapFileAvl_Stat_MPC2 5;
BA_ "GenSigSNA" SG_ 2566849151 PassingMvreEstm_Stat_MPC "3h";
BA_ "FlexKomIsMotorola" SG_ 2566849151 PassingMvreEstm_Stat_MPC 1;
BA_ "FlexKomComment" SG_ 2566849151 PassingMvreEstm_Stat_MPC "MPC C40 Packet";
BA_ "FlexKomSigName" SG_ 2566849151 PassingMvreEstm_Stat_MPC "MPC_C40_Pkt";
BA_ "FlexKomSigLaenge" SG_ 2566849151 PassingMvreEstm_Stat_MPC 64;
BA_ "FlexKomSigStartPos" SG_ 2566849151 PassingMvreEstm_Stat_MPC 7;
BA_ "FlexKomSID" SG_ 2566849151 PassingMvreEstm_Stat_MPC 100680492;
BA_ "GenSigStartValue" SG_ 2566849151 PassingMvreEstm_Stat_MPC 3;
BA_ "FlexKomSigStartValue" SG_ 2566849151 PassingMvreEstm_Stat_MPC "FFFFFFFFFFFFFFFFh";
BA_ "GenSigCycleTime" SG_ 2566849151 PassingMvreEstm_Stat_MPC 1000;
BA_ "GenSigSendType" SG_ 2566849151 PassingMvreEstm_Stat_MPC 5;
BA_ "GenSigSNA" SG_ 2566850337 RainSensOpMod_Stat "3h";
BA_ "FlexKomIsMotorola" SG_ 2566850337 RainSensOpMod_Stat 1;
BA_ "FlexKomComment" SG_ 2566850337 RainSensOpMod_Stat "Rain sensor operation mode";
BA_ "FlexKomSigName" SG_ 2566850337 RainSensOpMod_Stat "RainSensOpMod_Stat";
BA_ "FlexKomSigLaenge" SG_ 2566850337 RainSensOpMod_Stat 2;
BA_ "FlexKomSigStartPos" SG_ 2566850337 RainSensOpMod_Stat 15;
BA_ "FlexKomSID" SG_ 2566850337 RainSensOpMod_Stat 100673540;
BA_ "GenSigTimeout_MPC2" SG_ 2566850337 RainSensOpMod_Stat 10500;
BA_ "GenSigStartValue" SG_ 2566850337 RainSensOpMod_Stat 3;
BA_ "FlexKomSigStartValue" SG_ 2566850337 RainSensOpMod_Stat "03h";
BA_ "GenSigCycleTime" SG_ 2566850337 RainSensOpMod_Stat 1000;
BA_ "GenSigSendType" SG_ 2566850337 RainSensOpMod_Stat 5;
BA_ "GenSigSNA" SG_ 2566850337 RainSensSensitivity_Stat "Fh";
BA_ "FlexKomIsMotorola" SG_ 2566850337 RainSensSensitivity_Stat 1;
BA_ "FlexKomComment" SG_ 2566850337 RainSensSensitivity_Stat "Sensitivity of the rain sensor";
BA_ "FlexKomSigName" SG_ 2566850337 RainSensSensitivity_Stat "RainSensSensitivity_Stat";
BA_ "FlexKomSigLaenge" SG_ 2566850337 RainSensSensitivity_Stat 4;
BA_ "FlexKomSigStartPos" SG_ 2566850337 RainSensSensitivity_Stat 35;
BA_ "FlexKomSID" SG_ 2566850337 RainSensSensitivity_Stat 100673539;
BA_ "GenSigTimeout_MPC2" SG_ 2566850337 RainSensSensitivity_Stat 10500;
BA_ "GenSigStartValue" SG_ 2566850337 RainSensSensitivity_Stat 15;
BA_ "FlexKomSigStartValue" SG_ 2566850337 RainSensSensitivity_Stat "0Fh";
BA_ "GenSigCycleTime" SG_ 2566850337 RainSensSensitivity_Stat 1000;
BA_ "GenSigSendType" SG_ 2566850337 RainSensSensitivity_Stat 5;
BA_ "GenSigTimeout_MPC2" SG_ 2566850378 VidCapPreTrigLength 10500;
BA_ "GenSigSNA" SG_ 2566850378 VidCapPreTrigLength "FFh";
BA_ "FlexKomIsMotorola" SG_ 2566850378 VidCapPreTrigLength 1;
BA_ "FlexKomSigLaenge" SG_ 2566850378 VidCapPreTrigLength 32;
BA_ "FlexKomSigStartPos" SG_ 2566850378 VidCapPreTrigLength 7;
BA_ "FlexKomSigName" SG_ 2566850378 VidCapPreTrigLength "CTP_C07_Pkt";
BA_ "FlexKomSID" SG_ 2566850378 VidCapPreTrigLength 100682906;
BA_ "GenSigStartValue" SG_ 2566850378 VidCapPreTrigLength 255;
BA_ "FlexKomSigStartValue" SG_ 2566850378 VidCapPreTrigLength "FFFFFFFFh";
BA_ "GenSigCycleTime" SG_ 2566850378 VidCapPreTrigLength 1000;
BA_ "FlexKomComment" SG_ 2566850378 VidCapPreTrigLength "CTP_C07";
BA_ "GenSigTimeout_MPC2" SG_ 2566850378 VidCapLength 10500;
BA_ "GenSigSNA" SG_ 2566850378 VidCapLength "FFh";
BA_ "FlexKomIsMotorola" SG_ 2566850378 VidCapLength 1;
BA_ "FlexKomSigLaenge" SG_ 2566850378 VidCapLength 32;
BA_ "FlexKomSigStartPos" SG_ 2566850378 VidCapLength 7;
BA_ "FlexKomSigName" SG_ 2566850378 VidCapLength "CTP_C07_Pkt";
BA_ "FlexKomSID" SG_ 2566850378 VidCapLength 100682906;
BA_ "GenSigStartValue" SG_ 2566850378 VidCapLength 255;
BA_ "FlexKomSigStartValue" SG_ 2566850378 VidCapLength "FFFFFFFFh";
BA_ "GenSigCycleTime" SG_ 2566850378 VidCapLength 1000;
BA_ "FlexKomComment" SG_ 2566850378 VidCapLength "CTP_C07";
BA_ "GenSigTimeout_MPC2" SG_ 2566850378 VidCapLabel 10500;
BA_ "GenSigSNA" SG_ 2566850378 VidCapLabel "FFh";
BA_ "FlexKomIsMotorola" SG_ 2566850378 VidCapLabel 1;
BA_ "FlexKomSigLaenge" SG_ 2566850378 VidCapLabel 32;
BA_ "FlexKomSigStartPos" SG_ 2566850378 VidCapLabel 7;
BA_ "FlexKomComment" SG_ 2566850378 VidCapLabel "CTP C07";
BA_ "FlexKomSigName" SG_ 2566850378 VidCapLabel "CTP_C07_Pkt";
BA_ "FlexKomSID" SG_ 2566850378 VidCapLabel 100682906;
BA_ "GenSigStartValue" SG_ 2566850378 VidCapLabel 255;
BA_ "FlexKomSigStartValue" SG_ 2566850378 VidCapLabel "FFFFFFFFh";
BA_ "GenSigCycleTime" SG_ 2566850378 VidCapLabel 1000;
BA_ "GenSigStartValue" SG_ 2566850378 VidCapRec_Stat 3;
BA_ "FlexKomIsMotorola" SG_ 2566850378 VidCapRec_Stat 1;
BA_ "GenSigTimeout_MPC2" SG_ 2566850378 VidCapRec_Stat 10500;
BA_ "GenSigSNA" SG_ 2566850378 VidCapRec_Stat "3h";
BA_ "FlexKomSigLaenge" SG_ 2566850378 VidCapRec_Stat 32;
BA_ "FlexKomSigStartPos" SG_ 2566850378 VidCapRec_Stat 7;
BA_ "FlexKomComment" SG_ 2566850378 VidCapRec_Stat "CTP_C07";
BA_ "FlexKomSigName" SG_ 2566850378 VidCapRec_Stat "CTP_C07_Pkt";
BA_ "FlexKomSID" SG_ 2566850378 VidCapRec_Stat 100682906;
BA_ "FlexKomSigStartValue" SG_ 2566850378 VidCapRec_Stat "FFFFFFFFh";
BA_ "GenSigCycleTime" SG_ 2566850378 VidCapRec_Stat 1000;
BA_ "GenSigSNA" SG_ 2566850378 VidFileTrf_Stat "3h";
BA_ "FlexKomIsMotorola" SG_ 2566850378 VidFileTrf_Stat 1;
BA_ "FlexKomComment" SG_ 2566850378 VidFileTrf_Stat "CTP C07";
BA_ "FlexKomSigName" SG_ 2566850378 VidFileTrf_Stat "CTP_C07_Pkt";
BA_ "FlexKomSigLaenge" SG_ 2566850378 VidFileTrf_Stat 32;
BA_ "FlexKomSigStartPos" SG_ 2566850378 VidFileTrf_Stat 7;
BA_ "FlexKomSID" SG_ 2566850378 VidFileTrf_Stat 100682906;
BA_ "GenSigTimeout_MPC2" SG_ 2566850378 VidFileTrf_Stat 10500;
BA_ "GenSigStartValue" SG_ 2566850378 VidFileTrf_Stat 3;
BA_ "FlexKomSigStartValue" SG_ 2566850378 VidFileTrf_Stat "FFFFFFFFh";
BA_ "GenSigCycleTime" SG_ 2566850378 VidFileTrf_Stat 1000;
BA_ "GenSigSNA" SG_ 2566850593 WprSpd_Stat "3h";
BA_ "FlexKomIsMotorola" SG_ 2566850593 WprSpd_Stat 1;
BA_ "FlexKomComment" SG_ 2566850593 WprSpd_Stat "Whiper Speed Current state";
BA_ "FlexKomSigName" SG_ 2566850593 WprSpd_Stat "WprSpd_Stat";
BA_ "FlexKomSigLaenge" SG_ 2566850593 WprSpd_Stat 2;
BA_ "FlexKomSigStartPos" SG_ 2566850593 WprSpd_Stat 35;
BA_ "FlexKomSID" SG_ 2566850593 WprSpd_Stat 100680497;
BA_ "GenSigTimeout_MPC2" SG_ 2566850593 WprSpd_Stat 10500;
BA_ "GenSigStartValue" SG_ 2566850593 WprSpd_Stat 3;
BA_ "FlexKomSigStartValue" SG_ 2566850593 WprSpd_Stat "03h";
BA_ "GenSigCycleTime" SG_ 2566850593 WprSpd_Stat 1000;
BA_ "GenSigSendType" SG_ 2566850593 WprSpd_Stat 5;
BA_ "GenSigSNA" SG_ 2566851873 LDWS_FailWarnDev_Stat_SAM "Fh";
BA_ "FlexKomIsMotorola" SG_ 2566851873 LDWS_FailWarnDev_Stat_SAM 1;
BA_ "FlexKomComment" SG_ 2566851873 LDWS_FailWarnDev_Stat_SAM "LDWS Failure Warning Device Current state SAM";
BA_ "FlexKomSigName" SG_ 2566851873 LDWS_FailWarnDev_Stat_SAM "LDWS_FailWarnDev_Stat_SAM";
BA_ "FlexKomSigLaenge" SG_ 2566851873 LDWS_FailWarnDev_Stat_SAM 4;
BA_ "FlexKomSigStartPos" SG_ 2566851873 LDWS_FailWarnDev_Stat_SAM 23;
BA_ "FlexKomSID" SG_ 2566851873 LDWS_FailWarnDev_Stat_SAM 100682136;
BA_ "GenSigTimeout_MPC2" SG_ 2566851873 LDWS_FailWarnDev_Stat_SAM 10500;
BA_ "GenSigStartValue" SG_ 2566851873 LDWS_FailWarnDev_Stat_SAM 15;
BA_ "FlexKomSigStartValue" SG_ 2566851873 LDWS_FailWarnDev_Stat_SAM "0Fh";
BA_ "GenSigCycleTime" SG_ 2566851873 LDWS_FailWarnDev_Stat_SAM 1000;
BA_ "GenSigSendType" SG_ 2566851873 LDWS_FailWarnDev_Stat_SAM 5;
BA_ "GenSigSNA" SG_ 2566860172 LDWS_FailWarnDev_Stat_MUX3 "Fh";
BA_ "FlexKomIsMotorola" SG_ 2566860172 LDWS_FailWarnDev_Stat_MUX3 1;
BA_ "FlexKomComment" SG_ 2566860172 LDWS_FailWarnDev_Stat_MUX3 "LDWS Failure Warning Device Current state MUX3";
BA_ "FlexKomSigName" SG_ 2566860172 LDWS_FailWarnDev_Stat_MUX3 "LDWS_FailWarnDev_Stat_MUX3";
BA_ "FlexKomSigLaenge" SG_ 2566860172 LDWS_FailWarnDev_Stat_MUX3 4;
BA_ "FlexKomSigStartPos" SG_ 2566860172 LDWS_FailWarnDev_Stat_MUX3 3;
BA_ "FlexKomSID" SG_ 2566860172 LDWS_FailWarnDev_Stat_MUX3 100677021;
BA_ "GenSigTimeout_MPC2" SG_ 2566860172 LDWS_FailWarnDev_Stat_MUX3 5500;
BA_ "GenSigStartValue" SG_ 2566860172 LDWS_FailWarnDev_Stat_MUX3 15;
BA_ "FlexKomSigStartValue" SG_ 2566860172 LDWS_FailWarnDev_Stat_MUX3 "0Fh";
BA_ "GenSigCycleTime" SG_ 2566860172 LDWS_FailWarnDev_Stat_MUX3 1000;
BA_ "GenSigSendType" SG_ 2566860172 LDWS_FailWarnDev_Stat_MUX3 5;
BA_ "GenSigSNA" SG_ 2566881280 NM_Mode "FFh";
BA_ "FlexKomIsMotorola" SG_ 2566881280 NM_Mode 1;
BA_ "FlexKomComment" SG_ 2566881280 NM_Mode "Network management state";
BA_ "FlexKomSigName" SG_ 2566881280 NM_Mode "NM";
BA_ "FlexKomSigLaenge" SG_ 2566881280 NM_Mode 32;
BA_ "FlexKomSigStartPos" SG_ 2566881280 NM_Mode 7;
BA_ "FlexKomSID" SG_ 2566881280 NM_Mode 100663296;
BA_ "GenSigStartValue" SG_ 2566881280 NM_Mode 255;
BA_ "FlexKomSigStartValue" SG_ 2566881280 NM_Mode "FFFFFFFFh";
BA_ "GenSigSNA" SG_ 2566881280 NM_Successor "FFh";
BA_ "FlexKomIsMotorola" SG_ 2566881280 NM_Successor 1;
BA_ "FlexKomComment" SG_ 2566881280 NM_Successor "Network management state";
BA_ "FlexKomSigName" SG_ 2566881280 NM_Successor "NM";
BA_ "FlexKomSigLaenge" SG_ 2566881280 NM_Successor 32;
BA_ "FlexKomSigStartPos" SG_ 2566881280 NM_Successor 7;
BA_ "FlexKomSID" SG_ 2566881280 NM_Successor 100663296;
BA_ "GenSigStartValue" SG_ 2566881280 NM_Successor 255;
BA_ "FlexKomSigStartValue" SG_ 2566881280 NM_Successor "FFFFFFFFh";
BA_ "GenSigSNA" SG_ 2566881280 NM_Ud_Launch "3Fh";
BA_ "FlexKomIsMotorola" SG_ 2566881280 NM_Ud_Launch 1;
BA_ "FlexKomComment" SG_ 2566881280 NM_Ud_Launch "Network management state";
BA_ "FlexKomSigName" SG_ 2566881280 NM_Ud_Launch "NM";
BA_ "FlexKomSigLaenge" SG_ 2566881280 NM_Ud_Launch 32;
BA_ "FlexKomSigStartPos" SG_ 2566881280 NM_Ud_Launch 7;
BA_ "FlexKomSID" SG_ 2566881280 NM_Ud_Launch 100663296;
BA_ "GenSigStartValue" SG_ 2566881280 NM_Ud_Launch 63;
BA_ "FlexKomSigStartValue" SG_ 2566881280 NM_Ud_Launch "FFFFFFFFh";
BA_ "GenSigSNA" SG_ 2566881280 NM_Sleep_Ack "1h";
BA_ "FlexKomIsMotorola" SG_ 2566881280 NM_Sleep_Ack 1;
BA_ "FlexKomComment" SG_ 2566881280 NM_Sleep_Ack "Network management state";
BA_ "FlexKomSigName" SG_ 2566881280 NM_Sleep_Ack "NM";
BA_ "FlexKomSigLaenge" SG_ 2566881280 NM_Sleep_Ack 32;
BA_ "FlexKomSigStartPos" SG_ 2566881280 NM_Sleep_Ack 7;
BA_ "FlexKomSID" SG_ 2566881280 NM_Sleep_Ack 100663296;
BA_ "GenSigStartValue" SG_ 2566881280 NM_Sleep_Ack 1;
BA_ "FlexKomSigStartValue" SG_ 2566881280 NM_Sleep_Ack "FFFFFFFFh";
BA_ "GenSigSNA" SG_ 2566881280 NM_Sleep_Ind "1h";
BA_ "FlexKomIsMotorola" SG_ 2566881280 NM_Sleep_Ind 1;
BA_ "FlexKomComment" SG_ 2566881280 NM_Sleep_Ind "Network management state";
BA_ "FlexKomSigName" SG_ 2566881280 NM_Sleep_Ind "NM";
BA_ "FlexKomSigLaenge" SG_ 2566881280 NM_Sleep_Ind 32;
BA_ "FlexKomSigStartPos" SG_ 2566881280 NM_Sleep_Ind 7;
BA_ "FlexKomSID" SG_ 2566881280 NM_Sleep_Ind 100663296;
BA_ "GenSigStartValue" SG_ 2566881280 NM_Sleep_Ind 1;
BA_ "FlexKomSigStartValue" SG_ 2566881280 NM_Sleep_Ind "FFFFFFFFh";
BA_ "GenSigSNA" SG_ 2566881280 NM_Ud_Srv "FFh";
BA_ "FlexKomIsMotorola" SG_ 2566881280 NM_Ud_Srv 1;
BA_ "FlexKomComment" SG_ 2566881280 NM_Ud_Srv "Network management state";
BA_ "FlexKomSigName" SG_ 2566881280 NM_Ud_Srv "NM";
BA_ "FlexKomSigLaenge" SG_ 2566881280 NM_Ud_Srv 32;
BA_ "FlexKomSigStartPos" SG_ 2566881280 NM_Ud_Srv 7;
BA_ "FlexKomSID" SG_ 2566881280 NM_Ud_Srv 100663296;
BA_ "GenSigStartValue" SG_ 2566881280 NM_Ud_Srv 255;
BA_ "FlexKomSigStartValue" SG_ 2566881280 NM_Ud_Srv "FFFFFFFFh";
BA_ "GenSigSNA" SG_ 2566881280 WakeupRsn_MPC "FFh";
BA_ "FlexKomIsMotorola" SG_ 2566881280 WakeupRsn_MPC 1;
BA_ "FlexKomComment" SG_ 2566881280 WakeupRsn_MPC "Userdata wakeup reason (02h)";
BA_ "FlexKomSigName" SG_ 2566881280 WakeupRsn_MPC "Wakeup_MPC";
BA_ "FlexKomSigLaenge" SG_ 2566881280 WakeupRsn_MPC 24;
BA_ "FlexKomSigStartPos" SG_ 2566881280 WakeupRsn_MPC 39;
BA_ "FlexKomSID" SG_ 2566881280 WakeupRsn_MPC 100676530;
BA_ "GenSigStartValue" SG_ 2566881280 WakeupRsn_MPC 255;
BA_ "FlexKomSigStartValue" SG_ 2566881280 WakeupRsn_MPC "FFFFFFh";
BA_ "GenSigSNA" SG_ 2566881280 Awake_NwSt "0h";
BA_ "FlexKomIsMotorola" SG_ 2566881280 Awake_NwSt 1;
BA_ "FlexKomComment" SG_ 2566881280 Awake_NwSt "Userdata stay awake reason (0Fh)";
BA_ "FlexKomSigName" SG_ 2566881280 Awake_NwSt "Awake_MPC";
BA_ "FlexKomSigLaenge" SG_ 2566881280 Awake_NwSt 24;
BA_ "FlexKomSigStartPos" SG_ 2566881280 Awake_NwSt 39;
BA_ "FlexKomSID" SG_ 2566881280 Awake_NwSt 100676529;
BA_ "FlexKomSigStartValue" SG_ 2566881280 Awake_NwSt "C8FFFFh";
BA_ "GenSigSNA" SG_ 2566881280 Awake_Diag_Actv "0h";
BA_ "FlexKomIsMotorola" SG_ 2566881280 Awake_Diag_Actv 1;
BA_ "FlexKomComment" SG_ 2566881280 Awake_Diag_Actv "Userdata stay awake reason (0Fh)";
BA_ "FlexKomSigName" SG_ 2566881280 Awake_Diag_Actv "Awake_MPC";
BA_ "FlexKomSigLaenge" SG_ 2566881280 Awake_Diag_Actv 24;
BA_ "FlexKomSigStartPos" SG_ 2566881280 Awake_Diag_Actv 39;
BA_ "FlexKomSID" SG_ 2566881280 Awake_Diag_Actv 100676529;
BA_ "FlexKomSigStartValue" SG_ 2566881280 Awake_Diag_Actv "C8FFFFh";
BA_ "GenSigSNA" SG_ 2566881280 Awake_IgnOn "0h";
BA_ "FlexKomIsMotorola" SG_ 2566881280 Awake_IgnOn 1;
BA_ "FlexKomComment" SG_ 2566881280 Awake_IgnOn "Userdata stay awake reason (0Fh)";
BA_ "FlexKomSigName" SG_ 2566881280 Awake_IgnOn "Awake_MPC";
BA_ "FlexKomSigLaenge" SG_ 2566881280 Awake_IgnOn 24;
BA_ "FlexKomSigStartPos" SG_ 2566881280 Awake_IgnOn 39;
BA_ "FlexKomSID" SG_ 2566881280 Awake_IgnOn 100676529;
BA_ "FlexKomSigStartValue" SG_ 2566881280 Awake_IgnOn "C8FFFFh";
BA_ "GenSigSNA" SG_ 2566881280 Awake_XCP_Diag "0h";
BA_ "FlexKomIsMotorola" SG_ 2566881280 Awake_XCP_Diag 1;
BA_ "FlexKomComment" SG_ 2566881280 Awake_XCP_Diag "Userdata stay awake reason (0Fh)";
BA_ "FlexKomSigName" SG_ 2566881280 Awake_XCP_Diag "Awake_MPC";
BA_ "FlexKomSigLaenge" SG_ 2566881280 Awake_XCP_Diag 24;
BA_ "FlexKomSigStartPos" SG_ 2566881280 Awake_XCP_Diag 39;
BA_ "FlexKomSID" SG_ 2566881280 Awake_XCP_Diag 100676529;
BA_ "FlexKomSigStartValue" SG_ 2566881280 Awake_XCP_Diag "C8FFFFh";
BA_ "GenSigSNA" SG_ 2566881280 Awake_VC_TrfData "0h";
BA_ "FlexKomIsMotorola" SG_ 2566881280 Awake_VC_TrfData 1;
BA_ "FlexKomComment" SG_ 2566881280 Awake_VC_TrfData "Userdata stay awake reason (0Fh)";
BA_ "FlexKomSigName" SG_ 2566881280 Awake_VC_TrfData "Awake_MPC";
BA_ "FlexKomSigLaenge" SG_ 2566881280 Awake_VC_TrfData 24;
BA_ "FlexKomSigStartPos" SG_ 2566881280 Awake_VC_TrfData 39;
BA_ "FlexKomSID" SG_ 2566881280 Awake_VC_TrfData 100676529;
BA_ "FlexKomSigStartValue" SG_ 2566881280 Awake_VC_TrfData "C8FFFFh";
BA_ "GenSigSNA" SG_ 2566881280 WakeupCnt_cv "FFh";
BA_ "FlexKomIsMotorola" SG_ 2566881280 WakeupCnt_cv 1;
BA_ "FlexKomComment" SG_ 2566881280 WakeupCnt_cv "Userdata wakeup reason (02h)";
BA_ "FlexKomSigName" SG_ 2566881280 WakeupCnt_cv "Wakeup_MPC";
BA_ "FlexKomSigLaenge" SG_ 2566881280 WakeupCnt_cv 24;
BA_ "FlexKomSigStartPos" SG_ 2566881280 WakeupCnt_cv 39;
BA_ "FlexKomSID" SG_ 2566881280 WakeupCnt_cv 100676530;
BA_ "GenSigStartValue" SG_ 2566881280 WakeupCnt_cv 255;
BA_ "FlexKomSigStartValue" SG_ 2566881280 WakeupCnt_cv "FFFFFFh";
BA_ "GenSigSNA" SG_ 2566881280 Nw_Id "FFh";
BA_ "FlexKomIsMotorola" SG_ 2566881280 Nw_Id 1;
BA_ "FlexKomComment" SG_ 2566881280 Nw_Id "Network identification no.";
BA_ "FlexKomSigName" SG_ 2566881280 Nw_Id "Nw_Id";
BA_ "FlexKomSigLaenge" SG_ 2566881280 Nw_Id 8;
BA_ "FlexKomSigStartPos" SG_ 2566881280 Nw_Id 63;
BA_ "FlexKomSID" SG_ 2566881280 Nw_Id 100663330;
BA_ "GenSigStartValue" SG_ 2566881280 Nw_Id 255;
BA_ "FlexKomSigStartValue" SG_ 2566881280 Nw_Id "FFh";
BA_ "GenSigSNA" SG_ 2566897701 GVC_VehBrand "Fh";
BA_ "FlexKomIsMotorola" SG_ 2566897701 GVC_VehBrand 1;
BA_ "FlexKomComment" SG_ 2566897701 GVC_VehBrand "GVC Vehicle General Information";
BA_ "FlexKomSigName" SG_ 2566897701 GVC_VehBrand "GVC_VehInfo";
BA_ "FlexKomSigLaenge" SG_ 2566897701 GVC_VehBrand 64;
BA_ "FlexKomSigStartPos" SG_ 2566897701 GVC_VehBrand 7;
BA_ "FlexKomSID" SG_ 2566897701 GVC_VehBrand 100663902;
BA_ "GenSigStartValue" SG_ 2566897701 GVC_VehBrand 15;
BA_ "FlexKomSigStartValue" SG_ 2566897701 GVC_VehBrand "FFFFFFFFFFFFFFFFh";
BA_ "GenSigSendType" SG_ 2566897701 GVC_VehBrand 1;
BA_ "GenSigSNA" SG_ 2566897701 GVC_VehModel "Fh";
BA_ "FlexKomIsMotorola" SG_ 2566897701 GVC_VehModel 1;
BA_ "FlexKomComment" SG_ 2566897701 GVC_VehModel "GVC Vehicle General Information";
BA_ "FlexKomSigName" SG_ 2566897701 GVC_VehModel "GVC_VehInfo";
BA_ "FlexKomSigLaenge" SG_ 2566897701 GVC_VehModel 64;
BA_ "FlexKomSigStartPos" SG_ 2566897701 GVC_VehModel 7;
BA_ "FlexKomSID" SG_ 2566897701 GVC_VehModel 100663902;
BA_ "GenSigStartValue" SG_ 2566897701 GVC_VehModel 15;
BA_ "FlexKomSigStartValue" SG_ 2566897701 GVC_VehModel "FFFFFFFFFFFFFFFFh";
BA_ "GenSigSendType" SG_ 2566897701 GVC_VehModel 1;
BA_ "GenSigSNA" SG_ 2566897957 GVC_HdLmpType "Fh";
BA_ "FlexKomIsMotorola" SG_ 2566897957 GVC_HdLmpType 1;
BA_ "FlexKomComment" SG_ 2566897957 GVC_HdLmpType "GVC Message 2 Packet";
BA_ "FlexKomSigName" SG_ 2566897957 GVC_HdLmpType "GVC2_Pkt";
BA_ "FlexKomSigLaenge" SG_ 2566897957 GVC_HdLmpType 64;
BA_ "FlexKomSigStartPos" SG_ 2566897957 GVC_HdLmpType 7;
BA_ "FlexKomSID" SG_ 2566897957 GVC_HdLmpType 100663904;
BA_ "GenSigStartValue" SG_ 2566897957 GVC_HdLmpType 15;
BA_ "FlexKomSigStartValue" SG_ 2566897957 GVC_HdLmpType "FFFFFFFFFFFFFFFFh";
BA_ "GenSigSendType" SG_ 2566897957 GVC_HdLmpType 1;
BA_ "GenSigSNA" SG_ 2566897957 GVC_TrackWidth "FFh";
BA_ "FlexKomIsMotorola" SG_ 2566897957 GVC_TrackWidth 1;
BA_ "FlexKomComment" SG_ 2566897957 GVC_TrackWidth "GVC Message 2 Packet";
BA_ "FlexKomSigName" SG_ 2566897957 GVC_TrackWidth "GVC2_Pkt";
BA_ "FlexKomSigLaenge" SG_ 2566897957 GVC_TrackWidth 64;
BA_ "FlexKomSigStartPos" SG_ 2566897957 GVC_TrackWidth 7;
BA_ "FlexKomSID" SG_ 2566897957 GVC_TrackWidth 100663904;
BA_ "GenSigStartValue" SG_ 2566897957 GVC_TrackWidth 255;
BA_ "FlexKomSigStartValue" SG_ 2566897957 GVC_TrackWidth "FFFFFFFFFFFFFFFFh";
BA_ "GenSigSendType" SG_ 2566897957 GVC_TrackWidth 1;
BA_ "GenSigSNA" SG_ 2566897957 GVC_WhlBase "FFFFh";
BA_ "FlexKomIsMotorola" SG_ 2566897957 GVC_WhlBase 1;
BA_ "FlexKomComment" SG_ 2566897957 GVC_WhlBase "GVC Message 2 Packet";
BA_ "FlexKomSigName" SG_ 2566897957 GVC_WhlBase "GVC2_Pkt";
BA_ "FlexKomSigLaenge" SG_ 2566897957 GVC_WhlBase 64;
BA_ "FlexKomSigStartPos" SG_ 2566897957 GVC_WhlBase 7;
BA_ "FlexKomSID" SG_ 2566897957 GVC_WhlBase 100663904;
BA_ "GenSigStartValue" SG_ 2566897957 GVC_WhlBase 65535;
BA_ "FlexKomSigStartValue" SG_ 2566897957 GVC_WhlBase "FFFFFFFFFFFFFFFFh";
BA_ "GenSigSendType" SG_ 2566897957 GVC_WhlBase 1;
BA_ "GenSigSNA" SG_ 2566897957 GVC_LgtSens "3h";
BA_ "FlexKomIsMotorola" SG_ 2566897957 GVC_LgtSens 1;
BA_ "FlexKomComment" SG_ 2566897957 GVC_LgtSens "GVC Message 2 Packet";
BA_ "FlexKomSigName" SG_ 2566897957 GVC_LgtSens "GVC2_Pkt";
BA_ "FlexKomSigLaenge" SG_ 2566897957 GVC_LgtSens 64;
BA_ "FlexKomSigStartPos" SG_ 2566897957 GVC_LgtSens 7;
BA_ "FlexKomSID" SG_ 2566897957 GVC_LgtSens 100663904;
BA_ "GenSigStartValue" SG_ 2566897957 GVC_LgtSens 3;
BA_ "FlexKomSigStartValue" SG_ 2566897957 GVC_LgtSens "FFFFFFFFFFFFFFFFh";
BA_ "GenSigSendType" SG_ 2566897957 GVC_LgtSens 1;
BA_ "GenSigSNA" SG_ 2566898469 GVC_LDW_Func "Fh";
BA_ "FlexKomIsMotorola" SG_ 2566898469 GVC_LDW_Func 1;
BA_ "FlexKomComment" SG_ 2566898469 GVC_LDW_Func "GVC Message 4 Packet";
BA_ "FlexKomSigName" SG_ 2566898469 GVC_LDW_Func "GVC4_Pkt";
BA_ "FlexKomSigLaenge" SG_ 2566898469 GVC_LDW_Func 64;
BA_ "FlexKomSigStartPos" SG_ 2566898469 GVC_LDW_Func 7;
BA_ "FlexKomSID" SG_ 2566898469 GVC_LDW_Func 100663908;
BA_ "GenSigStartValue" SG_ 2566898469 GVC_LDW_Func 15;
BA_ "FlexKomSigStartValue" SG_ 2566898469 GVC_LDW_Func "FFFFFFFFFFFFFFFFh";
BA_ "GenSigSendType" SG_ 2566898469 GVC_LDW_Func 1;
BA_ "GenSigSNA" SG_ 2566898469 GVC_D_AttenMonFunc "3h";
BA_ "FlexKomIsMotorola" SG_ 2566898469 GVC_D_AttenMonFunc 1;
BA_ "FlexKomComment" SG_ 2566898469 GVC_D_AttenMonFunc "GVC Message 4 Packet";
BA_ "FlexKomSigName" SG_ 2566898469 GVC_D_AttenMonFunc "GVC4_Pkt";
BA_ "FlexKomSigLaenge" SG_ 2566898469 GVC_D_AttenMonFunc 64;
BA_ "FlexKomSigStartPos" SG_ 2566898469 GVC_D_AttenMonFunc 7;
BA_ "FlexKomSID" SG_ 2566898469 GVC_D_AttenMonFunc 100663908;
BA_ "GenSigStartValue" SG_ 2566898469 GVC_D_AttenMonFunc 3;
BA_ "FlexKomSigStartValue" SG_ 2566898469 GVC_D_AttenMonFunc "FFFFFFFFFFFFFFFFh";
BA_ "GenSigSendType" SG_ 2566898469 GVC_D_AttenMonFunc 1;
BA_ "GenSigSNA" SG_ 2566898469 GVC_IHC_Func "3h";
BA_ "FlexKomIsMotorola" SG_ 2566898469 GVC_IHC_Func 1;
BA_ "FlexKomComment" SG_ 2566898469 GVC_IHC_Func "GVC Message 4 Packet";
BA_ "FlexKomSigName" SG_ 2566898469 GVC_IHC_Func "GVC4_Pkt";
BA_ "FlexKomSigLaenge" SG_ 2566898469 GVC_IHC_Func 64;
BA_ "FlexKomSigStartPos" SG_ 2566898469 GVC_IHC_Func 7;
BA_ "FlexKomSID" SG_ 2566898469 GVC_IHC_Func 100663908;
BA_ "GenSigStartValue" SG_ 2566898469 GVC_IHC_Func 3;
BA_ "FlexKomSigStartValue" SG_ 2566898469 GVC_IHC_Func "FFFFFFFFFFFFFFFFh";
BA_ "GenSigSendType" SG_ 2566898469 GVC_IHC_Func 1;
BA_ "GenSigSNA" SG_ 2566899237 GVC_SysMsg_IPPC "3h";
BA_ "FlexKomIsMotorola" SG_ 2566899237 GVC_SysMsg_IPPC 1;
BA_ "FlexKomComment" SG_ 2566899237 GVC_SysMsg_IPPC "GVC Message 8 Packet";
BA_ "FlexKomSigName" SG_ 2566899237 GVC_SysMsg_IPPC "GVC8_Pkt";
BA_ "FlexKomSigLaenge" SG_ 2566899237 GVC_SysMsg_IPPC 64;
BA_ "FlexKomSigStartPos" SG_ 2566899237 GVC_SysMsg_IPPC 7;
BA_ "FlexKomSID" SG_ 2566899237 GVC_SysMsg_IPPC 100673524;
BA_ "GenSigStartValue" SG_ 2566899237 GVC_SysMsg_IPPC 3;
BA_ "FlexKomSigStartValue" SG_ 2566899237 GVC_SysMsg_IPPC "FFFFFFFFFFFFFFFFh";
BA_ "GenSigSendType" SG_ 2566899237 GVC_SysMsg_IPPC 1;
BA_ "GenSigSNA" SG_ 2566899237 VMM_VersionYear_Cval "FFh";
BA_ "FlexKomIsMotorola" SG_ 2566899237 VMM_VersionYear_Cval 1;
BA_ "FlexKomComment" SG_ 2566899237 VMM_VersionYear_Cval "GVC Message 8 Packet";
BA_ "FlexKomSigName" SG_ 2566899237 VMM_VersionYear_Cval "GVC8_Pkt";
BA_ "FlexKomSigLaenge" SG_ 2566899237 VMM_VersionYear_Cval 64;
BA_ "FlexKomSigStartPos" SG_ 2566899237 VMM_VersionYear_Cval 7;
BA_ "FlexKomSID" SG_ 2566899237 VMM_VersionYear_Cval 100673524;
BA_ "GenSigStartValue" SG_ 2566899237 VMM_VersionYear_Cval 255;
BA_ "FlexKomSigStartValue" SG_ 2566899237 VMM_VersionYear_Cval "FFFFFFFFFFFFFFFFh";
BA_ "GenSigSendType" SG_ 2566899237 VMM_VersionYear_Cval 1;
BA_ "GenSigSNA" SG_ 2566899237 VMM_VersionWeek_Cval "FFh";
BA_ "FlexKomIsMotorola" SG_ 2566899237 VMM_VersionWeek_Cval 1;
BA_ "FlexKomComment" SG_ 2566899237 VMM_VersionWeek_Cval "GVC Message 8 Packet";
BA_ "FlexKomSigName" SG_ 2566899237 VMM_VersionWeek_Cval "GVC8_Pkt";
BA_ "FlexKomSigLaenge" SG_ 2566899237 VMM_VersionWeek_Cval 64;
BA_ "FlexKomSigStartPos" SG_ 2566899237 VMM_VersionWeek_Cval 7;
BA_ "FlexKomSID" SG_ 2566899237 VMM_VersionWeek_Cval 100673524;
BA_ "GenSigStartValue" SG_ 2566899237 VMM_VersionWeek_Cval 255;
BA_ "FlexKomSigStartValue" SG_ 2566899237 VMM_VersionWeek_Cval "FFFFFFFFFFFFFFFFh";
BA_ "GenSigSendType" SG_ 2566899237 VMM_VersionWeek_Cval 1;
BA_ "GenSigSNA" SG_ 2566899493 GVC_TSR_Fct "Fh";
BA_ "FlexKomIsMotorola" SG_ 2566899493 GVC_TSR_Fct 1;
BA_ "FlexKomComment" SG_ 2566899493 GVC_TSR_Fct "GVC Message 6 Packet";
BA_ "FlexKomSigName" SG_ 2566899493 GVC_TSR_Fct "GVC6_Pkt";
BA_ "FlexKomSigLaenge" SG_ 2566899493 GVC_TSR_Fct 64;
BA_ "FlexKomSigStartPos" SG_ 2566899493 GVC_TSR_Fct 7;
BA_ "FlexKomSID" SG_ 2566899493 GVC_TSR_Fct 100676366;
BA_ "FlexKomSigStartValue" SG_ 2566899493 GVC_TSR_Fct "FFFFFFFFFFFFFF00h";
BA_ "GenSigSendType" SG_ 2566899493 GVC_TSR_Fct 1;
BA_ "GenSigSNA" SG_ 2566899749 VIN_Cntr_Stat "0h";
BA_ "FlexKomIsMotorola" SG_ 2566899749 VIN_Cntr_Stat 1;
BA_ "FlexKomComment" SG_ 2566899749 VIN_Cntr_Stat "VIN Information";
BA_ "FlexKomSigName" SG_ 2566899749 VIN_Cntr_Stat "VIN_Info";
BA_ "FlexKomSigLaenge" SG_ 2566899749 VIN_Cntr_Stat 64;
BA_ "FlexKomSigStartPos" SG_ 2566899749 VIN_Cntr_Stat 7;
BA_ "FlexKomSID" SG_ 2566899749 VIN_Cntr_Stat 100663524;
BA_ "FlexKomSigStartValue" SG_ 2566899749 VIN_Cntr_Stat "00FFFFFFFFFFFFFFh";
BA_ "GenSigSendType" SG_ 2566899749 VIN_Cntr_Stat 1;
BA_ "GenSigSNA" SG_ 2566899749 VIN_Seg "FFh";
BA_ "FlexKomIsMotorola" SG_ 2566899749 VIN_Seg 1;
BA_ "FlexKomComment" SG_ 2566899749 VIN_Seg "VIN Information";
BA_ "FlexKomSigName" SG_ 2566899749 VIN_Seg "VIN_Info";
BA_ "FlexKomSigLaenge" SG_ 2566899749 VIN_Seg 64;
BA_ "FlexKomSigStartPos" SG_ 2566899749 VIN_Seg 7;
BA_ "FlexKomSID" SG_ 2566899749 VIN_Seg 100663524;
BA_ "GenSigStartValue" SG_ 2566899749 VIN_Seg 255;
BA_ "FlexKomSigStartValue" SG_ 2566899749 VIN_Seg "00FFFFFFFFFFFFFFh";
BA_ "GenSigSendType" SG_ 2566899749 VIN_Seg 1;
BA_ "GenSigSNA" SG_ 2566899749 VIN_Seg2 "FFh";
BA_ "FlexKomIsMotorola" SG_ 2566899749 VIN_Seg2 1;
BA_ "FlexKomComment" SG_ 2566899749 VIN_Seg2 "VIN Information";
BA_ "FlexKomSigName" SG_ 2566899749 VIN_Seg2 "VIN_Info";
BA_ "FlexKomSigLaenge" SG_ 2566899749 VIN_Seg2 64;
BA_ "FlexKomSigStartPos" SG_ 2566899749 VIN_Seg2 7;
BA_ "FlexKomSID" SG_ 2566899749 VIN_Seg2 100663524;
BA_ "GenSigStartValue" SG_ 2566899749 VIN_Seg2 255;
BA_ "FlexKomSigStartValue" SG_ 2566899749 VIN_Seg2 "00FFFFFFFFFFFFFFh";
BA_ "GenSigSendType" SG_ 2566899749 VIN_Seg2 1;
BA_ "GenSigSNA" SG_ 2566899749 VIN_Seg3 "FFh";
BA_ "FlexKomIsMotorola" SG_ 2566899749 VIN_Seg3 1;
BA_ "FlexKomComment" SG_ 2566899749 VIN_Seg3 "VIN Information";
BA_ "FlexKomSigName" SG_ 2566899749 VIN_Seg3 "VIN_Info";
BA_ "FlexKomSigLaenge" SG_ 2566899749 VIN_Seg3 64;
BA_ "FlexKomSigStartPos" SG_ 2566899749 VIN_Seg3 7;
BA_ "FlexKomSID" SG_ 2566899749 VIN_Seg3 100663524;
BA_ "GenSigStartValue" SG_ 2566899749 VIN_Seg3 255;
BA_ "FlexKomSigStartValue" SG_ 2566899749 VIN_Seg3 "00FFFFFFFFFFFFFFh";
BA_ "GenSigSendType" SG_ 2566899749 VIN_Seg3 1;
BA_ "GenSigSNA" SG_ 2566899749 VIN_Seg4 "FFh";
BA_ "FlexKomIsMotorola" SG_ 2566899749 VIN_Seg4 1;
BA_ "FlexKomComment" SG_ 2566899749 VIN_Seg4 "VIN Information";
BA_ "FlexKomSigName" SG_ 2566899749 VIN_Seg4 "VIN_Info";
BA_ "FlexKomSigLaenge" SG_ 2566899749 VIN_Seg4 64;
BA_ "FlexKomSigStartPos" SG_ 2566899749 VIN_Seg4 7;
BA_ "FlexKomSID" SG_ 2566899749 VIN_Seg4 100663524;
BA_ "GenSigStartValue" SG_ 2566899749 VIN_Seg4 255;
BA_ "FlexKomSigStartValue" SG_ 2566899749 VIN_Seg4 "00FFFFFFFFFFFFFFh";
BA_ "GenSigSendType" SG_ 2566899749 VIN_Seg4 1;
BA_ "GenSigSNA" SG_ 2566899749 VIN_Seg5 "FFh";
BA_ "FlexKomIsMotorola" SG_ 2566899749 VIN_Seg5 1;
BA_ "FlexKomComment" SG_ 2566899749 VIN_Seg5 "VIN Information";
BA_ "FlexKomSigName" SG_ 2566899749 VIN_Seg5 "VIN_Info";
BA_ "FlexKomSigLaenge" SG_ 2566899749 VIN_Seg5 64;
BA_ "FlexKomSigStartPos" SG_ 2566899749 VIN_Seg5 7;
BA_ "FlexKomSID" SG_ 2566899749 VIN_Seg5 100663524;
BA_ "GenSigStartValue" SG_ 2566899749 VIN_Seg5 255;
BA_ "FlexKomSigStartValue" SG_ 2566899749 VIN_Seg5 "00FFFFFFFFFFFFFFh";
BA_ "GenSigSendType" SG_ 2566899749 VIN_Seg5 1;
BA_ "GenSigSNA" SG_ 2566899749 VIN_Seg6 "FFh";
BA_ "FlexKomIsMotorola" SG_ 2566899749 VIN_Seg6 1;
BA_ "FlexKomComment" SG_ 2566899749 VIN_Seg6 "VIN Information";
BA_ "FlexKomSigName" SG_ 2566899749 VIN_Seg6 "VIN_Info";
BA_ "FlexKomSigLaenge" SG_ 2566899749 VIN_Seg6 64;
BA_ "FlexKomSigStartPos" SG_ 2566899749 VIN_Seg6 7;
BA_ "FlexKomSID" SG_ 2566899749 VIN_Seg6 100663524;
BA_ "GenSigStartValue" SG_ 2566899749 VIN_Seg6 255;
BA_ "FlexKomSigStartValue" SG_ 2566899749 VIN_Seg6 "00FFFFFFFFFFFFFFh";
BA_ "GenSigSendType" SG_ 2566899749 VIN_Seg6 1;
BA_ "GenSigSNA" SG_ 2566899749 VIN_Seg7 "FFh";
BA_ "FlexKomIsMotorola" SG_ 2566899749 VIN_Seg7 1;
BA_ "FlexKomComment" SG_ 2566899749 VIN_Seg7 "VIN Information";
BA_ "FlexKomSigName" SG_ 2566899749 VIN_Seg7 "VIN_Info";
BA_ "FlexKomSigLaenge" SG_ 2566899749 VIN_Seg7 64;
BA_ "FlexKomSigStartPos" SG_ 2566899749 VIN_Seg7 7;
BA_ "FlexKomSID" SG_ 2566899749 VIN_Seg7 100663524;
BA_ "GenSigStartValue" SG_ 2566899749 VIN_Seg7 255;
BA_ "FlexKomSigStartValue" SG_ 2566899749 VIN_Seg7 "00FFFFFFFFFFFFFFh";
BA_ "GenSigSendType" SG_ 2566899749 VIN_Seg7 1;
BA_ "GenSigSNA" SG_ 2566900261 SteerRatioCntr_Cval "FFh";
BA_ "FlexKomIsMotorola" SG_ 2566900261 SteerRatioCntr_Cval 1;
BA_ "FlexKomComment" SG_ 2566900261 SteerRatioCntr_Cval "GVC Message 10 Packet";
BA_ "FlexKomSigName" SG_ 2566900261 SteerRatioCntr_Cval "GVC10_Pkt";
BA_ "FlexKomSigLaenge" SG_ 2566900261 SteerRatioCntr_Cval 64;
BA_ "FlexKomSigStartPos" SG_ 2566900261 SteerRatioCntr_Cval 7;
BA_ "FlexKomSID" SG_ 2566900261 SteerRatioCntr_Cval 100677473;
BA_ "GenSigStartValue" SG_ 2566900261 SteerRatioCntr_Cval 255;
BA_ "FlexKomSigStartValue" SG_ 2566900261 SteerRatioCntr_Cval "FF3FFFFFFFFFFFFFh";
BA_ "GenSigSendType" SG_ 2566900261 SteerRatioCntr_Cval 1;
BA_ "GenSigSNA" SG_ 2566900261 SteerRatioNodesCntr_Cval "Fh";
BA_ "FlexKomIsMotorola" SG_ 2566900261 SteerRatioNodesCntr_Cval 1;
BA_ "FlexKomComment" SG_ 2566900261 SteerRatioNodesCntr_Cval "GVC Message 10 Packet";
BA_ "FlexKomSigName" SG_ 2566900261 SteerRatioNodesCntr_Cval "GVC10_Pkt";
BA_ "FlexKomSigLaenge" SG_ 2566900261 SteerRatioNodesCntr_Cval 64;
BA_ "FlexKomSigStartPos" SG_ 2566900261 SteerRatioNodesCntr_Cval 7;
BA_ "FlexKomSID" SG_ 2566900261 SteerRatioNodesCntr_Cval 100677473;
BA_ "GenSigStartValue" SG_ 2566900261 SteerRatioNodesCntr_Cval 15;
BA_ "FlexKomSigStartValue" SG_ 2566900261 SteerRatioNodesCntr_Cval "FF3FFFFFFFFFFFFFh";
BA_ "GenSigSendType" SG_ 2566900261 SteerRatioNodesCntr_Cval 1;
BA_ "GenSigSNA" SG_ 2566900261 SteerRatioAnglType_Stat "3h";
BA_ "FlexKomIsMotorola" SG_ 2566900261 SteerRatioAnglType_Stat 1;
BA_ "FlexKomComment" SG_ 2566900261 SteerRatioAnglType_Stat "GVC Message 10 Packet";
BA_ "FlexKomSigName" SG_ 2566900261 SteerRatioAnglType_Stat "GVC10_Pkt";
BA_ "FlexKomSigLaenge" SG_ 2566900261 SteerRatioAnglType_Stat 64;
BA_ "FlexKomSigStartPos" SG_ 2566900261 SteerRatioAnglType_Stat 7;
BA_ "FlexKomSID" SG_ 2566900261 SteerRatioAnglType_Stat 100677473;
BA_ "GenSigStartValue" SG_ 2566900261 SteerRatioAnglType_Stat 3;
BA_ "FlexKomSigStartValue" SG_ 2566900261 SteerRatioAnglType_Stat "FF3FFFFFFFFFFFFFh";
BA_ "GenSigSendType" SG_ 2566900261 SteerRatioAnglType_Stat 1;
BA_ "GenSigSNA" SG_ 2566900261 SteerRatioMS_Stat "3h";
BA_ "FlexKomIsMotorola" SG_ 2566900261 SteerRatioMS_Stat 1;
BA_ "FlexKomComment" SG_ 2566900261 SteerRatioMS_Stat "GVC Message 10 Packet";
BA_ "FlexKomSigName" SG_ 2566900261 SteerRatioMS_Stat "GVC10_Pkt";
BA_ "FlexKomSigLaenge" SG_ 2566900261 SteerRatioMS_Stat 64;
BA_ "FlexKomSigStartPos" SG_ 2566900261 SteerRatioMS_Stat 7;
BA_ "FlexKomSID" SG_ 2566900261 SteerRatioMS_Stat 100677473;
BA_ "FlexKomSigStartValue" SG_ 2566900261 SteerRatioMS_Stat "FF3FFFFFFFFFFFFFh";
BA_ "GenSigSendType" SG_ 2566900261 SteerRatioMS_Stat 1;
BA_ "GenSigSNA" SG_ 2566900261 FirstNdCntX_SteerRatio_Cval "FFh";
BA_ "FlexKomIsMotorola" SG_ 2566900261 FirstNdCntX_SteerRatio_Cval 1;
BA_ "FlexKomComment" SG_ 2566900261 FirstNdCntX_SteerRatio_Cval "GVC Message 10 Packet";
BA_ "FlexKomSigName" SG_ 2566900261 FirstNdCntX_SteerRatio_Cval "GVC10_Pkt";
BA_ "FlexKomSigLaenge" SG_ 2566900261 FirstNdCntX_SteerRatio_Cval 64;
BA_ "FlexKomSigStartPos" SG_ 2566900261 FirstNdCntX_SteerRatio_Cval 7;
BA_ "FlexKomSID" SG_ 2566900261 FirstNdCntX_SteerRatio_Cval 100677473;
BA_ "GenSigStartValue" SG_ 2566900261 FirstNdCntX_SteerRatio_Cval 255;
BA_ "FlexKomSigStartValue" SG_ 2566900261 FirstNdCntX_SteerRatio_Cval "FF3FFFFFFFFFFFFFh";
BA_ "GenSigSendType" SG_ 2566900261 FirstNdCntX_SteerRatio_Cval 1;
BA_ "GenSigSNA" SG_ 2566900261 SecNdCntX_SteerRatio_Cval "FFh";
BA_ "FlexKomIsMotorola" SG_ 2566900261 SecNdCntX_SteerRatio_Cval 1;
BA_ "FlexKomComment" SG_ 2566900261 SecNdCntX_SteerRatio_Cval "GVC Message 10 Packet";
BA_ "FlexKomSigName" SG_ 2566900261 SecNdCntX_SteerRatio_Cval "GVC10_Pkt";
BA_ "FlexKomSigLaenge" SG_ 2566900261 SecNdCntX_SteerRatio_Cval 64;
BA_ "FlexKomSigStartPos" SG_ 2566900261 SecNdCntX_SteerRatio_Cval 7;
BA_ "FlexKomSID" SG_ 2566900261 SecNdCntX_SteerRatio_Cval 100677473;
BA_ "GenSigStartValue" SG_ 2566900261 SecNdCntX_SteerRatio_Cval 255;
BA_ "FlexKomSigStartValue" SG_ 2566900261 SecNdCntX_SteerRatio_Cval "FF3FFFFFFFFFFFFFh";
BA_ "GenSigSendType" SG_ 2566900261 SecNdCntX_SteerRatio_Cval 1;
BA_ "GenSigSNA" SG_ 2566900261 FirstNdCntX_AnglDeg_Cval "FFFFh";
BA_ "FlexKomIsMotorola" SG_ 2566900261 FirstNdCntX_AnglDeg_Cval 1;
BA_ "FlexKomComment" SG_ 2566900261 FirstNdCntX_AnglDeg_Cval "GVC Message 10 Packet";
BA_ "FlexKomSigName" SG_ 2566900261 FirstNdCntX_AnglDeg_Cval "GVC10_Pkt";
BA_ "FlexKomSigLaenge" SG_ 2566900261 FirstNdCntX_AnglDeg_Cval 64;
BA_ "FlexKomSigStartPos" SG_ 2566900261 FirstNdCntX_AnglDeg_Cval 7;
BA_ "FlexKomSID" SG_ 2566900261 FirstNdCntX_AnglDeg_Cval 100677473;
BA_ "GenSigStartValue" SG_ 2566900261 FirstNdCntX_AnglDeg_Cval 65535;
BA_ "FlexKomSigStartValue" SG_ 2566900261 FirstNdCntX_AnglDeg_Cval "FF3FFFFFFFFFFFFFh";
BA_ "GenSigSendType" SG_ 2566900261 FirstNdCntX_AnglDeg_Cval 1;
BA_ "GenSigSNA" SG_ 2566900261 FirstNdCntX_AnglRad_Cval "FFFFh";
BA_ "FlexKomIsMotorola" SG_ 2566900261 FirstNdCntX_AnglRad_Cval 1;
BA_ "FlexKomComment" SG_ 2566900261 FirstNdCntX_AnglRad_Cval "GVC Message 10 Packet";
BA_ "FlexKomSigName" SG_ 2566900261 FirstNdCntX_AnglRad_Cval "GVC10_Pkt";
BA_ "FlexKomSigLaenge" SG_ 2566900261 FirstNdCntX_AnglRad_Cval 64;
BA_ "FlexKomSigStartPos" SG_ 2566900261 FirstNdCntX_AnglRad_Cval 7;
BA_ "FlexKomSID" SG_ 2566900261 FirstNdCntX_AnglRad_Cval 100677473;
BA_ "GenSigStartValue" SG_ 2566900261 FirstNdCntX_AnglRad_Cval 65535;
BA_ "FlexKomSigStartValue" SG_ 2566900261 FirstNdCntX_AnglRad_Cval "FF3FFFFFFFFFFFFFh";
BA_ "GenSigSendType" SG_ 2566900261 FirstNdCntX_AnglRad_Cval 1;
BA_ "GenSigSNA" SG_ 2566900261 SecNdCntX_AnglDeg_Cval "FFFFh";
BA_ "FlexKomIsMotorola" SG_ 2566900261 SecNdCntX_AnglDeg_Cval 1;
BA_ "FlexKomComment" SG_ 2566900261 SecNdCntX_AnglDeg_Cval "GVC Message 10 Packet";
BA_ "FlexKomSigName" SG_ 2566900261 SecNdCntX_AnglDeg_Cval "GVC10_Pkt";
BA_ "FlexKomSigLaenge" SG_ 2566900261 SecNdCntX_AnglDeg_Cval 64;
BA_ "FlexKomSigStartPos" SG_ 2566900261 SecNdCntX_AnglDeg_Cval 7;
BA_ "FlexKomSID" SG_ 2566900261 SecNdCntX_AnglDeg_Cval 100677473;
BA_ "GenSigStartValue" SG_ 2566900261 SecNdCntX_AnglDeg_Cval 65535;
BA_ "FlexKomSigStartValue" SG_ 2566900261 SecNdCntX_AnglDeg_Cval "FF3FFFFFFFFFFFFFh";
BA_ "GenSigSendType" SG_ 2566900261 SecNdCntX_AnglDeg_Cval 1;
BA_ "GenSigSNA" SG_ 2566900261 SecNdCntX_AnglRad_Cval "FFFFh";
BA_ "FlexKomIsMotorola" SG_ 2566900261 SecNdCntX_AnglRad_Cval 1;
BA_ "FlexKomComment" SG_ 2566900261 SecNdCntX_AnglRad_Cval "GVC Message 10 Packet";
BA_ "FlexKomSigName" SG_ 2566900261 SecNdCntX_AnglRad_Cval "GVC10_Pkt";
BA_ "FlexKomSigLaenge" SG_ 2566900261 SecNdCntX_AnglRad_Cval 64;
BA_ "FlexKomSigStartPos" SG_ 2566900261 SecNdCntX_AnglRad_Cval 7;
BA_ "FlexKomSID" SG_ 2566900261 SecNdCntX_AnglRad_Cval 100677473;
BA_ "GenSigStartValue" SG_ 2566900261 SecNdCntX_AnglRad_Cval 65535;
BA_ "FlexKomSigStartValue" SG_ 2566900261 SecNdCntX_AnglRad_Cval "FF3FFFFFFFFFFFFFh";
BA_ "GenSigSendType" SG_ 2566900261 SecNdCntX_AnglRad_Cval 1;
BA_ "GenSigStartValue" SG_ 2566905983 ECU_InternalTemperature 65278;
BA_ "GenSigStartValue" SG_ 2566906239 VehicleWidth 300;
BA_ "GenSigStartValue" SG_ 2566906239 CamLateralOffset 50;
BA_ "GenSigStartValue" SG_ 2566906239 NominalYaw 100;
BA_ "GenSigStartValue" SG_ 2566906239 NominalRoll 100;
BA_ "GenSigStartValue" SG_ 2566906239 NominalPitch 50;
BA_ "GenSigStartValue" SG_ 2566907007 SelfGlareActivity 3;
BA_ "GenSigStartValue" SG_ 2566907007 SelfGlareState 3;
BA_ "GenSigStartValue" SG_ 2566907007 BlindnessStatusHeat 3;
BA_ "GenSigStartValue" SG_ 2566907007 SelfGlareProbability 15;
BA_ "GenSigStartValue" SG_ 2566907007 BlindnessStatusGeneral 3;
BA_ "GenSigStartValue" SG_ 2566907007 BlindnessStatusLight 3;
BA_ "GenSigStartValue" SG_ 2566907007 BlindnessStatusPedestrian 3;
BA_ "GenSigStartValue" SG_ 2566907007 BlindnessStatusRoadsign 3;
BA_ "GenSigStartValue" SG_ 2566907007 BlindnessStatusVehicle 3;
BA_ "GenSigStartValue" SG_ 2566907007 BlindnessStatusLane 3;
BA_ "GenSigStartValue" SG_ 2566907007 StaticAbsoluteYaw 100;
BA_ "GenSigStartValue" SG_ 2566907007 StaticAbsoluteRoll 100;
BA_ "GenSigStartValue" SG_ 2566907007 StaticAbsolutePitch 50;
BA_ "GenSigStartValue" SG_ 2566907263 BlindnessProbabilityHeat 121;
BA_ "GenSigStartValue" SG_ 2566907263 BlindnessFreeSight 3;
BA_ "GenSigSNA" SG_ 2566907409 ADASIS_Cval_IPPC "FFh";
BA_ "FlexKomIsMotorola" SG_ 2566907409 ADASIS_Cval_IPPC 1;
BA_ "FlexKomComment" SG_ 2566907409 ADASIS_Cval_IPPC "ADASIS_IPPC_Pkt";
BA_ "FlexKomSigName" SG_ 2566907409 ADASIS_Cval_IPPC "ADASIS_IPPC_Pkt";
BA_ "FlexKomSigLaenge" SG_ 2566907409 ADASIS_Cval_IPPC 64;
BA_ "FlexKomSigStartPos" SG_ 2566907409 ADASIS_Cval_IPPC 7;
BA_ "FlexKomSID" SG_ 2566907409 ADASIS_Cval_IPPC 100675691;
BA_ "GenSigStartValue" SG_ 2566907409 ADASIS_Cval_IPPC 255;
BA_ "FlexKomSigStartValue" SG_ 2566907409 ADASIS_Cval_IPPC "FFFFFFFFFFFFFFFFh";
BA_ "GenSigSendType" SG_ 2566907409 ADASIS_Cval_IPPC 1;
BA_ "GenSigSNA" SG_ 2566907409 ADASIS2_Cval_IPPC "FFh";
BA_ "FlexKomIsMotorola" SG_ 2566907409 ADASIS2_Cval_IPPC 1;
BA_ "FlexKomComment" SG_ 2566907409 ADASIS2_Cval_IPPC "ADASIS_IPPC_Pkt";
BA_ "FlexKomSigName" SG_ 2566907409 ADASIS2_Cval_IPPC "ADASIS_IPPC_Pkt";
BA_ "FlexKomSigLaenge" SG_ 2566907409 ADASIS2_Cval_IPPC 64;
BA_ "FlexKomSigStartPos" SG_ 2566907409 ADASIS2_Cval_IPPC 7;
BA_ "FlexKomSID" SG_ 2566907409 ADASIS2_Cval_IPPC 100675691;
BA_ "GenSigStartValue" SG_ 2566907409 ADASIS2_Cval_IPPC 255;
BA_ "FlexKomSigStartValue" SG_ 2566907409 ADASIS2_Cval_IPPC "FFFFFFFFFFFFFFFFh";
BA_ "GenSigSendType" SG_ 2566907409 ADASIS2_Cval_IPPC 1;
BA_ "GenSigSNA" SG_ 2566907409 ADASIS3_Cval_IPPC "FFh";
BA_ "FlexKomIsMotorola" SG_ 2566907409 ADASIS3_Cval_IPPC 1;
BA_ "FlexKomComment" SG_ 2566907409 ADASIS3_Cval_IPPC "ADASIS_IPPC_Pkt";
BA_ "FlexKomSigName" SG_ 2566907409 ADASIS3_Cval_IPPC "ADASIS_IPPC_Pkt";
BA_ "FlexKomSigLaenge" SG_ 2566907409 ADASIS3_Cval_IPPC 64;
BA_ "FlexKomSigStartPos" SG_ 2566907409 ADASIS3_Cval_IPPC 7;
BA_ "FlexKomSID" SG_ 2566907409 ADASIS3_Cval_IPPC 100675691;
BA_ "GenSigStartValue" SG_ 2566907409 ADASIS3_Cval_IPPC 255;
BA_ "FlexKomSigStartValue" SG_ 2566907409 ADASIS3_Cval_IPPC "FFFFFFFFFFFFFFFFh";
BA_ "GenSigSendType" SG_ 2566907409 ADASIS3_Cval_IPPC 1;
BA_ "GenSigSNA" SG_ 2566907409 ADASIS4_Cval_IPPC "FFh";
BA_ "FlexKomIsMotorola" SG_ 2566907409 ADASIS4_Cval_IPPC 1;
BA_ "FlexKomComment" SG_ 2566907409 ADASIS4_Cval_IPPC "ADASIS_IPPC_Pkt";
BA_ "FlexKomSigName" SG_ 2566907409 ADASIS4_Cval_IPPC "ADASIS_IPPC_Pkt";
BA_ "FlexKomSigLaenge" SG_ 2566907409 ADASIS4_Cval_IPPC 64;
BA_ "FlexKomSigStartPos" SG_ 2566907409 ADASIS4_Cval_IPPC 7;
BA_ "FlexKomSID" SG_ 2566907409 ADASIS4_Cval_IPPC 100675691;
BA_ "GenSigStartValue" SG_ 2566907409 ADASIS4_Cval_IPPC 255;
BA_ "FlexKomSigStartValue" SG_ 2566907409 ADASIS4_Cval_IPPC "FFFFFFFFFFFFFFFFh";
BA_ "GenSigSendType" SG_ 2566907409 ADASIS4_Cval_IPPC 1;
BA_ "GenSigSNA" SG_ 2566907409 ADASIS5_Cval_IPPC "FFh";
BA_ "FlexKomIsMotorola" SG_ 2566907409 ADASIS5_Cval_IPPC 1;
BA_ "FlexKomComment" SG_ 2566907409 ADASIS5_Cval_IPPC "ADASIS_IPPC_Pkt";
BA_ "FlexKomSigName" SG_ 2566907409 ADASIS5_Cval_IPPC "ADASIS_IPPC_Pkt";
BA_ "FlexKomSigLaenge" SG_ 2566907409 ADASIS5_Cval_IPPC 64;
BA_ "FlexKomSigStartPos" SG_ 2566907409 ADASIS5_Cval_IPPC 7;
BA_ "FlexKomSID" SG_ 2566907409 ADASIS5_Cval_IPPC 100675691;
BA_ "GenSigStartValue" SG_ 2566907409 ADASIS5_Cval_IPPC 255;
BA_ "FlexKomSigStartValue" SG_ 2566907409 ADASIS5_Cval_IPPC "FFFFFFFFFFFFFFFFh";
BA_ "GenSigSendType" SG_ 2566907409 ADASIS5_Cval_IPPC 1;
BA_ "GenSigSNA" SG_ 2566907409 ADASIS6_Cval_IPPC "FFh";
BA_ "FlexKomIsMotorola" SG_ 2566907409 ADASIS6_Cval_IPPC 1;
BA_ "FlexKomComment" SG_ 2566907409 ADASIS6_Cval_IPPC "ADASIS_IPPC_Pkt";
BA_ "FlexKomSigName" SG_ 2566907409 ADASIS6_Cval_IPPC "ADASIS_IPPC_Pkt";
BA_ "FlexKomSigLaenge" SG_ 2566907409 ADASIS6_Cval_IPPC 64;
BA_ "FlexKomSigStartPos" SG_ 2566907409 ADASIS6_Cval_IPPC 7;
BA_ "FlexKomSID" SG_ 2566907409 ADASIS6_Cval_IPPC 100675691;
BA_ "GenSigStartValue" SG_ 2566907409 ADASIS6_Cval_IPPC 255;
BA_ "FlexKomSigStartValue" SG_ 2566907409 ADASIS6_Cval_IPPC "FFFFFFFFFFFFFFFFh";
BA_ "GenSigSendType" SG_ 2566907409 ADASIS6_Cval_IPPC 1;
BA_ "GenSigSNA" SG_ 2566907409 ADASIS7_Cval_IPPC "FFh";
BA_ "FlexKomIsMotorola" SG_ 2566907409 ADASIS7_Cval_IPPC 1;
BA_ "FlexKomComment" SG_ 2566907409 ADASIS7_Cval_IPPC "ADASIS_IPPC_Pkt";
BA_ "FlexKomSigName" SG_ 2566907409 ADASIS7_Cval_IPPC "ADASIS_IPPC_Pkt";
BA_ "FlexKomSigLaenge" SG_ 2566907409 ADASIS7_Cval_IPPC 64;
BA_ "FlexKomSigStartPos" SG_ 2566907409 ADASIS7_Cval_IPPC 7;
BA_ "FlexKomSID" SG_ 2566907409 ADASIS7_Cval_IPPC 100675691;
BA_ "GenSigStartValue" SG_ 2566907409 ADASIS7_Cval_IPPC 255;
BA_ "FlexKomSigStartValue" SG_ 2566907409 ADASIS7_Cval_IPPC "FFFFFFFFFFFFFFFFh";
BA_ "GenSigSendType" SG_ 2566907409 ADASIS7_Cval_IPPC 1;
BA_ "GenSigSNA" SG_ 2566907409 ADASIS8_Cval_IPPC "FFh";
BA_ "FlexKomIsMotorola" SG_ 2566907409 ADASIS8_Cval_IPPC 1;
BA_ "FlexKomComment" SG_ 2566907409 ADASIS8_Cval_IPPC "ADASIS_IPPC_Pkt";
BA_ "FlexKomSigName" SG_ 2566907409 ADASIS8_Cval_IPPC "ADASIS_IPPC_Pkt";
BA_ "FlexKomSigLaenge" SG_ 2566907409 ADASIS8_Cval_IPPC 64;
BA_ "FlexKomSigStartPos" SG_ 2566907409 ADASIS8_Cval_IPPC 7;
BA_ "FlexKomSID" SG_ 2566907409 ADASIS8_Cval_IPPC 100675691;
BA_ "GenSigStartValue" SG_ 2566907409 ADASIS8_Cval_IPPC 255;
BA_ "FlexKomSigStartValue" SG_ 2566907409 ADASIS8_Cval_IPPC "FFFFFFFFFFFFFFFFh";
BA_ "GenSigSendType" SG_ 2566907409 ADASIS8_Cval_IPPC 1;
BA_ "GenSigStartValue" SG_ 2566907775 BlindnessProbabilityGeneral 121;
BA_ "GenSigStartValue" SG_ 2566907775 BlindnessProbabilityLight 121;
BA_ "GenSigStartValue" SG_ 2566907775 BlindnessProbabilityPedestrian 121;
BA_ "GenSigStartValue" SG_ 2566907775 BlindnessProbabilityRoadsign 121;
BA_ "GenSigStartValue" SG_ 2566907775 BlindnessProbabilityVehicle 121;
BA_ "GenSigStartValue" SG_ 2566907775 BlindnessDominantCause 7;
BA_ "GenSigStartValue" SG_ 2566907775 BlindnessProbabilityLane 121;
BA_ "GenSigStartValue" SG_ 2566907775 BlindnessErrorState 7;
BA_ "GenSigStartValue" SG_ 2566908287 LaneColorTypeRight 7;
BA_ "GenSigStartValue" SG_ 2566908287 LaneColorTypeLeft 7;
BA_ "GenSigStartValue" SG_ 2566908543 IHC_Distance 255;
BA_ "GenSigStartValue" SG_ 2566908543 IHC_Angle 255;
BA_ "GenSigStartValue" SG_ 2566908543 IHC_DrivingDirection 2;
BA_ "GenSigStartValue" SG_ 2566908543 IHC_ObjectType 5;
BA_ "GenSigStartValue" SG_ 2566908799 RSF_SpeedLimit2FromMapTimeValid 2;
BA_ "GenSigStartValue" SG_ 2566909055 RSF_SpeedLimit2FromMapType 7;
BA_ "GenSigStartValue" SG_ 2566909055 RSF_SpeedLimit1FromMapTimeValid 2;
BA_ "GenSigStartValue" SG_ 2566909055 RSF_SpeedLimit2FromMapWeight 127;
BA_ "GenSigStartValue" SG_ 2566909055 RSF_SpeedLimit1FromMapWeight 127;
BA_ "GenSigStartValue" SG_ 2566909055 RSF_distOtkRestrictionFromMap 255;
BA_ "GenSigStartValue" SG_ 2566909055 RSF_distSpeedLimitFromMap 255;
BA_ "GenSigStartValue" SG_ 2566909311 NextClassifierIdx 5;
BA_ "GenSigStartValue" SG_ 2566909311 RSF_OtkRestrictionVehSpecific 3;
BA_ "GenSigStartValue" SG_ 2566909311 RSF_OtkRestrictionTimeSpecific 3;
BA_ "GenSigStartValue" SG_ 2566909311 RSF_OtkRestrictionCondition 15;
BA_ "GenSigStartValue" SG_ 2566909311 RSF_SpeedLimit2FromMapWeather 6;
BA_ "GenSigStartValue" SG_ 2566909311 RSF_SpeedLimit2FromMapHazGoods 6;
BA_ "GenSigStartValue" SG_ 2566909311 RSF_SpeedLimit1FromMapWeather 6;
BA_ "GenSigStartValue" SG_ 2566909311 RSF_SpeedLimit1FromMapHazGoods 6;
BA_ "GenSigStartValue" SG_ 2566909311 RSF_SpeedLimit1FromMapType 7;
BA_ "GenSigStartValue" SG_ 2566909311 ExposureTimeRatio23 3;
BA_ "GenSigStartValue" SG_ 2566909311 ExposureTimeRatio12 3;
BA_ "GenSigStartValue" SG_ 2566909311 CamAlignErr 3;
BA_ "GenSigStartValue" SG_ 2566909311 WheelBase 255;
BA_ "GenSigStartValue" SG_ 2566909311 CameraToRadar 255;
BA_ "GenSigStartValue" SG_ 2566909311 CameraToFrontAxle 255;
BA_ "GenSigStartValue" SG_ 2566909567 dacore_redcalc_checker 1;
BA_ "GenSigStartValue" SG_ 2566909567 tramo_redcalc_checker 1;
BA_ "GenSigStartValue" SG_ 2566909567 lbdctrl_redcalc_checker 1;
BA_ "GenSigStartValue" SG_ 2566909567 lbd_redcalc_checker 1;
BA_ "GenSigStartValue" SG_ 2566909567 flowpa_redcalc_checker 1;
BA_ "GenSigStartValue" SG_ 2566909567 valcfg_redcalc_checker 1;
BA_ "GenSigStartValue" SG_ 2566909567 OnlineAdditionalYaw 100;
BA_ "GenSigStartValue" SG_ 2566909567 OnlineAdditionalRoll 100;
BA_ "GenSigStartValue" SG_ 2566909567 OnlineAdditionalPitch 100;
BA_ "GenSigStartValue" SG_ 2566909567 IHC_VelocityRange 1;
BA_ "GenSigStartValue" SG_ 2566909567 IHC_Mode 1;
BA_ "GenSigStartValue" SG_ 2566909823 ADASIS_Cval_BuiltUpArea 2;
BA_ "GenSigStartValue" SG_ 2566909823 ADASIS_Cval_DividedRoad 2;
BA_ "GenSigStartValue" SG_ 2566909823 ADASIS_Cval_Tunnel 2;
VAL_ 2432639615 AnglLt_VehObj2_Cval_MPC 65535 "SNA" ;
VAL_ 2432639615 AnglRt_VehObj2_Cval_MPC 65535 "SNA" ;
VAL_ 2432639615 SclFctr_VehObj2_Cval_MPC 65535 "SNA" ;
VAL_ 2432639871 AnglLt_VehObj3_Cval_MPC 65535 "SNA" ;
VAL_ 2432639871 AnglRt_VehObj3_Cval_MPC 65535 "SNA" ;
VAL_ 2432639871 SclFctr_VehObj3_Cval_MPC 65535 "SNA" ;
VAL_ 2498756875 ABS_Actv_Stat 3 "SNA" 2 "RES" 1 "ACTIVE" 0 "PASSIVE" ;
VAL_ 2498756875 BrkPdlPosn_Cval 255 "SNA" 254 "ERR" ;
VAL_ 2499696943 RelLvlFAxL_Cval 65280 "SNA_MIN" 65280 "ERR_MAX" 65024 "ERR_MIN" 65023 "RES_MAX" 64256 "RES_MIN" 65535 "SNA_MAX" ;
VAL_ 2499696943 RelLvlFAxR_Cval 65280 "SNA_MIN" 65280 "ERR_MAX" 65024 "ERR_MIN" 65023 "RES_MAX" 64256 "RES_MIN" 65535 "SNA_MAX" ;
VAL_ 2499696943 RelLvlRAxL_Cval 65280 "SNA_MIN" 65280 "ERR_MAX" 65024 "ERR_MIN" 65023 "RES_MAX" 64256 "RES_MIN" 65535 "SNA_MAX" ;
VAL_ 2499696943 RelLvlRAxR_Cval 65280 "SNA_MIN" 65280 "ERR_MAX" 65024 "ERR_MIN" 65023 "RES_MAX" 64256 "RES_MIN" 65535 "SNA_MAX" ;
VAL_ 2499702539 RoadCurv_Cval 65535 "SNA" ;
VAL_ 2499735808 VehSpd_Cval_CPC 65280 "SNA_MIN" 65280 "ERR_MAX" 65024 "ERR_MIN" 65023 "RES_MAX" 64256 "RES_MIN" 65535 "SNA_MAX" ;
VAL_ 2499735808 CC_Actv_Stat 3 "SNA" 2 "RES" 1 "ON" 0 "OFF" ;
VAL_ 2499739775 DispCloAA_Rq_MPC 3 "SNA" 2 "RED" 1 "YEL" 0 "GRN" ;
VAL_ 2499739775 Lvl0_AA_Cval_MPC 15 "SNA" ;
VAL_ 2499739775 Lvl1_AA_Cval_MPC 15 "SNA" ;
VAL_ 2499739775 Lvl2_AA_Cval_MPC 15 "SNA" ;
VAL_ 2499739775 Lvl3_AA_Cval_MPC 15 "SNA" ;
VAL_ 2499739775 Lvl4_AA_Cval_MPC 15 "SNA" ;
VAL_ 2499739775 Lvl5_AA_Cval_MPC 15 "SNA" ;
VAL_ 2499739775 Lvl6_AA_Cval_MPC 15 "SNA" ;
VAL_ 2499739775 Lvl7_AA_Cval_MPC 15 "SNA" ;
VAL_ 2499739775 Lvl8_AA_Cval_MPC 15 "SNA" ;
VAL_ 2499739775 Lvl9_AA_Cval_MPC 15 "SNA" ;
VAL_ 2499739775 AA_Enbl_Stat_MPC 3 "SNA" 2 "ERR" 1 "ENBL" 0 "DSABL" ;
VAL_ 2499739775 AA_Fkt_Stat_MPC 3 "SNA" 2 "FAIL" 1 "COMP" 0 "IDL" ;
VAL_ 2499739775 Warn0_AA_Rq_MPC 3 "SNA" 2 "ERR" 1 "ON" 0 "OFF" ;
VAL_ 2499739775 Warn1_AA_Rq_MPC 3 "SNA" 2 "ERR" 1 "ON" 0 "OFF" ;
VAL_ 2499739915 ROP_EngCtrlActv2_Stat 3 "SNA" 2 "ERR" 1 "ACTIVE" 0 "PASSIVE" ;
VAL_ 2499739915 ROP_BrkCtrlActv2_Stat 3 "SNA" 2 "RES" 1 "ACTIVE" 0 "PASSIVE" ;
VAL_ 2499739915 YC_EngCtrlActv2_Stat 3 "SNA" 2 "RES" 1 "ACTIVE" 0 "PASSIVE" ;
VAL_ 2499739915 YC_BrkCtrlActv2_Stat 3 "SNA" 2 "RES" 1 "ACTIVE" 0 "PASSIVE" ;
VAL_ 2499739915 TrlrEstm_Stat_BS 3 "SNA" 2 "ERR" 1 "DTCT" 0 "NOTDTCT" ;
VAL_ 2499739953 TurnSglSwLt_Rq 3 "SNA" 2 "ERR" 1 "ACT" 0 "DACT" ;
VAL_ 2499739953 TurnSglSwRt_Rq 3 "SNA" 2 "ERR" 1 "ACT" 0 "DACT" ;
VAL_ 2499739953 WprSw_Rq 15 "SNA" 14 "ERR" 7 "HIGH" 6 "LOW" 5 "INT5" 4 "INT4" 3 "INT3" 2 "INT2" 1 "INT1_AUTO" 0 "OFF" ;
VAL_ 2499739953 LDW_Sw_Rq 3 "SNA" 2 "ERR" 1 "PSD" 0 "NPSD" ;
VAL_ 2499740031 SftyMonLaneLt_Stat_MPC 3 "SNA" 2 "RES" 1 "VER" 0 "NVER" ;
VAL_ 2499740031 SftyMonLaneRt_Stat_MPC 3 "SNA" 2 "RES" 1 "VER" 0 "NVER" ;
VAL_ 2499740031 LaneRangeLt_Cval_MPC 255 "SNA" 254 "ERR" ;
VAL_ 2499740031 LaneRangeRt_Cval_MPC 255 "SNA" 254 "ERR" ;
VAL_ 2499740031 LaneCrvtrChgLt_Cval_MPC 65535 "SNA" ;
VAL_ 2499740031 LaneCrvtrChgRt_Cval_MPC 65535 "SNA" ;
VAL_ 2499740648 DrvDirec_Stat_VRDU 3 "SNA" 2 "FWD" 1 "STNDSTL" 0 "BWD" ;
VAL_ 2499740648 ABA_DistWarn_Stat 3 "SNA" 2 "ERR" 1 "WARN" 0 "NWARN" ;
VAL_ 2499740648 ALA_Stat 3 "SNA" 2 "ACTV" 1 "PASSV" 0 "OFF" ;
VAL_ 2499740904 WhlBaseTrtr_Cval 255 "SNA" 254 "ERR" ;
VAL_ 2499742976 RetSwPos_Rq_STSR 255 "SNV" 254 "ERROR" 5 "POS5" 4 "POS4" 3 "POS3" 2 "POS2" 1 "POS1" 0 "POS0" ;
VAL_ 2566809216 BatMainSw_Stat 3 "SNA" 2 "RES" 1 "HLD" 0 "NHLD" ;
VAL_ 2566841879 DateTmSecond_Cval_ICUC 255 "SNA" 254 "ERR" ;
VAL_ 2566841879 DateTmMinute_Cval_ICUC 255 "SNA" ;
VAL_ 2566841879 DateTmHour_Cval_ICUC 255 "SNA" ;
VAL_ 2566841879 DateTmMonth_Cval_ICUC 255 "SNA" 0 "RES" ;
VAL_ 2566841879 DateTmDay_Cval_ICUC 255 "SNA" 254 "ERR" 0 "RES1" ;
VAL_ 2566841879 DateTmYear_Cval_ICUC 255 "SNA" ;
VAL_ 2566841879 LocalMinuteOffset_Cval_ICUC 255 "SNA" 254 "ERR" ;
VAL_ 2566841879 LocalHourOffset_Cval_ICUC 255 "SNA" 254 "ERR" ;
VAL_ 2566845201 Latitude_Cval_IPPC -16777216 "SNA_MIN" -16777217 "ERR_MAX" -33554432 "ERR_MIN" -33554433 "RES_MAX" -83886080 "RES_MIN" -1 "SNA_MAX" ;
VAL_ 2566845201 Longitude_Cval_IPPC -16777216 "SNA_MIN" -16777217 "ERR_MAX" -33554432 "ERR_MIN" -33554433 "RES_MAX" -83886080 "RES_MIN" -1 "SNA_MAX" ;
VAL_ 2566845729 AirTempOutsd_Cval_SCA 65535 "SNA" ;
VAL_ 2566848549 Offboard_Tester_Stat 3 "SNA" 2 "ERR" 1 "CON" 0 "NCON" ;
VAL_ 2566848549 SelfHealing2_Stat 255 "SNA" ;
VAL_ 2566848549 SelfHealing3_Stat 255 "SNA" ;
VAL_ 2566848549 TotalVehDist_Cval_DIAG -2147483648 "SNA" ;
VAL_ 2566848791 TSR_MdSw_Rq 3 "SNA" 2 "ERR" 1 "PSD" 0 "NPSD" ;
VAL_ 2566848895 TrafSign1_MPC 255 "SNA" 0 "EMPTY" ;
VAL_ 2566848895 TrafSign2_MPC 255 "SNA" 0 "EMPTY" ;
VAL_ 2566848895 SuppSign1_MPC 255 "SNA" 0 "EMPTY" ;
VAL_ 2566848895 SuppSign2_MPC 255 "SNA" 0 "EMPTY" ;
VAL_ 2566848895 TrafSignSpd_Unit_MPC 3 "SNA" 2 "mph" 1 "kmph" 0 "NONE" ;
VAL_ 2566848895 TrafSignIcon_Set_MPC 15 "SNA" ;
VAL_ 2566848895 SpdLimWarn_Rq_MPC 3 "SNA" 2 "WARN2" 1 "WARN1" 0 "NWARN" ;
VAL_ 2566848895 NoPassWarn_Rq_MPC 3 "SNA" 2 "WARN2" 1 "WARN1" 0 "NWARN" ;
VAL_ 2566848895 TSR_Func_Stat_MPC 15 "SNA" 14 "ERR" 5 "VISION_ONLY_LIM" 4 "FUSION" 3 "MAP_ONLY" 2 "VISION_ONLY" 1 "INIT" 0 "OFF" ;
VAL_ 2566848895 WrongWayWarn_Rq_MPC 3 "SNA" 2 "WARN2" 1 "WARN1" 0 "NWARN" ;
VAL_ 2566848895 TrafSign3_MPC 255 "SNA" 0 "EMPTY" ;
VAL_ 2566848895 TrafSign4_MPC 255 "SNA" 0 "EMPTY" ;
VAL_ 2566849047 AA_Stat_ICUC 3 "SNA" 2 "ERR" 1 "ENBL" 0 "DSABL" ;
VAL_ 2566849047 LDWS_FailWarnDev_Stat_ICUC 15 "SNA" 14 "ERR" 3 "ERR_BOTH" 2 "ERR_RIGHT" 1 "ERR_LEFT" 0 "NO_ERR" ;
VAL_ 2566849151 VidCapVideoID_MPC2 255 "SNA" 0 "RES" ;
VAL_ 2566849151 SuppSign3_MPC 255 "SNA" 0 "EMPTY" ;
VAL_ 2566849151 SuppSign4_MPC 255 "SNA" 0 "EMPTY" ;
VAL_ 2566849151 VehSpdLim_Rq_MPC 65535 "SNA" 64256 "NO_SPD" ;
VAL_ 2566849151 VidCapFileAvl_Stat_MPC2 3 "SNA" 2 "ERR" 1 "AVL" 0 "NAVL" ;
VAL_ 2566849151 PassingMvreEstm_Stat_MPC 3 "SNA" 2 "PASSDTCT" 1 "NOTDTCT" 0 "UNKNOWN" ;
VAL_ 2566850337 RainSensOpMod_Stat 3 "SNA" 2 "RES" 1 "IACT" 0 "RACT" ;
VAL_ 2566850337 RainSensSensitivity_Stat 15 "SNA" 5 "LEV5" 4 "LEV4" 3 "LEV3" 2 "LEV2" 1 "LEV1" 0 "OFF" ;
VAL_ 2566850378 VidCapPreTrigLength 255 "SNA" ;
VAL_ 2566850378 VidCapLength 255 "SNA" ;
VAL_ 2566850378 VidCapLabel 255 "SNA" 0 "RES" ;
VAL_ 2566850378 VidCapRec_Stat 3 "SNA" 2 "ERR" 1 "ACT" 0 "NACT" ;
VAL_ 2566850378 VidFileTrf_Stat 3 "SNA" 2 "TRFCOMP" 1 "TRF" 0 "NTRF" ;
VAL_ 2566850593 WprSpd_Stat 3 "SNA" 2 "HSPD" 1 "LSPD" 0 "NACT" ;
VAL_ 2566851873 LDWS_FailWarnDev_Stat_SAM 15 "SNA" 14 "ERR" 3 "ERR_BOTH" 2 "ERR_Right" 1 "ERR_LEFT" 0 "NOERR" ;
VAL_ 2566860172 LDWS_FailWarnDev_Stat_MUX3 15 "SNA" 14 "ERR" 3 "ERR_BOTH" 2 "ERR_RIGHT" 1 "ERR_LEFT" 0 "NO_ERR" ;
VAL_ 2566881280 NM_Mode 255 "SNA" 254 "ALIVE" 253 "RING" 252 "LHOM" ;
VAL_ 2566881280 NM_Successor 255 "SNA" ;
VAL_ 2566881280 NM_Ud_Launch 63 "SNA" 4 "BROADCAST" ;
VAL_ 2566881280 NM_Ud_Srv 255 "SNA" 19 "AWAKE_BC_IC" 18 "AWAKE_BC_ASAM_MBT" 17 "AWAKE_BC_SSAM_NGC" 16 "AWAKE_BC_SSAM_MBT" 15 "AWAKE_BC" 8 "WAKE_UP_IC" 7 "WAKE_UP_ASAM_MBT" 6 "WAKEUP_SA_SSAM_NGC" 5 "SBC_STAT_BC" 4 "WAKEUP_SA_MUX" 3 "WAKEUP_SA_SSAM_MBT" 2 "WAKEUP_SA" 1 "DATA_OK_BC" 0 "RES" ;
VAL_ 2566881280 WakeupRsn_MPC 255 "SNA" 0 "NETWORK" ;
VAL_ 2566881280 WakeupCnt_cv 255 "SNA" ;
VAL_ 2566881280 Nw_Id 255 "SNA" 200 "J1708" 10 "HYBRID" 9 "HVAC" 8 "TP_1" 7 "PT_1" 6 "ASSISTANCE" 5 "J1939" 4 "EXTERIOR" 3 "CHASSIS" 2 "CABIN" 1 "DIAGNOSTICS" 0 "RES" ;
VAL_ 2566897701 GVC_VehBrand 15 "SNA" 14 "RES10" 13 "RES9" 12 "RES8" 11 "RES7" 10 "RES6" 9 "RES5" 8 "RES4" 7 "ON_HW_PP" 6 "WS" 5 "MTU" 4 "FUSO" 3 "FTL" 2 "UM" 1 "DAIBUS" 0 "MB" ;
VAL_ 2566897701 GVC_VehModel 15 "SNA" 14 "RES9" 13 "RES8" 12 "RES7" 11 "BFUSO" 10 "PP" 9 "BCHAS" 8 "BSETR" 7 "BMERC" 6 "FBV" 5 "MV" 4 "ST" 3 "CM" 2 "DT" 1 "RES" 0 "FBT" ;
VAL_ 2566897957 GVC_HdLmpType 15 "SNA" 3 "HdLmpType_Matrix" 2 "HdLmpType_LED" 1 "HdLmpType_BiXen" 0 "HdLmpType_Hal" ;
VAL_ 2566897957 GVC_TrackWidth 255 "SNA" 254 "ERR" ;
VAL_ 2566897957 GVC_WhlBase 65535 "SNA" ;
VAL_ 2566897957 GVC_LgtSens 3 "SNA" 2 "RES" 1 "AVL" 0 "NA" ;
VAL_ 2566898469 GVC_LDW_Func 15 "SNA" 4 "LRDA" 3 "RDA" 2 "SAF" 1 "LDW" 0 "NA" ;
VAL_ 2566898469 GVC_D_AttenMonFunc 3 "SNA" 2 "MDAS" 1 "AA_Bus" 0 "NA" ;
VAL_ 2566898469 GVC_IHC_Func 3 "SNA" 2 "IHC_F" 1 "IHC_L" 0 "NA" ;
VAL_ 2566899237 GVC_SysMsg_IPPC 3 "SNA" 2 "RES" 1 "AVL" 0 "ECU_NA" ;
VAL_ 2566899237 VMM_VersionYear_Cval 255 "SNA" ;
VAL_ 2566899237 VMM_VersionWeek_Cval 255 "SNA" 254 "ERR" ;
VAL_ 2566899493 GVC_TSR_Fct 15 "SNA" 1 "TSR" 0 "NA" ;
VAL_ 2566899749 VIN_Seg 255 "SNA" 0 "ERR" ;
VAL_ 2566899749 VIN_Seg2 255 "SNA" 0 "ERR" ;
VAL_ 2566899749 VIN_Seg3 255 "SNA" 0 "ERR" ;
VAL_ 2566899749 VIN_Seg4 255 "SNA" 0 "ERR" ;
VAL_ 2566899749 VIN_Seg5 255 "SNA" 0 "ERR" ;
VAL_ 2566899749 VIN_Seg6 255 "SNA" 0 "ERR" ;
VAL_ 2566899749 VIN_Seg7 255 "SNA" 0 "ERR" ;
VAL_ 2566900261 SteerRatioCntr_Cval 255 "SNA" ;
VAL_ 2566900261 SteerRatioNodesCntr_Cval 15 "SNA" ;
VAL_ 2566900261 SteerRatioAnglType_Stat 3 "SNA" 2 "Reserved" 1 "WHL_ANGL" 0 "STEER_ANGL" ;
VAL_ 2566900261 SteerRatioMS_Stat 3 "SNA" 2 "Reserved" 1 "RAD" 0 "DEG" ;
VAL_ 2566900261 FirstNdCntX_SteerRatio_Cval 255 "SNA" 254 "ERR" ;
VAL_ 2566900261 SecNdCntX_SteerRatio_Cval 255 "SNA" 254 "ERR" ;
VAL_ 2566900261 FirstNdCntX_AnglDeg_Cval 65535 "SNA" ;
VAL_ 2566900261 FirstNdCntX_AnglRad_Cval 65535 "SNA" ;
VAL_ 2566900261 SecNdCntX_AnglDeg_Cval 65535 "SNA" ;
VAL_ 2566900261 SecNdCntX_AnglRad_Cval 65535 "SNA" ;
VAL_ 2566905983 ECU_InternalTemperature 65278 "SNA" ;
VAL_ 2566907007 ExposureTimeT1 1023 "SNA" ;
VAL_ 2566907007 SelfGlareActivity 3 "GLARE_ERROR" 1 "GLARE_INACTIVE" 0 "GLARE_ACTIVE" ;
VAL_ 2566907007 SelfGlareState 3 "UNKNOWN" 1 "GLARE" 0 "NO_GLARE" ;
VAL_ 2566907007 SelfGlareProbability 15 "GLARE_ERROR_INACTIVE" ;
VAL_ 2566908543 IHC_Distance 255 "SNA" ;
VAL_ 2566908543 IHC_Angle 255 "SNA" ;
VAL_ 2566908543 IHC_DrivingDirection 2 "UNKNOWN" 1 "PRECEDING" 0 "ONCOMING" ;
VAL_ 2566908543 IHC_ObjectType 5 "UNKNOWN" 4 "PEDESTRIAN" 3 "BICYCLE" 2 "MOTORBIKE" 1 "TRUCK" 0 "CAR" ;
VAL_ 2566908543 IHC_DetectionState 1 "Detected" 0 "NOT_Detected" ;
VAL_ 2566908799 RSF_SpeedLimit2VariableSpeedSign 1 "VMS_YES" 0 "VMS_NO" ;
VAL_ 2566908799 RSF_SpeedLimit2FromMapTimeValid 3 "N/A" 2 "TV_UNKNOWN" 1 "TV_YES" 0 "TV_NO" ;
VAL_ 2566908799 RSF_SpeedLimit2DisplaySource 3 "FUSION OR BOTH" 2 "NAVIGATION" 1 "VIDEO" 0 "UNKNOWN" ;
VAL_ 2566908799 RSF_SpeedLimit1VariableSpeedSign 1 "VMS_YES" 0 "VMS_NO" ;
VAL_ 2566908799 RSF_SpeedLimit1FromMapTimeDepend 1 "TD_YES" 0 "TD_NO" ;
VAL_ 2566908799 RSF_OverSpeedWarningStatus 1 "WARN" 0 "NWARN" ;
VAL_ 2566908799 RSF_OtkRestrictionWarningStatus 1 "WARN" 0 "NWARN" ;
VAL_ 2566908799 RSF_OtkRestrictionFromMap 1 "OTK_YES" 0 "OTK_NO" ;
VAL_ 2566908799 RSF_SpeedLimit1DisplaySource 3 "FUSION OR BOTH" 2 "NAVIGATION" 1 "VIDEO" 0 "UNKNOWN" ;
VAL_ 2566908799 RSF_SpeedLimit1FusionStrategy 4 "SLSRC_MATCH" 3 "SLSRC_MAP" 2 "SLSRC_VISUAL_MOD" 1 "SLSRC_VISUAL_PURE" 0 "SLSRC_UNKNOWN" ;
VAL_ 2566908799 RSF_OtkRestrictionDisplaySource 3 "FUSION OR BOTH" 2 "NAVIGATION" 1 "VIDEO" 0 "UNKNOWN" ;
VAL_ 2566908799 RSF_OtkRestrictionDetected 1 "OTK_YES" 0 "OTK_NO" ;
VAL_ 2566908799 RSF_OtkFusionStrategy 4 "OTK_MATCH" 3 "OTK_MAP" 2 "OTK_VISUAL_MOD" 1 "OTK_VISUAL_PURE" 0 "OTK_UNKNOWN" ;
VAL_ 2566908799 RSF_LastDetectedQuality 2 "HIGH_QUALITY" 1 "LOW_QUALITY" 0 "UNKNOWN" ;
VAL_ 2566909055 RSF_SpeedLimit2FusionStrategy 4 "SLSRC_MATCH" 3 "SLSRC_MAP" 2 "SLSRC_VISUAL_MOD" 1 "SLSRC_VISUAL_PURE" 0 "SLSRC_UNKNOWN" ;
VAL_ 2566909055 RSF_SpeedLimit2FromMapType 7 "LMT_UNKNOWN" 6 "LMT_SNOW" 5 "LMT_RAIN" 4 "LMT_TIME" 3 "LMT_BY_DAY" 2 "LMT_BY_NIGHT" 1 "LMT_EXPLICIT" 0 "LMT_IMPLICIT" ;
VAL_ 2566909055 RSF_SpeedLimit1FromMapTimeValid 3 "N/A" 2 "TV_UNKNOWN" 1 "TV_YES" 0 "TV_NO" ;
VAL_ 2566909055 RSF_SpeedLimit2FromMapWeight 127 "N/A" ;
VAL_ 2566909055 RSF_SpeedLimit1FromMapWeight 127 "N/A" ;
VAL_ 2566909055 RSF_distOtkRestrictionFromMap 255 "UNKNOWN" 254 "MAP_NA" 253 "VIDEO_NA" ;
VAL_ 2566909055 RSF_distSpeedLimitFromMap 255 "UNKNOWN" 254 "MAP_NA" 253 "VIDEO_NA" ;
VAL_ 2566909311 NextClassifierIdx 5 " SNA " 4 " DAY2SPRAY" 3 " SPRAY" 2 " NIGHT" 1 " DAY" 0 "NO_CLASSIFIER" ;
VAL_ 2566909311 RSF_SpeedLimit2FromMapTimeDepend 1 "TD_YES" 0 "TD_NO" ;
VAL_ 2566909311 RSF_SpeedLimit2FromMapWeather 7 "N/A" 6 "WR_UNKNOWN" 5 "RES2" 4 "RES1" 3 "WR_RAIN" 2 "WR_FOG" 1 "WR_SNOW" 0 "WR_NO" ;
VAL_ 2566909311 RSF_SpeedLimit2FromMapHazGoods 7 "N/A" 6 "HG_UNKNOWN" 5 "RES3" 4 "RES2" 3 "RES1" 2 "HG_HARM_WATER" 1 "HG_EXPLOSIVE" 0 "HG_ALL" ;
VAL_ 2566909311 RSF_SpeedLimit1FromMapWeather 7 "N/A" 6 "WR_UNKNOWN" 5 "RES2" 4 "RES1" 3 "WR_RAIN" 2 "WR_FOG" 1 "WR_SNOW" 0 "WR_NO" ;
VAL_ 2566909311 RSF_SpeedLimit1FromMapHazGoods 7 "N/A" 6 "HG_UNKNOWN" 5 "RES3" 4 "RES2" 3 "RES1" 2 "HG_HARM_WATER" 1 "HG_EXPLOSIVE" 0 "HG_ALL" ;
VAL_ 2566909311 RSF_SpeedLimit1FromMapType 7 "LMT_UNKNOWN" 6 "LMT_SNOW" 5 "LMT_RAIN" 4 "LMT_TIME" 3 "LMT_BY_DAY" 2 "LMT_BY_NIGHT" 1 "LMT_EXPLICIT" 0 "LMT_IMPLICIT" ;
VAL_ 2566909567 IHC_HighBrightness 1 "HIGHBRIGHTNESS" 0 "NO_HIGHBRIGHTNESS" ;
VAL_ 2566909567 IHC_VelocityRange 2 "VELOCITY_TOO_HIGH" 1 "VELOCITY_OPERATIONAL" 0 "VELOCITY_TOO_LOW" ;
VAL_ 2566909567 IHC_Mode 2 "IHC_FULL" 1 "IHC_LIGHT" 0 "DISABLED" ;
VAL_ 2566909567 IHC_Blindness 1 "BLINDNESS" 0 "NO_BLINDNESS" ;
VAL_ 2566909567 IHC_RoadLighting 1 "ROADLIGHTING" 0 "NO_ROADLIGHTING" ;
VAL_ 2566909567 IHC_SelfGlaring 1 "GLARE" 0 "NO_GLARE" ;
VAL_ 2566909823 ADASIS_Cval_BuiltUpArea 3 "BUILTUP_NA" 2 "BUILTUP_UNKNOWN" 1 "BUILTUP_YES" 0 "BUILTUP_NO" ;
VAL_ 2566909823 ADASIS_Cval_FuncRoadClass 7 "N/A" 6 "RC_CLASS_6" 5 "RC_CLASS_5" 4 "RC_CLASS_4" 3 "RC_CLASS_3 " 2 "RC_CLASS_2" 1 "RC_CLASS_1 " 0 "UNKNOWN" ;
VAL_ 2566909823 ADASIS_Cval_DividedRoad 3 "DR_NA" 2 "DR_UNKNOWN" 1 "DR_YES" 0 "DR_NO" ;
VAL_ 2566909823 ADASIS_Cval_Tunnel 3 "TUNNEL_NA" 2 "TUNNEL_UNKNOWN" 1 "TUNNEL_YES" 0 "TUNNEL_NO" ;
VAL_ 2566909823 ADASIS_Cval_FormOfWay 15 "RF_NA" 14 "RF_PED_ZONE" 13 "RF_LINK_SERVICE" 12 "RF_LINK_PARK" 11 "RF_SERVICE" 10 "RF_SLIP" 9 "RF_SLIP_FREEWAY" 8 "RF_PARALLEL" 7 "RF_RESERVED2" 6 "RF_RESERVED1" 5 "RF_TRAFFIC_FIGURE" 4 "RF_ROUNDABOUT" 3 "RF_CRRGWAY_SINGLE" 2 "RF_CRRGWAY_MULTIPLE" 1 "RF_FREEWAY" 0 "RF_UNKNOWN" ;
